VERSION ""

NS_ :

BS_:

BU_: WCM4 WCM3 WCM2 WCM VPM VLM VKM VICM VECM VDM VCU_RTOS_ETH VCU_ENTRY_ETH VCU_AGVM_ETH VCU UVM UPM TIM TEST_TOOL_1 TCP_ETH TCP TCM TCCM SRR_SRR_ETH SRR_SRR SRR_SLR_ETH SRR_SLR SRR_RR SRR_RF_ETH SRR_RF SRR_LR_CR SRR_LF_ETH SRR_LF SIB SDM SCL SBZA_R SBZA_L SBM SAM_RR SAM_RF SAM_LR SAM_LF SAM_BH SADS RadioLow_ETH RadioLow RSI_RTOS_ETH RSI RDCM PTM PLCM PFCM PDR_ETH PDR PCM PA ODS2 ODS NVM MTCM_R MTCM_L MSM_RR MSM_P MSM_LR MSM_D MSB2 MSB1 MRCM_R MRCM_L MFC LRR_RR_ETH LRR_LR_ETH LRR_CF_ETH LRR LRL_CF_ETH LIB_48V LIB1 IPC_INT IPC_GP IPC ICS_Info ICCM HVAC_FP_R HVAC_FP_F HUD_CAN HDLM FPI_RTOS_ETH FPI FOPM FCM_LC FCM EPSb EPS_1 EPSRAb EPSRAa EPS EOCM_HC_Superset EOCM_HCP2 EOCM ELM ECP_X1 ECP_S2 ECP_S ECP_MC ECP_H3 ECP_H2 ECP_H1 ECP_E ECM EBCM DMS DEFC DCM CSM_ETH CSM_AV CSM CGM_OTA_ETH CGM BSM_MH BSM_HEV BSM BCM ARS ARB APA AOS AMP ALC AHS AHL_AFL ADIMb ADIMa ACP2_MCU

BO_ 1345 PDU_9219: 8 CGM
 SG_ EVSECmndPwrLim : 7|16@0+ (0.1,0) [0|6553.5] "KW" CSM,IPC,IPC_INT,VCU
 SG_ HiVltgChrgReqdPwrLim : 23|16@0+ (0.1,0) [0|6553.5] "KW" CSM,IPC,IPC_INT,VCU
 SG_ EVSECmndPwrLimSts : 32|3@0+ (1,0) [0|3] "" CSM,IPC,IPC_INT,VCU
 SG_ EVSECmndPwrLimCpbltyPct : 39|7@0+ (1,0) [0|127] "%" CSM,IPC,IPC_INT,VCU
 SG_ DrSeltdOtltOfPwMdVirCtlNAlwdSts : 42|3@0+ (1,0) [0|6] "" VCU
 SG_ ShfFromNeutWrnIndOn : 43|1@0+ (1,0) [0|1] "" IPC,IPC_INT,VCU
 SG_ NeutCstdwnCertModeWrnIndOn : 44|1@0+ (1,0) [0|1] "" IPC,IPC_INT,VCU
 SG_ EVSECmndPwrLimAval : 45|1@0+ (1,0) [0|1] "" CSM,IPC,IPC_INT,VCU
 SG_ OnbrdOtlt1OprtlSts : 50|3@0+ (1,0) [0|4] "" VCU
 SG_ OffbrdOtltsOvrloadIndOn : 51|1@0+ (1,0) [0|1] "" VCU
 SG_ DrvrSeltdOtltOffPwrMdVirCtlAvl : 52|1@0+ (1,0) [0|1] "" VCU
 SG_ DrvrSeltdOtltOffPwMdVirCtlAllwd : 53|1@0+ (1,0) [0|1] "" VCU
 SG_ DrSeltdOtltOffPwMdVirCtlSeltnVl : 55|2@0+ (1,0) [0|2] "" VCU
 SG_ OtltsOffPwrMdTmrActv : 56|1@0+ (1,0) [0|1] "" VCU
 SG_ OnbrdOtltsOvrloadIndOn : 57|1@0+ (1,0) [0|1] "" VCU
 SG_ OnbrdOtlt3OprtlSts : 60|3@0+ (1,0) [0|4] "" VCU
 SG_ OnbrdOtlt2OprtlSts : 63|3@0+ (1,0) [0|4] "" VCU

BO_ 1294 PDU_9221: 8 CGM
 SG_ SecRowLtPsStBltRmOccpSts : 1|2@0+ (1,0) [0|2] "" TCP,VCU
 SG_ SecRowCntrPsStBltSts_Inv : 2|1@0+ (1,0) [0|1] "" TCP
 SG_ SecRowCntrPsStBltSts : 4|2@0+ (1,0) [0|2] "" TCP
 SG_ SecRowCntrPsStBltRmOccpSts_Inv : 5|1@0+ (1,0) [0|1] "" TCP,VCU
 SG_ SecRowCntrPsStBltRmOccpSts : 7|2@0+ (1,0) [0|2] "" TCP,VCU
 SG_ SecRowRtPsStBltSts : 8|2@0+ (1,0) [0|2] "" TCP
 SG_ SecRowRtPsStBltRmOccpSts_Inv : 9|1@0+ (1,0) [0|1] "" TCP,VCU
 SG_ SecRowRtPsStBltRmOccpSts : 11|2@0+ (1,0) [0|2] "" TCP,VCU
 SG_ SecRowLtPsStBltSts_Inv : 12|1@0+ (1,0) [0|1] "" TCP
 SG_ SecRowLtPsStBltSts : 14|2@0+ (1,0) [0|2] "" TCP
 SG_ SecRowLtPsStBltRmOccpSts_Inv : 15|1@0+ (1,0) [0|1] "" TCP,VCU
 SG_ ThrdRowCntrPsStBltSts_Inv : 16|1@0+ (1,0) [0|1] "" TCP
 SG_ ThrdRowCntrPsStBltSts : 18|2@0+ (1,0) [0|2] "" TCP
 SG_ ThrdRowCntrPsStBltRmOccpSts_Inv : 19|1@0+ (1,0) [0|1] "" TCP,VCU
 SG_ ThrdRowCntrPsStBltRmOccpSts : 21|2@0+ (1,0) [0|2] "" TCP,VCU
 SG_ SecRowRtPsStBltSts_Inv : 22|1@0+ (1,0) [0|1] "" TCP
 SG_ ThrdRowRtPsStBltRmOccpSts : 25|2@0+ (1,0) [0|2] "" TCP,VCU
 SG_ ThrdRowLtPsStBltSts_Inv : 26|1@0+ (1,0) [0|1] "" TCP
 SG_ ThrdRowLtPsStBltSts : 28|2@0+ (1,0) [0|2] "" TCP
 SG_ ThrdRowLtPsStBltRmOccpSts_Inv : 29|1@0+ (1,0) [0|1] "" TCP,VCU
 SG_ ThrdRowLtPsStBltRmOccpSts : 31|2@0+ (1,0) [0|2] "" TCP,VCU
 SG_ ThrdRowRtPsStBltSts_Inv : 36|1@0+ (1,0) [0|1] "" TCP
 SG_ ThrdRowRtPsStBltSts : 38|2@0+ (1,0) [0|2] "" TCP
 SG_ ThrdRowRtPsStBltRmOccpSts_Inv : 39|1@0+ (1,0) [0|1] "" TCP,VCU

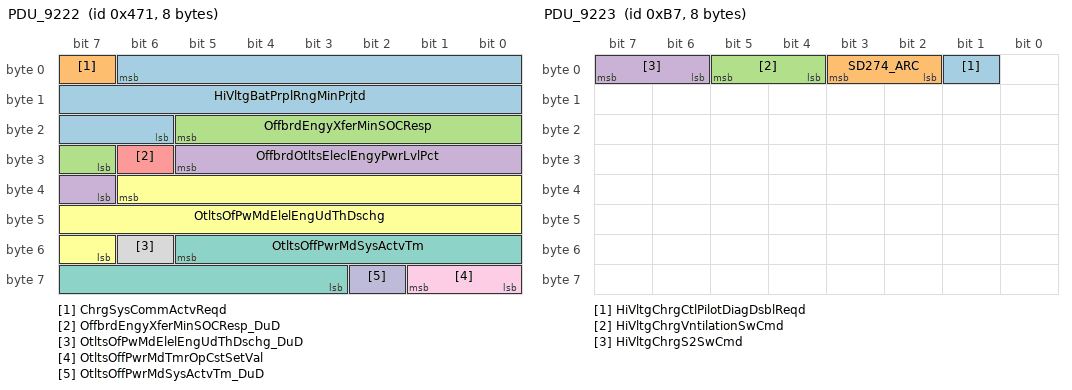
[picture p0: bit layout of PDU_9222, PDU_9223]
BO_ 1137 PDU_9222: 8 CGM
 SG_ HiVltgBatPrplRngMinPrjtd : 6|17@0+ (0.015625,0) [0|2047.98] "km" VCU
 SG_ ChrgSysCommActvReqd : 7|1@0+ (1,0) [0|1] "" PLCM
 SG_ OffbrdEngyXferMinSOCResp : 21|7@0+ (1,0) [0|127] "%" VCU
 SG_ OffbrdOtltsEleclEngyPwrLvlPct : 29|7@0+ (1,0) [0|127] "%" VCU
 SG_ OffbrdEngyXferMinSOCResp_DuD : 30|1@0+ (1,0) [0|1] "" VCU
 SG_ OtltsOfPwMdElelEngUdThDschg : 38|16@0+ (0.01,0) [0|655.35] "kWh" VCU
 SG_ OtltsOffPwrMdSysActvTm : 53|11@0+ (1,0) [0|2047] "min" VCU
 SG_ OtltsOfPwMdElelEngUdThDschg_DuD : 54|1@0+ (1,0) [0|1] "" VCU
 SG_ OtltsOffPwrMdTmrOpCstSetVal : 57|2@0+ (1,0) [0|2] "" VCU
 SG_ OtltsOffPwrMdSysActvTm_DuD : 58|1@0+ (1,0) [0|1] "" VCU

BO_ 183 PDU_9223: 8 CGM
 SG_ HiVltgChrgCtlPilotDiagDsblReqd : 1|1@0+ (1,0) [0|1] "" PLCM
 SG_ SD274_ARC : 3|2@0+ (1,0) [0|3] "" PLCM
 SG_ HiVltgChrgVntilationSwCmd : 5|2@0+ (1,0) [0|2] "" PLCM
 SG_ HiVltgChrgS2SwCmd : 7|2@0+ (1,0) [0|2] "" PLCM

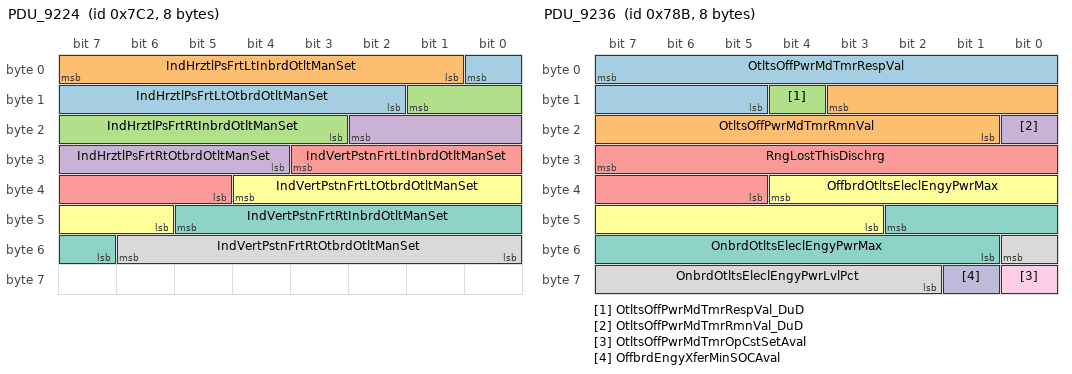
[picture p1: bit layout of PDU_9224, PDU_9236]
BO_ 1986 PDU_9224: 8 CGM
 SG_ IndHrztlPsFrtLtOtbrdOtltManSet : 0|7@0+ (1,0) [0|127] "" VCU
 SG_ IndHrztlPsFrtLtInbrdOtltManSet : 7|7@0+ (1,0) [0|127] "" VCU
 SG_ IndHrztlPsFrtRtInbrdOtltManSet : 9|7@0+ (1,0) [0|127] "" VCU
 SG_ IndHrztlPsFrtRtOtbrdOtltManSet : 18|7@0+ (1,0) [0|127] "" VCU
 SG_ IndVertPstnFrtLtInbrdOtltManSet : 27|7@0+ (1,0) [0|127] "" VCU
 SG_ IndVertPstnFrtLtOtbrdOtltManSet : 36|7@0+ (1,0) [0|127] "" VCU
 SG_ IndVertPstnFrtRtInbrdOtltManSet : 45|7@0+ (1,0) [0|127] "" VCU
 SG_ IndVertPstnFrtRtOtbrdOtltManSet : 54|7@0+ (1,0) [0|127] "" VCU

BO_ 1931 PDU_9236: 8 CGM
 SG_ OtltsOffPwrMdTmrRespVal : 7|11@0+ (1,0) [0|2047] "min" VCU
 SG_ OtltsOffPwrMdTmrRmnVal : 11|11@0+ (1,0) [0|2047] "min" VCU
 SG_ OtltsOffPwrMdTmrRespVal_DuD : 12|1@0+ (1,0) [0|1] "" VCU
 SG_ OtltsOffPwrMdTmrRmnVal_DuD : 16|1@0+ (1,0) [0|1] "" VCU
 SG_ RngLostThisDischrg : 31|11@0+ (1,0) [0|2047] "km" VCU
 SG_ OffbrdOtltsEleclEngyPwrMax : 36|10@0+ (0.1,0) [0|102.3] "kW" VCU
 SG_ OnbrdOtltsEleclEngyPwrMax : 42|10@0+ (0.1,0) [0|102.3] "kW" VCU
 SG_ OnbrdOtltsEleclEngyPwrLvlPct : 48|7@0+ (1,0) [0|127] "%" VCU
 SG_ OtltsOffPwrMdTmrOpCstSetAval : 56|1@0+ (1,0) [0|1] "" VCU
 SG_ OffbrdEngyXferMinSOCAval : 57|1@0+ (1,0) [0|1] "" VCU

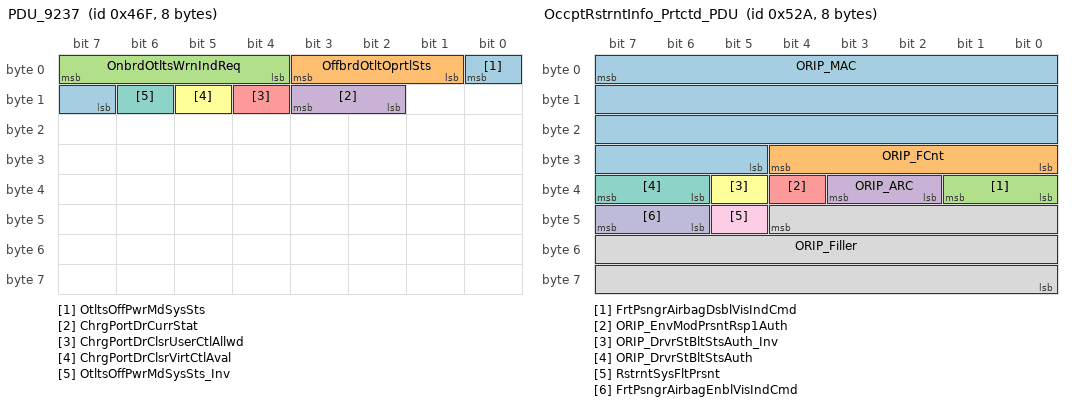
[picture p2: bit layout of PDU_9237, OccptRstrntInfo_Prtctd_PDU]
BO_ 1135 PDU_9237: 8 CGM
 SG_ OtltsOffPwrMdSysSts : 0|2@0+ (1,0) [0|3] "" VCU
 SG_ OffbrdOtltOprtlSts : 3|3@0+ (1,0) [0|4] "" VCU
 SG_ OnbrdOtltsWrnIndReq : 7|4@0+ (1,0) [0|8] "" VCU
 SG_ ChrgPortDrCurrStat : 11|2@0+ (1,0) [0|2] "" VCU
 SG_ ChrgPortDrClsrUserCtlAllwd : 12|1@0+ (1,0) [0|1] "" VCU
 SG_ ChrgPortDrClsrVirtCtlAval : 13|1@0+ (1,0) [0|1] "" VCU
 SG_ OtltsOffPwrMdSysSts_Inv : 14|1@0+ (1,0) [0|1] "" VCU

BO_ 1056 PDU_9259: 8 CGM
 SG_ CntnsCrnkgDsbldIndOn : 7|1@0+ (1,0) [0|1] "" VCU

BO_ 963 NodeStatus_CAN5_PDU01: 8 CGM
 SG_ NodeStsADIMb_CAN_9_LcFA : 0|1@0+ (1,0) [0|1] "" AMP,FPI,HVAC_FP_F,HVAC_FP_R,ICS_Info,PDR,MFC,PLCM,RSI,RadioLow,TCP,VKM,CSM,CSM_AV,IPC,IPC_INT,VCU,WCM,WCM2,WCM3,WCM4
 SG_ NodeStsADIMb_CAN_3_LcFA : 1|1@0+ (1,0) [0|1] "" AMP,FPI,HVAC_FP_F,HVAC_FP_R,ICS_Info,PDR,MFC,PLCM,RSI,RadioLow,TCP,VKM,CSM,CSM_AV,IPC,IPC_INT,VCU,WCM,WCM2,WCM3,WCM4
 SG_ NodeStsADIMb_CAN_2_LcFA : 2|1@0+ (1,0) [0|1] "" AMP,FPI,HVAC_FP_F,HVAC_FP_R,ICS_Info,PDR,MFC,PLCM,RSI,RadioLow,TCP,VKM,CSM,CSM_AV,IPC,IPC_INT,VCU,WCM,WCM2,WCM3,WCM4
 SG_ NodeStsADIMb_CAN_10_LcFA : 3|1@0+ (1,0) [0|1] "" AMP,FPI,HVAC_FP_F,HVAC_FP_R,ICS_Info,PDR,MFC,PLCM,RSI,RadioLow,TCP,VKM,CSM,CSM_AV,IPC,IPC_INT,VCU,WCM,WCM2,WCM3,WCM4
 SG_ NodeStsADIMa_CAN_9_LcFA : 4|1@0+ (1,0) [0|1] "" AMP,FPI,HVAC_FP_F,HVAC_FP_R,ICS_Info,PDR,MFC,PLCM,RSI,RadioLow,TCP,VKM,CSM,CSM_AV,IPC,IPC_INT,VCU,WCM,WCM2,WCM3,WCM4
 SG_ NodeStsADIMa_CAN_3_LcFA : 5|1@0+ (1,0) [0|1] "" AMP,FPI,HVAC_FP_F,HVAC_FP_R,ICS_Info,PDR,MFC,PLCM,RSI,RadioLow,TCP,VKM,CSM,CSM_AV,IPC,IPC_INT,VCU,WCM,WCM2,WCM3,WCM4
 SG_ NodeStsADIMa_CAN_2_LcFA : 6|1@0+ (1,0) [0|1] "" AMP,FPI,HVAC_FP_F,HVAC_FP_R,ICS_Info,PDR,MFC,PLCM,RSI,RadioLow,TCP,VKM,CSM,CSM_AV,IPC,IPC_INT,VCU,WCM,WCM2,WCM3,WCM4
 SG_ NodeStsADIMa_CAN_10_LcFA : 7|1@0+ (1,0) [0|1] "" AMP,FPI,HVAC_FP_F,HVAC_FP_R,ICS_Info,PDR,MFC,PLCM,RSI,RadioLow,TCP,VKM,CSM,CSM_AV,IPC,IPC_INT,VCU,WCM,WCM2,WCM3,WCM4
 SG_ NodeStsAPA_CAN_1_LcFA : 8|1@0+ (1,0) [0|1] "" AMP,FPI,HVAC_FP_F,HVAC_FP_R,ICS_Info,PDR,MFC,PLCM,RSI,RadioLow,TCP,VKM,CSM,CSM_AV,IPC,IPC_INT,VCU,WCM,WCM2,WCM3,WCM4
 SG_ NodeStsAOS_LcFA : 10|1@0+ (1,0) [0|1] "" AMP,FPI,HVAC_FP_F,HVAC_FP_R,ICS_Info,PDR,MFC,PLCM,RSI,RadioLow,TCP,VKM,CSM,CSM_AV,IPC,IPC_INT,VCU,WCM,WCM2,WCM3,WCM4
 SG_ NodeStsAMP_LcFA : 11|1@0+ (1,0) [0|1] "" FPI,HVAC_FP_F,HVAC_FP_R,ICS_Info,PDR,MFC,PLCM,RSI,RadioLow,TCP,VKM,CSM,CSM_AV,IPC,IPC_INT,VCU,WCM,WCM2,WCM3,WCM4
 SG_ NodeStsALC_LcFA : 12|1@0+ (1,0) [0|1] "" AMP,FPI,HVAC_FP_F,HVAC_FP_R,ICS_Info,PDR,MFC,PLCM,RSI,RadioLow,TCP,VKM,CSM,CSM_AV,IPC,IPC_INT,VCU,WCM,WCM2,WCM3,WCM4
 SG_ NodeStsAHS_LcFA : 13|1@0+ (1,0) [0|1] "" AMP,FPI,HVAC_FP_F,HVAC_FP_R,ICS_Info,PDR,MFC,PLCM,RSI,RadioLow,TCP,VKM,CSM,CSM_AV,IPC,IPC_INT,VCU,WCM,WCM2,WCM3,WCM4
 SG_ NodeStsAHL_AFL_CAN_2_LcFA : 14|1@0+ (1,0) [0|1] "" AMP,FPI,HVAC_FP_F,HVAC_FP_R,ICS_Info,PDR,MFC,PLCM,RSI,RadioLow,TCP,VKM,CSM,CSM_AV,IPC,IPC_INT,VCU,WCM,WCM2,WCM3,WCM4
 SG_ NodeStsBSM_MH_LcFA : 17|1@0+ (1,0) [0|1] "" AMP,FPI,HVAC_FP_F,HVAC_FP_R,ICS_Info,PDR,MFC,PLCM,RSI,RadioLow,TCP,VKM,CSM,CSM_AV,IPC,IPC_INT,VCU,WCM,WCM2,WCM3,WCM4
 SG_ NodeStsBSM_CAN_3_LcFA : 18|1@0+ (1,0) [0|1] "" AMP,FPI,HVAC_FP_F,HVAC_FP_R,ICS_Info,PDR,MFC,PLCM,RSI,RadioLow,TCP,VKM,CSM,CSM_AV,IPC,IPC_INT,VCU,WCM,WCM2,WCM3,WCM4
 SG_ NodeStsBSM_CAN_2_LcFA : 19|1@0+ (1,0) [0|1] "" AMP,FPI,HVAC_FP_F,HVAC_FP_R,ICS_Info,PDR,MFC,PLCM,RSI,RadioLow,TCP,VKM,CSM,CSM_AV,IPC,IPC_INT,VCU,WCM,WCM2,WCM3,WCM4
 SG_ NodeStsBCM_LcFA : 20|1@0+ (1,0) [0|1] "" AMP,FPI,HVAC_FP_F,HVAC_FP_R,ICS_Info,PDR,MFC,PLCM,RSI,RadioLow,TCP,VKM,CSM,CSM_AV,IPC,IPC_INT,VCU,WCM,WCM2,WCM3,WCM4
 SG_ NodeStsARS_LcFA : 21|1@0+ (1,0) [0|1] "" AMP,FPI,HVAC_FP_F,HVAC_FP_R,ICS_Info,PDR,MFC,PLCM,RSI,RadioLow,TCP,VKM,CSM,CSM_AV,IPC,IPC_INT,VCU,WCM,WCM2,WCM3,WCM4
 SG_ NodeStsARB_LcFA : 22|1@0+ (1,0) [0|1] "" AMP,FPI,HVAC_FP_F,HVAC_FP_R,ICS_Info,PDR,MFC,PLCM,RSI,RadioLow,TCP,VKM,CSM,CSM_AV,IPC,IPC_INT,VCU,WCM,WCM2,WCM3,WCM4
 SG_ NodeStsAPA_CAN_2_LcFA : 23|1@0+ (1,0) [0|1] "" AMP,FPI,HVAC_FP_F,HVAC_FP_R,ICS_Info,PDR,MFC,PLCM,RSI,RadioLow,TCP,VKM,CSM,CSM_AV,IPC,IPC_INT,VCU,WCM,WCM2,WCM3,WCM4
 SG_ NodeStsEBCM_AV_CAN_2_LcFA : 24|1@0+ (1,0) [0|1] "" AMP,FPI,HVAC_FP_F,HVAC_FP_R,ICS_Info,PDR,MFC,PLCM,RSI,RadioLow,TCP,VKM,CSM,CSM_AV,IPC,IPC_INT,VCU,WCM,WCM2,WCM3,WCM4
 SG_ NodeStsDMS_LcFA : 25|1@0+ (1,0) [0|1] "" AMP,FPI,HVAC_FP_F,HVAC_FP_R,ICS_Info,PDR,MFC,PLCM,RSI,RadioLow,TCP,VKM,CSM,CSM_AV,IPC,IPC_INT,VCU,WCM,WCM2,WCM3,WCM4
 SG_ NodeStsDEFC_LcFA : 26|1@0+ (1,0) [0|1] "" AMP,FPI,HVAC_FP_F,HVAC_FP_R,ICS_Info,PDR,MFC,PLCM,RSI,RadioLow,TCP,VKM,CSM,CSM_AV,IPC,IPC_INT,VCU,WCM,WCM2,WCM3,WCM4
 SG_ NodeStsDCM_LcFA : 27|1@0+ (1,0) [0|1] "" AMP,FPI,HVAC_FP_F,HVAC_FP_R,ICS_Info,PDR,MFC,PLCM,RSI,RadioLow,TCP,VKM,CSM,CSM_AV,IPC,IPC_INT,VCU,WCM,WCM2,WCM3,WCM4
 SG_ NodeStsCSM_CAN_5_LcFA : 28|1@0+ (1,0) [0|1] "" AMP,FPI,HVAC_FP_F,HVAC_FP_R,ICS_Info,PDR,MFC,PLCM,RSI,RadioLow,TCP,VKM,CSM_AV,IPC,IPC_INT,VCU,WCM,WCM2,WCM3,WCM4
 SG_ NodeStsECP_E_CAN_9_LcFA : 32|1@0+ (1,0) [0|1] "" AMP,FPI,HVAC_FP_F,HVAC_FP_R,ICS_Info,PDR,MFC,PLCM,RSI,RadioLow,TCP,VKM,CSM,CSM_AV,IPC,IPC_INT,VCU,WCM,WCM2,WCM3,WCM4
 SG_ NodeStsECP_E_CAN_2_LcFA : 33|1@0+ (1,0) [0|1] "" AMP,FPI,HVAC_FP_F,HVAC_FP_R,ICS_Info,PDR,MFC,PLCM,RSI,RadioLow,TCP,VKM,CSM,CSM_AV,IPC,IPC_INT,VCU,WCM,WCM2,WCM3,WCM4
 SG_ NodeStsECM_CAN_3_LcFA : 34|1@0+ (1,0) [0|1] "" AMP,FPI,HVAC_FP_F,HVAC_FP_R,ICS_Info,PDR,MFC,PLCM,RSI,RadioLow,TCP,VKM,CSM,CSM_AV,IPC,IPC_INT,VCU,WCM,WCM2,WCM3,WCM4
 SG_ NodeStsECM_CAN_2_LcFA : 35|1@0+ (1,0) [0|1] "" AMP,FPI,HVAC_FP_F,HVAC_FP_R,ICS_Info,PDR,MFC,PLCM,RSI,RadioLow,TCP,VKM,CSM,CSM_AV,IPC,IPC_INT,VCU,WCM,WCM2,WCM3,WCM4
 SG_ NodeStsEBCM_CAN_3_LcFA : 37|1@0+ (1,0) [0|1] "" AMP,FPI,HVAC_FP_F,HVAC_FP_R,ICS_Info,PDR,MFC,PLCM,RSI,RadioLow,TCP,VKM,CSM,CSM_AV,IPC,IPC_INT,VCU,WCM,WCM2,WCM3,WCM4
 SG_ NodeStsEBCM_CAN_2_LcFA : 38|1@0+ (1,0) [0|1] "" AMP,FPI,HVAC_FP_F,HVAC_FP_R,ICS_Info,PDR,MFC,PLCM,RSI,RadioLow,TCP,VKM,CSM,CSM_AV,IPC,IPC_INT,VCU,WCM,WCM2,WCM3,WCM4
 SG_ NodeStsEBCM_AV_CAN_3_LcFA : 39|1@0+ (1,0) [0|1] "" AMP,FPI,HVAC_FP_F,HVAC_FP_R,ICS_Info,PDR,MFC,PLCM,RSI,RadioLow,TCP,VKM,CSM,CSM_AV,IPC,IPC_INT,VCU,WCM,WCM2,WCM3,WCM4
 SG_ NodeStsEOCM_CAN_3_LcFA : 40|1@0+ (1,0) [0|1] "" AMP,FPI,HVAC_FP_F,HVAC_FP_R,ICS_Info,PDR,MFC,PLCM,RSI,RadioLow,TCP,VKM,CSM,CSM_AV,IPC,IPC_INT,VCU,WCM,WCM2,WCM3,WCM4
 SG_ NodeStsEOCM_CAN_2_LcFA : 41|1@0+ (1,0) [0|1] "" AMP,FPI,HVAC_FP_F,HVAC_FP_R,ICS_Info,PDR,MFC,PLCM,RSI,RadioLow,TCP,VKM,CSM,CSM_AV,IPC,IPC_INT,VCU,WCM,WCM2,WCM3,WCM4
 SG_ NodeStsELM_LcFA : 42|1@0+ (1,0) [0|1] "" AMP,FPI,HVAC_FP_F,HVAC_FP_R,ICS_Info,PDR,MFC,PLCM,RSI,RadioLow,TCP,VKM,CSM,CSM_AV,IPC,IPC_INT,VCU,WCM,WCM2,WCM3,WCM4
 SG_ NodeStsECP_X1_CAN_3_LcFA : 43|1@0+ (1,0) [0|1] "" AMP,FPI,HVAC_FP_F,HVAC_FP_R,ICS_Info,PDR,MFC,PLCM,RSI,RadioLow,TCP,VKM,CSM,CSM_AV,IPC,IPC_INT,VCU,WCM,WCM2,WCM3,WCM4
 SG_ NodeStsECP_X1_CAN_2_LcFA : 44|1@0+ (1,0) [0|1] "" AMP,FPI,HVAC_FP_F,HVAC_FP_R,ICS_Info,PDR,MFC,PLCM,RSI,RadioLow,TCP,VKM,CSM,CSM_AV,IPC,IPC_INT,VCU,WCM,WCM2,WCM3,WCM4
 SG_ NodeStsECP_S_CAN_9_LcFA : 45|1@0+ (1,0) [0|1] "" AMP,FPI,HVAC_FP_F,HVAC_FP_R,ICS_Info,PDR,MFC,PLCM,RSI,RadioLow,TCP,VKM,CSM,CSM_AV,IPC,IPC_INT,VCU,WCM,WCM2,WCM3,WCM4
 SG_ NodeStsECP_S_CAN_2_LcFA : 46|1@0+ (1,0) [0|1] "" AMP,FPI,HVAC_FP_F,HVAC_FP_R,ICS_Info,PDR,MFC,PLCM,RSI,RadioLow,TCP,VKM,CSM,CSM_AV,IPC,IPC_INT,VCU,WCM,WCM2,WCM3,WCM4
 SG_ NodeStsECP_MC_LcFA : 47|1@0+ (1,0) [0|1] "" AMP,FPI,HVAC_FP_F,HVAC_FP_R,ICS_Info,PDR,MFC,PLCM,RSI,RadioLow,TCP,VKM,CSM,CSM_AV,IPC,IPC_INT,VCU,WCM,WCM2,WCM3,WCM4
 SG_ NodeStsEPSRAa_LcFA : 48|1@0+ (1,0) [0|1] "" AMP,FPI,HVAC_FP_F,HVAC_FP_R,ICS_Info,PDR,MFC,PLCM,RSI,RadioLow,TCP,VKM,CSM,CSM_AV,IPC,IPC_INT,VCU,WCM,WCM2,WCM3,WCM4
 SG_ NodeStsEPS_LcFA : 49|1@0+ (1,0) [0|1] "" AMP,FPI,HVAC_FP_F,HVAC_FP_R,ICS_Info,PDR,MFC,PLCM,RSI,RadioLow,TCP,VKM,CSM,CSM_AV,IPC,IPC_INT,VCU,WCM,WCM2,WCM3,WCM4
 SG_ NodeStsEPS_1_LcFA : 50|1@0+ (1,0) [0|1] "" AMP,FPI,HVAC_FP_F,HVAC_FP_R,ICS_Info,PDR,MFC,PLCM,RSI,RadioLow,TCP,VKM,CSM,CSM_AV,IPC,IPC_INT,VCU,WCM,WCM2,WCM3,WCM4
 SG_ NodeStsEOCM_HCP2_LcFA : 51|1@0+ (1,0) [0|1] "" AMP,FPI,HVAC_FP_F,HVAC_FP_R,ICS_Info,PDR,MFC,PLCM,RSI,RadioLow,TCP,VKM,CSM,CSM_AV,IPC,IPC_INT,VCU,WCM,WCM2,WCM3,WCM4
 SG_ NodeStsEOCM_HCP1_CAN_8_LcFA : 52|1@0+ (1,0) [0|1] "" AMP,FPI,HVAC_FP_F,HVAC_FP_R,ICS_Info,PDR,MFC,PLCM,RSI,RadioLow,TCP,VKM,CSM,CSM_AV,IPC,IPC_INT,VCU,WCM,WCM2,WCM3,WCM4
 SG_ NodeStsEOCM_HCP1_CAN_3_LcFA : 53|1@0+ (1,0) [0|1] "" AMP,FPI,HVAC_FP_F,HVAC_FP_R,ICS_Info,PDR,MFC,PLCM,RSI,RadioLow,TCP,VKM,CSM,CSM_AV,IPC,IPC_INT,VCU,WCM,WCM2,WCM3,WCM4
 SG_ NodeStsEOCM_HCP1_CAN_2_LcFA : 54|1@0+ (1,0) [0|1] "" AMP,FPI,HVAC_FP_F,HVAC_FP_R,ICS_Info,PDR,MFC,PLCM,RSI,RadioLow,TCP,VKM,CSM,CSM_AV,IPC,IPC_INT,VCU,WCM,WCM2,WCM3,WCM4
 SG_ NodeStsEOCM_CAN_8_LcFA : 55|1@0+ (1,0) [0|1] "" AMP,FPI,HVAC_FP_F,HVAC_FP_R,ICS_Info,PDR,MFC,PLCM,RSI,RadioLow,TCP,VKM,CSM,CSM_AV,IPC,IPC_INT,VCU,WCM,WCM2,WCM3,WCM4
 SG_ NodeStsHVAC_FP_F_LcFA : 56|1@0+ (1,0) [0|1] "" AMP,FPI,HVAC_FP_R,ICS_Info,PDR,MFC,PLCM,RSI,RadioLow,TCP,VKM,CSM,CSM_AV,IPC,IPC_INT,VCU,WCM,WCM2,WCM3,WCM4
 SG_ NodeStsHUD_CAN_LcFA : 57|1@0+ (1,0) [0|1] "" AMP,FPI,HVAC_FP_F,HVAC_FP_R,ICS_Info,PDR,MFC,PLCM,RSI,RadioLow,TCP,VKM,CSM,CSM_AV,IPC,IPC_INT,VCU,WCM,WCM2,WCM3,WCM4
 SG_ NodeStsHDLM_LcFA : 58|1@0+ (1,0) [0|1] "" AMP,FPI,HVAC_FP_F,HVAC_FP_R,ICS_Info,PDR,MFC,PLCM,RSI,RadioLow,TCP,VKM,CSM,CSM_AV,IPC,IPC_INT,VCU,WCM,WCM2,WCM3,WCM4
 SG_ NodeStsFOPM_CAN_3_LcFA : 59|1@0+ (1,0) [0|1] "" AMP,FPI,HVAC_FP_F,HVAC_FP_R,ICS_Info,PDR,MFC,PLCM,RSI,RadioLow,TCP,VKM,CSM,CSM_AV,IPC,IPC_INT,VCU,WCM,WCM2,WCM3,WCM4
 SG_ NodeStsFOPM_CAN_2_LcFA : 60|1@0+ (1,0) [0|1] "" AMP,FPI,HVAC_FP_F,HVAC_FP_R,ICS_Info,PDR,MFC,PLCM,RSI,RadioLow,TCP,VKM,CSM,CSM_AV,IPC,IPC_INT,VCU,WCM,WCM2,WCM3,WCM4
 SG_ NodeStsFCM_LcFA : 61|1@0+ (1,0) [0|1] "" AMP,FPI,HVAC_FP_F,HVAC_FP_R,ICS_Info,PDR,MFC,PLCM,RSI,RadioLow,TCP,VKM,CSM,CSM_AV,IPC,IPC_INT,VCU,WCM,WCM2,WCM3,WCM4
 SG_ NodeStsFCM_LC_LcFA : 62|1@0+ (1,0) [0|1] "" AMP,FPI,HVAC_FP_F,HVAC_FP_R,ICS_Info,PDR,MFC,PLCM,RSI,RadioLow,TCP,VKM,CSM,CSM_AV,IPC,IPC_INT,VCU,WCM,WCM2,WCM3,WCM4
 SG_ NodeStsEPSRAb_LcFA : 63|1@0+ (1,0) [0|1] "" AMP,FPI,HVAC_FP_F,HVAC_FP_R,ICS_Info,PDR,MFC,PLCM,RSI,RadioLow,TCP,VKM,CSM,CSM_AV,IPC,IPC_INT,VCU,WCM,WCM2,WCM3,WCM4

BO_ 964 NodeStatus_CAN5_PDU02: 8 CGM
 SG_ NodeStsMFC_LcFA : 0|1@0+ (1,0) [0|1] "" AMP,FPI,HVAC_FP_F,HVAC_FP_R,ICS_Info,PDR,PLCM,RSI,RadioLow,TCP,VKM,CSM,CSM_AV,IPC,IPC_INT,VCU,WCM,WCM2,WCM3,WCM4
 SG_ NodeStsLRR_LcFA : 1|1@0+ (1,0) [0|1] "" AMP,FPI,HVAC_FP_F,HVAC_FP_R,ICS_Info,PDR,MFC,PLCM,RSI,RadioLow,TCP,VKM,CSM,CSM_AV,IPC,IPC_INT,VCU,WCM,WCM2,WCM3,WCM4
 SG_ NodeStsLIB1_LcFA : 3|1@0+ (1,0) [0|1] "" AMP,FPI,HVAC_FP_F,HVAC_FP_R,ICS_Info,PDR,MFC,PLCM,RSI,RadioLow,TCP,VKM,CSM,CSM_AV,IPC,IPC_INT,VCU,WCM,WCM2,WCM3,WCM4
 SG_ NodeStsIPC_CAN_5_LcFA : 4|1@0+ (1,0) [0|1] "" AMP,FPI,HVAC_FP_F,HVAC_FP_R,ICS_Info,PDR,MFC,PLCM,RSI,RadioLow,TCP,VKM,CSM,CSM_AV,IPC,IPC_INT,VCU,WCM,WCM2,WCM3,WCM4
 SG_ NodeStsICS_Info_LcFA : 5|1@0+ (1,0) [0|1] "" AMP,FPI,HVAC_FP_F,HVAC_FP_R,PDR,MFC,PLCM,RSI,RadioLow,TCP,VKM,CSM,CSM_AV,IPC,IPC_INT,VCU,WCM,WCM2,WCM3,WCM4
 SG_ NodeStsICCM_CAN_3_LcFA : 6|1@0+ (1,0) [0|1] "" AMP,FPI,HVAC_FP_F,HVAC_FP_R,ICS_Info,PDR,MFC,PLCM,RSI,RadioLow,TCP,VKM,CSM,CSM_AV,IPC,IPC_INT,VCU,WCM,WCM2,WCM3,WCM4
 SG_ NodeStsHVAC_FP_R_LcFA : 7|1@0+ (1,0) [0|1] "" AMP,FPI,HVAC_FP_F,ICS_Info,PDR,MFC,PLCM,RSI,RadioLow,TCP,VKM,CSM,CSM_AV,IPC,IPC_INT,VCU,WCM,WCM2,WCM3,WCM4
 SG_ NodeStsMSM_RR_LcFA : 8|1@0+ (1,0) [0|1] "" AMP,FPI,HVAC_FP_F,HVAC_FP_R,ICS_Info,PDR,MFC,PLCM,RSI,RadioLow,TCP,VKM,CSM,CSM_AV,IPC,IPC_INT,VCU,WCM,WCM2,WCM3,WCM4
 SG_ NodeStsMSM_P_LcFA : 9|1@0+ (1,0) [0|1] "" AMP,FPI,HVAC_FP_F,HVAC_FP_R,ICS_Info,PDR,MFC,PLCM,RSI,RadioLow,TCP,VKM,CSM,CSM_AV,IPC,IPC_INT,VCU,WCM,WCM2,WCM3,WCM4
 SG_ NodeStsMSM_LR_LcFA : 10|1@0+ (1,0) [0|1] "" AMP,FPI,HVAC_FP_F,HVAC_FP_R,ICS_Info,PDR,MFC,PLCM,RSI,RadioLow,TCP,VKM,CSM,CSM_AV,IPC,IPC_INT,VCU,WCM,WCM2,WCM3,WCM4
 SG_ NodeStsMSM_D_LcFA : 11|1@0+ (1,0) [0|1] "" AMP,FPI,HVAC_FP_F,HVAC_FP_R,ICS_Info,PDR,MFC,PLCM,RSI,RadioLow,TCP,VKM,CSM,CSM_AV,IPC,IPC_INT,VCU,WCM,WCM2,WCM3,WCM4
 SG_ NodeStsMSB2_LcFA : 12|1@0+ (1,0) [0|1] "" AMP,FPI,HVAC_FP_F,HVAC_FP_R,ICS_Info,PDR,MFC,PLCM,RSI,RadioLow,TCP,VKM,CSM,CSM_AV,IPC,IPC_INT,VCU,WCM,WCM2,WCM3,WCM4
 SG_ NodeStsMSB1_LcFA : 13|1@0+ (1,0) [0|1] "" AMP,FPI,HVAC_FP_F,HVAC_FP_R,ICS_Info,PDR,MFC,PLCM,RSI,RadioLow,TCP,VKM,CSM,CSM_AV,IPC,IPC_INT,VCU,WCM,WCM2,WCM3,WCM4
 SG_ NodeStsMRCM_R_LcFA : 14|1@0+ (1,0) [0|1] "" AMP,FPI,HVAC_FP_F,HVAC_FP_R,ICS_Info,PDR,MFC,PLCM,RSI,RadioLow,TCP,VKM,CSM,CSM_AV,IPC,IPC_INT,VCU,WCM,WCM2,WCM3,WCM4
 SG_ NodeStsMRCM_L_LcFA : 15|1@0+ (1,0) [0|1] "" AMP,FPI,HVAC_FP_F,HVAC_FP_R,ICS_Info,PDR,MFC,PLCM,RSI,RadioLow,TCP,VKM,CSM,CSM_AV,IPC,IPC_INT,VCU,WCM,WCM2,WCM3,WCM4
 SG_ NodeStsRDCM_LcFA : 16|1@0+ (1,0) [0|1] "" AMP,FPI,HVAC_FP_F,HVAC_FP_R,ICS_Info,PDR,MFC,PLCM,RSI,RadioLow,TCP,VKM,CSM,CSM_AV,IPC,IPC_INT,VCU,WCM,WCM2,WCM3,WCM4
 SG_ NodeStsRadioLow_LcFA : 17|1@0+ (1,0) [0|1] "" AMP,FPI,HVAC_FP_F,HVAC_FP_R,ICS_Info,PDR,MFC,PLCM,RSI,TCP,VKM,CSM,CSM_AV,IPC,IPC_INT,VCU,WCM,WCM2,WCM3,WCM4
 SG_ NodeStsPTM_LcFA : 18|1@0+ (1,0) [0|1] "" AMP,FPI,HVAC_FP_F,HVAC_FP_R,ICS_Info,PDR,MFC,PLCM,RSI,RadioLow,TCP,VKM,CSM,CSM_AV,IPC,IPC_INT,VCU,WCM,WCM2,WCM3,WCM4
 SG_ NodeStsPDR_LcFA : 19|1@0+ (1,0) [0|1] "" AMP,FPI,HVAC_FP_F,HVAC_FP_R,ICS_Info,MFC,PLCM,RSI,RadioLow,TCP,VKM,CSM,CSM_AV,IPC,IPC_INT,VCU,WCM,WCM2,WCM3,WCM4
 SG_ NodeStsPA_LcFA : 20|1@0+ (1,0) [0|1] "" AMP,FPI,HVAC_FP_F,HVAC_FP_R,ICS_Info,PDR,MFC,PLCM,RSI,RadioLow,TCP,VKM,CSM,CSM_AV,IPC,IPC_INT,VCU,WCM,WCM2,WCM3,WCM4
 SG_ NodeStsNVM_LcFA : 21|1@0+ (1,0) [0|1] "" AMP,FPI,HVAC_FP_F,HVAC_FP_R,ICS_Info,PDR,MFC,PLCM,RSI,RadioLow,TCP,VKM,CSM,CSM_AV,IPC,IPC_INT,VCU,WCM,WCM2,WCM3,WCM4
 SG_ NodeStsMTCM_R_LcFA : 22|1@0+ (1,0) [0|1] "" AMP,FPI,HVAC_FP_F,HVAC_FP_R,ICS_Info,PDR,MFC,PLCM,RSI,RadioLow,TCP,VKM,CSM,CSM_AV,IPC,IPC_INT,VCU,WCM,WCM2,WCM3,WCM4
 SG_ NodeStsMTCM_L_LcFA : 23|1@0+ (1,0) [0|1] "" AMP,FPI,HVAC_FP_F,HVAC_FP_R,ICS_Info,PDR,MFC,PLCM,RSI,RadioLow,TCP,VKM,CSM,CSM_AV,IPC,IPC_INT,VCU,WCM,WCM2,WCM3,WCM4
 SG_ NodeStsSBM_CAN_3_LcFA : 25|1@0+ (1,0) [0|1] "" AMP,FPI,HVAC_FP_F,HVAC_FP_R,ICS_Info,PDR,MFC,PLCM,RSI,RadioLow,TCP,VKM,CSM,CSM_AV,IPC,IPC_INT,VCU,WCM,WCM2,WCM3,WCM4
 SG_ NodeStsSAM_RR_LcFA : 26|1@0+ (1,0) [0|1] "" AMP,FPI,HVAC_FP_F,HVAC_FP_R,ICS_Info,PDR,MFC,PLCM,RSI,RadioLow,TCP,VKM,CSM,CSM_AV,IPC,IPC_INT,VCU,WCM,WCM2,WCM3,WCM4
 SG_ NodeStsSAM_RF_LcFA : 27|1@0+ (1,0) [0|1] "" AMP,FPI,HVAC_FP_F,HVAC_FP_R,ICS_Info,PDR,MFC,PLCM,RSI,RadioLow,TCP,VKM,CSM,CSM_AV,IPC,IPC_INT,VCU,WCM,WCM2,WCM3,WCM4
 SG_ NodeStsSAM_LR_LcFA : 28|1@0+ (1,0) [0|1] "" AMP,FPI,HVAC_FP_F,HVAC_FP_R,ICS_Info,PDR,MFC,PLCM,RSI,RadioLow,TCP,VKM,CSM,CSM_AV,IPC,IPC_INT,VCU,WCM,WCM2,WCM3,WCM4
 SG_ NodeStsSAM_LF_LcFA : 29|1@0+ (1,0) [0|1] "" AMP,FPI,HVAC_FP_F,HVAC_FP_R,ICS_Info,PDR,MFC,PLCM,RSI,RadioLow,TCP,VKM,CSM,CSM_AV,IPC,IPC_INT,VCU,WCM,WCM2,WCM3,WCM4
 SG_ NodeStsSADS_LcFA : 30|1@0+ (1,0) [0|1] "" AMP,FPI,HVAC_FP_F,HVAC_FP_R,ICS_Info,PDR,MFC,PLCM,RSI,RadioLow,TCP,VKM,CSM,CSM_AV,IPC,IPC_INT,VCU,WCM,WCM2,WCM3,WCM4
 SG_ NodeStsSRR_RF_LcFA : 32|1@0+ (1,0) [0|1] "" AMP,FPI,HVAC_FP_F,HVAC_FP_R,ICS_Info,PDR,MFC,PLCM,RSI,RadioLow,TCP,VKM,CSM,CSM_AV,IPC,IPC_INT,VCU,WCM,WCM2,WCM3,WCM4
 SG_ NodeStsSRR_LR_CR_LcFA : 33|1@0+ (1,0) [0|1] "" AMP,FPI,HVAC_FP_F,HVAC_FP_R,ICS_Info,PDR,MFC,PLCM,RSI,RadioLow,TCP,VKM,CSM,CSM_AV,IPC,IPC_INT,VCU,WCM,WCM2,WCM3,WCM4
 SG_ NodeStsSRR_LF_LcFA : 34|1@0+ (1,0) [0|1] "" AMP,FPI,HVAC_FP_F,HVAC_FP_R,ICS_Info,PDR,MFC,PLCM,RSI,RadioLow,TCP,VKM,CSM,CSM_AV,IPC,IPC_INT,VCU,WCM,WCM2,WCM3,WCM4
 SG_ NodeStsSIB_LcFA : 35|1@0+ (1,0) [0|1] "" AMP,FPI,HVAC_FP_F,HVAC_FP_R,ICS_Info,PDR,MFC,PLCM,RSI,RadioLow,TCP,VKM,CSM,CSM_AV,IPC,IPC_INT,VCU,WCM,WCM2,WCM3,WCM4
 SG_ NodeStsSDM_LcFA : 36|1@0+ (1,0) [0|1] "" AMP,FPI,HVAC_FP_F,HVAC_FP_R,ICS_Info,PDR,MFC,PLCM,RSI,RadioLow,TCP,VKM,CSM,CSM_AV,IPC,IPC_INT,VCU,WCM,WCM2,WCM3,WCM4
 SG_ NodeStsSCL_LcFA : 37|1@0+ (1,0) [0|1] "" AMP,FPI,HVAC_FP_F,HVAC_FP_R,ICS_Info,PDR,MFC,PLCM,RSI,RadioLow,TCP,VKM,CSM,CSM_AV,IPC,IPC_INT,VCU,WCM,WCM2,WCM3,WCM4
 SG_ NodeStsSBZA_R_LcFA : 38|1@0+ (1,0) [0|1] "" AMP,FPI,HVAC_FP_F,HVAC_FP_R,ICS_Info,PDR,MFC,PLCM,RSI,RadioLow,TCP,VKM,CSM,CSM_AV,IPC,IPC_INT,VCU,WCM,WCM2,WCM3,WCM4
 SG_ NodeStsSBZA_L_LcFA : 39|1@0+ (1,0) [0|1] "" AMP,FPI,HVAC_FP_F,HVAC_FP_R,ICS_Info,PDR,MFC,PLCM,RSI,RadioLow,TCP,VKM,CSM,CSM_AV,IPC,IPC_INT,VCU,WCM,WCM2,WCM3,WCM4
 SG_ NodeStsTCP_CAN_5_LcFA : 40|1@0+ (1,0) [0|1] "" AMP,FPI,HVAC_FP_F,HVAC_FP_R,ICS_Info,PDR,MFC,PLCM,RSI,RadioLow,VKM,CSM,CSM_AV,IPC,IPC_INT,VCU,WCM,WCM2,WCM3,WCM4
 SG_ NodeStsTCM_CAN_2_LcFA : 41|1@0+ (1,0) [0|1] "" AMP,FPI,HVAC_FP_F,HVAC_FP_R,ICS_Info,PDR,MFC,PLCM,RSI,RadioLow,TCP,VKM,CSM,CSM_AV,IPC,IPC_INT,VCU,WCM,WCM2,WCM3,WCM4
 SG_ NodeStsTCCM_LcFA : 43|1@0+ (1,0) [0|1] "" AMP,FPI,HVAC_FP_F,HVAC_FP_R,ICS_Info,PDR,MFC,PLCM,RSI,RadioLow,TCP,VKM,CSM,CSM_AV,IPC,IPC_INT,VCU,WCM,WCM2,WCM3,WCM4
 SG_ NodeStsSRR_SRR_LcFA : 45|1@0+ (1,0) [0|1] "" AMP,FPI,HVAC_FP_F,HVAC_FP_R,ICS_Info,PDR,MFC,PLCM,RSI,RadioLow,TCP,VKM,CSM,CSM_AV,IPC,IPC_INT,VCU,WCM,WCM2,WCM3,WCM4
 SG_ NodeStsSRR_SLR_LcFA : 46|1@0+ (1,0) [0|1] "" AMP,FPI,HVAC_FP_F,HVAC_FP_R,ICS_Info,PDR,MFC,PLCM,RSI,RadioLow,TCP,VKM,CSM,CSM_AV,IPC,IPC_INT,VCU,WCM,WCM2,WCM3,WCM4
 SG_ NodeStsSRR_RR_LcFA : 47|1@0+ (1,0) [0|1] "" AMP,FPI,HVAC_FP_F,HVAC_FP_R,ICS_Info,PDR,MFC,PLCM,RSI,RadioLow,TCP,VKM,CSM,CSM_AV,IPC,IPC_INT,VCU,WCM,WCM2,WCM3,WCM4
 SG_ NodeStsWCM_LcFA : 48|1@0+ (1,0) [0|1] "" AMP,FPI,HVAC_FP_F,HVAC_FP_R,ICS_Info,PDR,MFC,PLCM,RSI,RadioLow,TCP,VKM,CSM,CSM_AV,IPC,IPC_INT,VCU,WCM2,WCM3,WCM4
 SG_ NodeStsVPM_LcFA : 49|1@0+ (1,0) [0|1] "" AMP,FPI,HVAC_FP_F,HVAC_FP_R,ICS_Info,PDR,MFC,PLCM,RSI,RadioLow,TCP,VKM,CSM,CSM_AV,IPC,IPC_INT,VCU,WCM,WCM2,WCM3,WCM4
 SG_ NodeStsVLM_LcFA : 50|1@0+ (1,0) [0|1] "" AMP,FPI,HVAC_FP_F,HVAC_FP_R,ICS_Info,PDR,MFC,PLCM,RSI,RadioLow,TCP,VKM,CSM,CSM_AV,IPC,IPC_INT,VCU,WCM,WCM2,WCM3,WCM4
 SG_ NodeStsVKM_LcFA : 51|1@0+ (1,0) [0|1] "" AMP,FPI,HVAC_FP_F,HVAC_FP_R,ICS_Info,PDR,MFC,PLCM,RSI,RadioLow,TCP,CSM,CSM_AV,IPC,IPC_INT,VCU,WCM,WCM2,WCM3,WCM4
 SG_ NodeStsVICM_CAN_9_LcFA : 52|1@0+ (1,0) [0|1] "" AMP,FPI,HVAC_FP_F,HVAC_FP_R,ICS_Info,PDR,MFC,PLCM,RSI,RadioLow,TCP,VKM,CSM,CSM_AV,IPC,IPC_INT,VCU,WCM,WCM2,WCM3,WCM4
 SG_ NodeStsVICM_CAN_2_LcFA : 53|1@0+ (1,0) [0|1] "" AMP,FPI,HVAC_FP_F,HVAC_FP_R,ICS_Info,PDR,MFC,PLCM,RSI,RadioLow,TCP,VKM,CSM,CSM_AV,IPC,IPC_INT,VCU,WCM,WCM2,WCM3,WCM4
 SG_ NodeStsVCU_CAN_5_LcFA : 54|1@0+ (1,0) [0|1] "" AMP,FPI,HVAC_FP_F,HVAC_FP_R,ICS_Info,PDR,MFC,PLCM,RSI,RadioLow,TCP,VKM,CSM,CSM_AV,IPC,IPC_INT,WCM,WCM2,WCM3,WCM4
 SG_ NodeStsTIM_LcFA : 55|1@0+ (1,0) [0|1] "" AMP,FPI,HVAC_FP_F,HVAC_FP_R,ICS_Info,PDR,MFC,PLCM,RSI,RadioLow,TCP,VKM,CSM,CSM_AV,IPC,IPC_INT,VCU,WCM,WCM2,WCM3,WCM4
 SG_ NodeStsECP_S2_CAN_2_LcFA : 56|1@0+ (1,0) [0|1] "" AMP,FPI,HVAC_FP_F,HVAC_FP_R,ICS_Info,PDR,MFC,PLCM,RSI,RadioLow,TCP,VKM,CSM,CSM_AV,IPC,IPC_INT,VCU,WCM,WCM2,WCM3,WCM4
 SG_ NodeStsPFCM_LcFA : 57|1@0+ (1,0) [0|1] "" AMP,FPI,HVAC_FP_F,HVAC_FP_R,ICS_Info,PDR,MFC,PLCM,RSI,RadioLow,TCP,VKM,CSM,CSM_AV,IPC,IPC_INT,VCU,WCM,WCM2,WCM3,WCM4
 SG_ NodeStsVDM_CAN_2_LcFA : 58|1@0+ (1,0) [0|1] "" AMP,FPI,HVAC_FP_F,HVAC_FP_R,ICS_Info,PDR,MFC,PLCM,RSI,RadioLow,TCP,VKM,CSM,CSM_AV,IPC,IPC_INT,VCU,WCM,WCM2,WCM3,WCM4
 SG_ NodeStsPCM_CAN_3_LcFA : 60|1@0+ (1,0) [0|1] "" AMP,FPI,HVAC_FP_F,HVAC_FP_R,ICS_Info,PDR,MFC,PLCM,RSI,RadioLow,TCP,VKM,CSM,CSM_AV,IPC,IPC_INT,VCU,WCM,WCM2,WCM3,WCM4
 SG_ NodeStsPCM_CAN_2_LcFA : 61|1@0+ (1,0) [0|1] "" AMP,FPI,HVAC_FP_F,HVAC_FP_R,ICS_Info,PDR,MFC,PLCM,RSI,RadioLow,TCP,VKM,CSM,CSM_AV,IPC,IPC_INT,VCU,WCM,WCM2,WCM3,WCM4
 SG_ NodeStsSDM_AV_LcFA : 62|1@0+ (1,0) [0|1] "" AMP,FPI,HVAC_FP_F,HVAC_FP_R,ICS_Info,PDR,MFC,PLCM,RSI,RadioLow,TCP,VKM,CSM,CSM_AV,IPC,IPC_INT,VCU,WCM,WCM2,WCM3,WCM4

BO_ 962 NodeStatus_CAN5_PDU03: 8 CGM
 SG_ NodeStsACP4_MCU_CAN_2_LcFA : 0|1@0+ (1,0) [0|1] "" AMP,FPI,HVAC_FP_F,HVAC_FP_R,ICS_Info,PDR,MFC,PLCM,RSI,RadioLow,TCP,VKM,CSM,CSM_AV,IPC,IPC_INT,VCU,WCM,WCM2,WCM3,WCM4
 SG_ NodeStsACP2_MCU_CAN_8_LcFA : 1|1@0+ (1,0) [0|1] "" AMP,FPI,HVAC_FP_F,HVAC_FP_R,ICS_Info,PDR,MFC,PLCM,RSI,RadioLow,TCP,VKM,CSM,CSM_AV,IPC,IPC_INT,VCU,WCM,WCM2,WCM3,WCM4
 SG_ NodeStsACP2_MCU_CAN_2_LcFA : 2|1@0+ (1,0) [0|1] "" AMP,FPI,HVAC_FP_F,HVAC_FP_R,ICS_Info,PDR,MFC,PLCM,RSI,RadioLow,TCP,VKM,CSM,CSM_AV,IPC,IPC_INT,VCU,WCM,WCM2,WCM3,WCM4
 SG_ NodeStsVECM_CAN_2_LcFA : 3|1@0+ (1,0) [0|1] "" AMP,FPI,HVAC_FP_F,HVAC_FP_R,ICS_Info,PDR,MFC,PLCM,RSI,RadioLow,TCP,VKM,CSM,CSM_AV,IPC,IPC_INT,VCU,WCM,WCM2,WCM3,WCM4
 SG_ NodeStsVDM_CAN_9_LcFA : 4|1@0+ (1,0) [0|1] "" AMP,FPI,HVAC_FP_F,HVAC_FP_R,ICS_Info,PDR,MFC,PLCM,RSI,RadioLow,TCP,VKM,CSM,CSM_AV,IPC,IPC_INT,VCU,WCM,WCM2,WCM3,WCM4
 SG_ NodeStsUVM_CAN_1_LcFA : 5|1@0+ (1,0) [0|1] "" AMP,FPI,HVAC_FP_F,HVAC_FP_R,ICS_Info,PDR,MFC,PLCM,RSI,RadioLow,TCP,VKM,CSM,CSM_AV,IPC,IPC_INT,VCU,WCM,WCM2,WCM3,WCM4
 SG_ NodeStsUPM_LcFA : 6|1@0+ (1,0) [0|1] "" AMP,FPI,HVAC_FP_F,HVAC_FP_R,ICS_Info,PDR,MFC,PLCM,RSI,RadioLow,TCP,VKM,CSM,CSM_AV,IPC,IPC_INT,VCU,WCM,WCM2,WCM3,WCM4
 SG_ NodeStsEPSb_LcFA : 7|1@0+ (1,0) [0|1] "" AMP,FPI,HVAC_FP_F,HVAC_FP_R,ICS_Info,PDR,MFC,PLCM,RSI,RadioLow,TCP,VKM,CSM,CSM_AV,IPC,IPC_INT,VCU,WCM,WCM2,WCM3,WCM4
 SG_ NodeStsSBM_CAN_10_LcFA : 8|1@0+ (1,0) [0|1] "" AMP,FPI,HVAC_FP_F,HVAC_FP_R,ICS_Info,PDR,MFC,PLCM,RSI,RadioLow,TCP,VKM,CSM,CSM_AV,IPC,IPC_INT,VCU,WCM,WCM2,WCM3,WCM4
 SG_ NodeStsVECM_CAN_9_LcFA : 9|1@0+ (1,0) [0|1] "" AMP,FPI,HVAC_FP_F,HVAC_FP_R,ICS_Info,PDR,MFC,PLCM,RSI,RadioLow,TCP,VKM,CSM,CSM_AV,IPC,IPC_INT,VCU,WCM,WCM2,WCM3,WCM4
 SG_ NodeStsECP_S2_CAN_9_LcFA : 11|1@0+ (1,0) [0|1] "" AMP,FPI,HVAC_FP_F,HVAC_FP_R,ICS_Info,PDR,MFC,PLCM,RSI,RadioLow,TCP,VKM,CSM,CSM_AV,IPC,IPC_INT,VCU,WCM,WCM2,WCM3,WCM4
 SG_ NodeStsCSM_AV_CAN_5_LcFA : 12|1@0+ (1,0) [0|1] "" AMP,FPI,HVAC_FP_F,HVAC_FP_R,ICS_Info,PDR,MFC,PLCM,RSI,RadioLow,TCP,VKM,CSM,IPC,IPC_INT,VCU,WCM,WCM2,WCM3,WCM4
 SG_ NodeStsACP3_MCU_CAN_3_LcFA : 13|1@0+ (1,0) [0|1] "" AMP,FPI,HVAC_FP_F,HVAC_FP_R,ICS_Info,PDR,MFC,PLCM,RSI,RadioLow,TCP,VKM,CSM,CSM_AV,IPC,IPC_INT,VCU,WCM,WCM2,WCM3,WCM4
 SG_ NodeStsACP3_MCU_CAN_8_LcFA : 14|1@0+ (1,0) [0|1] "" AMP,FPI,HVAC_FP_F,HVAC_FP_R,ICS_Info,PDR,MFC,PLCM,RSI,RadioLow,TCP,VKM,CSM,CSM_AV,IPC,IPC_INT,VCU,WCM,WCM2,WCM3,WCM4
 SG_ NodeStsACP3_MCU_CAN_2_LcFA : 15|1@0+ (1,0) [0|1] "" AMP,FPI,HVAC_FP_F,HVAC_FP_R,ICS_Info,PDR,MFC,PLCM,RSI,RadioLow,TCP,VKM,CSM,CSM_AV,IPC,IPC_INT,VCU,WCM,WCM2,WCM3,WCM4
 SG_ NodeStsWCM4_LcFA : 16|1@0+ (1,0) [0|1] "" AMP,FPI,HVAC_FP_F,HVAC_FP_R,ICS_Info,PDR,MFC,PLCM,RSI,RadioLow,TCP,VKM,CSM,CSM_AV,IPC,IPC_INT,VCU,WCM,WCM2,WCM3
 SG_ NodeStsWCM3_LcFA : 17|1@0+ (1,0) [0|1] "" AMP,FPI,HVAC_FP_F,HVAC_FP_R,ICS_Info,PDR,MFC,PLCM,RSI,RadioLow,TCP,VKM,CSM,CSM_AV,IPC,IPC_INT,VCU,WCM,WCM2,WCM4
 SG_ NodeStsWCM2_LcFA : 18|1@0+ (1,0) [0|1] "" AMP,FPI,HVAC_FP_F,HVAC_FP_R,ICS_Info,PDR,MFC,PLCM,RSI,RadioLow,TCP,VKM,CSM,CSM_AV,IPC,IPC_INT,VCU,WCM,WCM3,WCM4
 SG_ NodeStsRSI_CAN_5_LcFA : 19|1@0+ (1,0) [0|1] "" AMP,FPI,HVAC_FP_F,HVAC_FP_R,ICS_Info,PDR,MFC,PLCM,RadioLow,TCP,VKM,CSM,CSM_AV,IPC,IPC_INT,VCU,WCM,WCM2,WCM3,WCM4
 SG_ NodeStsLIB_48V_LcFA : 20|1@0+ (1,0) [0|1] "" AMP,FPI,HVAC_FP_F,HVAC_FP_R,ICS_Info,PDR,MFC,PLCM,RSI,RadioLow,TCP,VKM,CSM,CSM_AV,IPC,IPC_INT,VCU,WCM,WCM2,WCM3,WCM4
 SG_ NodeStsFPI_CAN_5_LcFA : 21|1@0+ (1,0) [0|1] "" AMP,HVAC_FP_F,HVAC_FP_R,ICS_Info,PDR,MFC,PLCM,RSI,RadioLow,TCP,VKM,CSM,CSM_AV,IPC,IPC_INT,VCU,WCM,WCM2,WCM3,WCM4
 SG_ NodeStsACP4_MCU_CAN_3_LcFA : 22|1@0+ (1,0) [0|1] "" AMP,FPI,HVAC_FP_F,HVAC_FP_R,ICS_Info,PDR,MFC,PLCM,RSI,RadioLow,TCP,VKM,CSM,CSM_AV,IPC,IPC_INT,VCU,WCM,WCM2,WCM3,WCM4
 SG_ NodeStsACP4_MCU_CAN_8_LcFA : 23|1@0+ (1,0) [0|1] "" AMP,FPI,HVAC_FP_F,HVAC_FP_R,ICS_Info,PDR,MFC,PLCM,RSI,RadioLow,TCP,VKM,CSM,CSM_AV,IPC,IPC_INT,VCU,WCM,WCM2,WCM3,WCM4
 SG_ NodeStsBSM_HEV_CAN_2_LcFA : 24|1@0+ (1,0) [0|1] "" AMP,FPI,HVAC_FP_F,HVAC_FP_R,ICS_Info,PDR,MFC,PLCM,RSI,RadioLow,TCP,VKM,CSM,CSM_AV,IPC,IPC_INT,VCU,WCM,WCM2,WCM3,WCM4
 SG_ NodeStsECP_H3_CAN_2_LcFA : 25|1@0+ (1,0) [0|1] "" AMP,FPI,HVAC_FP_F,HVAC_FP_R,ICS_Info,PDR,MFC,PLCM,RSI,RadioLow,TCP,VKM,CSM,CSM_AV,IPC,IPC_INT,VCU,WCM,WCM2,WCM3,WCM4
 SG_ NodeStsECP_H2_CAN_2_LcFA : 26|1@0+ (1,0) [0|1] "" AMP,FPI,HVAC_FP_F,HVAC_FP_R,ICS_Info,PDR,MFC,PLCM,RSI,RadioLow,TCP,VKM,CSM,CSM_AV,IPC,IPC_INT,VCU,WCM,WCM2,WCM3,WCM4
 SG_ NodeStsECP_H2_CAN_9_LcFA : 27|1@0+ (1,0) [0|1] "" AMP,FPI,HVAC_FP_F,HVAC_FP_R,ICS_Info,PDR,MFC,PLCM,RSI,RadioLow,TCP,VKM,CSM,CSM_AV,IPC,IPC_INT,VCU,WCM,WCM2,WCM3,WCM4
 SG_ NodeStsECP_H1_CAN_9_LcFA : 28|1@0+ (1,0) [0|1] "" AMP,FPI,HVAC_FP_F,HVAC_FP_R,ICS_Info,PDR,MFC,PLCM,RSI,RadioLow,TCP,VKM,CSM,CSM_AV,IPC,IPC_INT,VCU,WCM,WCM2,WCM3,WCM4
 SG_ NodeStsECP_H1_CAN_2_LcFA : 29|1@0+ (1,0) [0|1] "" AMP,FPI,HVAC_FP_F,HVAC_FP_R,ICS_Info,PDR,MFC,PLCM,RSI,RadioLow,TCP,VKM,CSM,CSM_AV,IPC,IPC_INT,VCU,WCM,WCM2,WCM3,WCM4
 SG_ NodeStsBSM_HEV_CAN_9_LcFA : 30|1@0+ (1,0) [0|1] "" AMP,FPI,HVAC_FP_F,HVAC_FP_R,ICS_Info,PDR,MFC,PLCM,RSI,RadioLow,TCP,VKM,CSM,CSM_AV,IPC,IPC_INT,VCU,WCM,WCM2,WCM3,WCM4
 SG_ NodeStsECP_H3_CAN_9_LcFA : 31|1@0+ (1,0) [0|1] "" AMP,FPI,HVAC_FP_F,HVAC_FP_R,ICS_Info,PDR,MFC,PLCM,RSI,RadioLow,TCP,VKM,CSM,CSM_AV,IPC,IPC_INT,VCU,WCM,WCM2,WCM3,WCM4
 SG_ NodeStsSAM_BH_LcFA : 36|1@0+ (1,0) [0|1] "" AMP,FPI,HVAC_FP_F,HVAC_FP_R,ICS_Info,PDR,MFC,PLCM,RSI,RadioLow,TCP,VKM,CSM,CSM_AV,IPC,IPC_INT,VCU,WCM,WCM2,WCM3,WCM4
 SG_ NodeStsPLCM_LcFA : 37|1@0+ (1,0) [0|1] "" AMP,FPI,HVAC_FP_F,HVAC_FP_R,ICS_Info,PDR,MFC,RSI,RadioLow,TCP,VKM,CSM,CSM_AV,IPC,IPC_INT,VCU,WCM,WCM2,WCM3,WCM4
 SG_ NodeStsODS_LcFA : 38|1@0+ (1,0) [0|1] "" AMP,FPI,HVAC_FP_F,HVAC_FP_R,ICS_Info,PDR,MFC,PLCM,RSI,RadioLow,TCP,VKM,CSM,CSM_AV,IPC,IPC_INT,VCU,WCM,WCM2,WCM3,WCM4
 SG_ NodeStsODS2_LcFA : 39|1@0+ (1,0) [0|1] "" AMP,FPI,HVAC_FP_F,HVAC_FP_R,ICS_Info,PDR,MFC,PLCM,RSI,RadioLow,TCP,VKM,CSM,CSM_AV,IPC,IPC_INT,VCU,WCM,WCM2,WCM3,WCM4

BO_ 952 NodeStatus_CAN5_PDU04: 8 CGM
 SG_ NodeStsEBCM_CAN_3_Prsnt : 0|1@0+ (1,0) [0|1] "" TCP
 SG_ NodeStsICCM_CAN_3_Prsnt : 1|1@0+ (1,0) [0|1] "" TCP
 SG_ NodeStsARB_Prsnt : 2|1@0+ (1,0) [0|1] "" TCP
 SG_ NodeStsVECM_CAN_2_Prsnt : 3|1@0+ (1,0) [0|1] "" TCP
 SG_ NodeStsEBCM_AV_CAN_3_Prsnt : 4|1@0+ (1,0) [0|1] "" TCP
 SG_ NodeStsSRR_SRR_Prsnt : 5|1@0+ (1,0) [0|1] "" TCP
 SG_ NodeStsADIMa_CAN_9_Prsnt : 6|1@0+ (1,0) [0|1] "" TCP
 SG_ NodeStsTIM_Prsnt : 7|1@0+ (1,0) [0|1] "" TCP
 SG_ NodeStsSDM_AV_Prsnt : 8|1@0+ (1,0) [0|1] "" TCP
 SG_ NodeStsEOCM_HCP2_Prsnt : 9|1@0+ (1,0) [0|1] "" TCP
 SG_ NodeStsLIB1_Prsnt : 10|1@0+ (1,0) [0|1] "" TCP
 SG_ NodeStsELM_Prsnt : 12|1@0+ (1,0) [0|1] "" TCP
 SG_ NodeStsMFC_Prsnt : 13|1@0+ (1,0) [0|1] "" TCP
 SG_ NodeStsEBCM_CAN_2_Prsnt : 14|1@0+ (1,0) [0|1] "" TCP
 SG_ NodeStsEOCM_HCP1_CAN_3_Prsnt : 15|1@0+ (1,0) [0|1] "" TCP
 SG_ NodeStsEPSRAa_Prsnt : 16|1@0+ (1,0) [0|1] "" TCP
 SG_ NodeStsSADS_Prsnt : 17|1@0+ (1,0) [0|1] "" TCP
 SG_ NodeStsSAM_RF_Prsnt : 18|1@0+ (1,0) [0|1] "" TCP
 SG_ NodeStsSAM_LF_Prsnt : 19|1@0+ (1,0) [0|1] "" TCP
 SG_ NodeStsFCM_Prsnt : 20|1@0+ (1,0) [0|1] "" TCP
 SG_ NodeStsSAM_RR_Prsnt : 21|1@0+ (1,0) [0|1] "" TCP
 SG_ NodeStsECP_H3_CAN_2_Prsnt : 22|1@0+ (1,0) [0|1] "" TCP
 SG_ NodeStsVDM_CAN_9_Prsnt : 23|1@0+ (1,0) [0|1] "" TCP
 SG_ NodeStsECP_X1_CAN_2_Prsnt : 24|1@0+ (1,0) [0|1] "" TCP
 SG_ NodeStsMRCM_L_Prsnt : 25|1@0+ (1,0) [0|1] "" TCP
 SG_ NodeStsBSM_HEV_CAN_9_Prsnt : 26|1@0+ (1,0) [0|1] "" TCP
 SG_ NodeStsSBM_CAN_10_Prsnt : 27|1@0+ (1,0) [0|1] "" TCP
 SG_ NodeStsFOPM_CAN_2_Prsnt : 28|1@0+ (1,0) [0|1] "" TCP
 SG_ NodeStsHUD_CAN_Prsnt : 29|1@0+ (1,0) [0|1] "" TCP
 SG_ NodeStsRSI_CAN_5_Prsnt : 30|1@0+ (1,0) [0|1] "" TCP
 SG_ NodeStsPTM_Prsnt : 31|1@0+ (1,0) [0|1] "" TCP
 SG_ NodeStsBSM_HEV_CAN_2_Prsnt : 32|1@0+ (1,0) [0|1] "" TCP
 SG_ NodeStsECP_S2_CAN_9_Prsnt : 33|1@0+ (1,0) [0|1] "" TCP
 SG_ NodeStsSBZA_L_Prsnt : 35|1@0+ (1,0) [0|1] "" TCP
 SG_ NodeStsMTCM_R_Prsnt : 36|1@0+ (1,0) [0|1] "" TCP
 SG_ NodeStsECM_CAN_3_Prsnt : 37|1@0+ (1,0) [0|1] "" TCP
 SG_ NodeStsEPSRAb_Prsnt : 38|1@0+ (1,0) [0|1] "" TCP
 SG_ NodeStsAMP_Prsnt : 39|1@0+ (1,0) [0|1] "" TCP
 SG_ NodeStsRadioLow_Prsnt : 40|1@0+ (1,0) [0|1] "" TCP
 SG_ NodeStsFOPM_CAN_3_Prsnt : 41|1@0+ (1,0) [0|1] "" TCP
 SG_ NodeStsLIB_48V_Prsnt : 42|1@0+ (1,0) [0|1] "" TCP
 SG_ NodeStsAPA_CAN_2_Prsnt : 43|1@0+ (1,0) [0|1] "" TCP
 SG_ NodeStsFPI_CAN_5_Prsnt : 44|1@0+ (1,0) [0|1] "" TCP
 SG_ NodeStsHDLM_Prsnt : 45|1@0+ (1,0) [0|1] "" TCP
 SG_ NodeStsMSM_LR_Prsnt : 46|1@0+ (1,0) [0|1] "" TCP
 SG_ NodeStsBSM_MH_Prsnt : 48|1@0+ (1,0) [0|1] "" TCP
 SG_ NodeStsECP_H1_CAN_9_Prsnt : 49|1@0+ (1,0) [0|1] "" TCP
 SG_ NodeStsPA_Prsnt : 50|1@0+ (1,0) [0|1] "" TCP
 SG_ NodeStsSAM_LR_Prsnt : 51|1@0+ (1,0) [0|1] "" TCP
 SG_ NodeStsEBCM_AV_CAN_2_Prsnt : 52|1@0+ (1,0) [0|1] "" TCP
 SG_ NodeStsADIMa_CAN_3_Prsnt : 53|1@0+ (1,0) [0|1] "" TCP
 SG_ NodeStsACP2_MCU_CAN_2_Prsnt : 54|1@0+ (1,0) [0|1] "" TCP
 SG_ NodeStsWCM_Prsnt : 55|1@0+ (1,0) [0|1] "" TCP
 SG_ NodeStsECP_MC_Prsnt : 56|1@0+ (1,0) [0|1] "" TCP
 SG_ NodeStsADIMb_CAN_10_Prsnt : 57|1@0+ (1,0) [0|1] "" TCP
 SG_ NodeStsMSB2_Prsnt : 58|1@0+ (1,0) [0|1] "" TCP
 SG_ NodeStsMSM_P_Prsnt : 59|1@0+ (1,0) [0|1] "" TCP
 SG_ NodeStsAHL_AFL_CAN_2_Prsnt : 60|1@0+ (1,0) [0|1] "" TCP
 SG_ NodeStsPCM_CAN_2_Prsnt : 61|1@0+ (1,0) [0|1] "" TCP
 SG_ NodeStsEPS_Prsnt : 62|1@0+ (1,0) [0|1] "" TCP
 SG_ NodeStsACP4_MCU_CAN_3_Prsnt : 63|1@0+ (1,0) [0|1] "" TCP

BO_ 953 NodeStatus_CAN5_PDU05: 8 CGM
 SG_ NodeStsPDR_Prsnt : 0|1@0+ (1,0) [0|1] "" TCP
 SG_ NodeStsECP_X1_CAN_3_Prsnt : 1|1@0+ (1,0) [0|1] "" TCP
 SG_ NodeStsRDCM_Prsnt : 2|1@0+ (1,0) [0|1] "" TCP
 SG_ NodeStsECP_H2_CAN_2_Prsnt : 3|1@0+ (1,0) [0|1] "" TCP
 SG_ NodeStsBCM_Prsnt : 4|1@0+ (1,0) [0|1] "" TCP
 SG_ NodeStsAPA_CAN_1_Prsnt : 5|1@0+ (1,0) [0|1] "" TCP
 SG_ NodeStsMTCM_L_Prsnt : 6|1@0+ (1,0) [0|1] "" TCP
 SG_ NodeStsADIMa_CAN_10_Prsnt : 7|1@0+ (1,0) [0|1] "" TCP
 SG_ NodeStsPCM_CAN_3_Prsnt : 8|1@0+ (1,0) [0|1] "" TCP
 SG_ NodeStsACP3_MCU_CAN_3_Prsnt : 9|1@0+ (1,0) [0|1] "" TCP
 SG_ NodeStsWCM2_Prsnt : 10|1@0+ (1,0) [0|1] "" TCP
 SG_ NodeStsICS_Info_Prsnt : 11|1@0+ (1,0) [0|1] "" TCP
 SG_ NodeStsLRR_Prsnt : 12|1@0+ (1,0) [0|1] "" TCP
 SG_ NodeStsWCM4_Prsnt : 13|1@0+ (1,0) [0|1] "" TCP
 SG_ NodeStsBSM_CAN_2_Prsnt : 14|1@0+ (1,0) [0|1] "" TCP
 SG_ NodeStsEOCM_CAN_2_Prsnt : 15|1@0+ (1,0) [0|1] "" TCP
 SG_ NodeStsWCM3_Prsnt : 17|1@0+ (1,0) [0|1] "" TCP
 SG_ NodeStsVKM_Prsnt : 18|1@0+ (1,0) [0|1] "" TCP
 SG_ NodeStsSDM_Prsnt : 19|1@0+ (1,0) [0|1] "" TCP
 SG_ NodeStsSIB_Prsnt : 20|1@0+ (1,0) [0|1] "" TCP
 SG_ NodeStsHVAC_FP_F_Prsnt : 21|1@0+ (1,0) [0|1] "" TCP
 SG_ NodeStsDEFC_Prsnt : 22|1@0+ (1,0) [0|1] "" TCP
 SG_ NodeStsVICM_CAN_2_Prsnt : 23|1@0+ (1,0) [0|1] "" TCP
 SG_ NodeStsSCL_Prsnt : 24|1@0+ (1,0) [0|1] "" TCP
 SG_ NodeStsACP2_MCU_CAN_8_Prsnt : 25|1@0+ (1,0) [0|1] "" TCP
 SG_ NodeStsEPS_1_Prsnt : 26|1@0+ (1,0) [0|1] "" TCP
 SG_ NodeStsFCM_LC_Prsnt : 27|1@0+ (1,0) [0|1] "" TCP
 SG_ NodeStsIPC_CAN_5_Prsnt : 28|1@0+ (1,0) [0|1] "" TCP
 SG_ NodeStsEOCM_HCP1_CAN_2_Prsnt : 29|1@0+ (1,0) [0|1] "" TCP
 SG_ NodeStsTCCM_Prsnt : 30|1@0+ (1,0) [0|1] "" TCP
 SG_ NodeStsSBM_CAN_3_Prsnt : 31|1@0+ (1,0) [0|1] "" TCP
 SG_ NodeStsARS_Prsnt : 32|1@0+ (1,0) [0|1] "" TCP
 SG_ NodeStsEPSb_Prsnt : 33|1@0+ (1,0) [0|1] "" TCP
 SG_ NodeStsBSM_CAN_3_Prsnt : 34|1@0+ (1,0) [0|1] "" TCP
 SG_ NodeStsVCU_CAN_5_Prsnt : 35|1@0+ (1,0) [0|1] "" TCP
 SG_ NodeStsAHS_Prsnt : 36|1@0+ (1,0) [0|1] "" TCP
 SG_ NodeStsCSM_CAN_5_Prsnt : 37|1@0+ (1,0) [0|1] "" TCP
 SG_ NodeStsVICM_CAN_9_Prsnt : 38|1@0+ (1,0) [0|1] "" TCP
 SG_ NodeStsSRR_LF_Prsnt : 39|1@0+ (1,0) [0|1] "" TCP
 SG_ NodeStsTCM_CAN_2_Prsnt : 40|1@0+ (1,0) [0|1] "" TCP
 SG_ NodeStsVPM_Prsnt : 41|1@0+ (1,0) [0|1] "" TCP
 SG_ NodeStsSRR_RF_Prsnt : 42|1@0+ (1,0) [0|1] "" TCP
 SG_ NodeStsACP3_MCU_CAN_8_Prsnt : 43|1@0+ (1,0) [0|1] "" TCP
 SG_ NodeStsECP_E_CAN_2_Prsnt : 44|1@0+ (1,0) [0|1] "" TCP
 SG_ NodeStsSBZA_R_Prsnt : 45|1@0+ (1,0) [0|1] "" TCP
 SG_ NodeStsVLM_Prsnt : 46|1@0+ (1,0) [0|1] "" TCP
 SG_ NodeStsADIMb_CAN_9_Prsnt : 47|1@0+ (1,0) [0|1] "" TCP
 SG_ NodeStsUVM_CAN_1_Prsnt : 48|1@0+ (1,0) [0|1] "" TCP
 SG_ NodeStsALC_Prsnt : 49|1@0+ (1,0) [0|1] "" TCP
 SG_ NodeStsSRR_LR_CR_Prsnt : 50|1@0+ (1,0) [0|1] "" TCP
 SG_ NodeStsDCM_Prsnt : 51|1@0+ (1,0) [0|1] "" TCP
 SG_ NodeStsNVM_Prsnt : 52|1@0+ (1,0) [0|1] "" TCP
 SG_ NodeStsDMS_Prsnt : 53|1@0+ (1,0) [0|1] "" TCP
 SG_ NodeStsTCP_CAN_5_Prsnt : 54|1@0+ (1,0) [0|1] "" TCP
 SG_ NodeStsECM_CAN_2_Prsnt : 55|1@0+ (1,0) [0|1] "" TCP
 SG_ NodeStsADIMb_CAN_2_Prsnt : 56|1@0+ (1,0) [0|1] "" TCP
 SG_ NodeStsSRR_RR_Prsnt : 57|1@0+ (1,0) [0|1] "" TCP
 SG_ NodeStsADIMa_CAN_2_Prsnt : 58|1@0+ (1,0) [0|1] "" TCP
 SG_ NodeStsHVAC_FP_R_Prsnt : 59|1@0+ (1,0) [0|1] "" TCP
 SG_ NodeStsSRR_SLR_Prsnt : 60|1@0+ (1,0) [0|1] "" TCP
 SG_ NodeStsEOCM_HCP1_CAN_8_Prsnt : 61|1@0+ (1,0) [0|1] "" TCP
 SG_ NodeStsECP_S2_CAN_2_Prsnt : 62|1@0+ (1,0) [0|1] "" TCP
 SG_ NodeStsECP_S_CAN_9_Prsnt : 63|1@0+ (1,0) [0|1] "" TCP

BO_ 954 NodeStatus_CAN5_PDU06: 8 CGM
 SG_ NodeStsUPM_Prsnt : 0|1@0+ (1,0) [0|1] "" TCP
 SG_ NodeStsMSM_RR_Prsnt : 1|1@0+ (1,0) [0|1] "" TCP
 SG_ NodeStsEOCM_CAN_8_Prsnt : 2|1@0+ (1,0) [0|1] "" TCP
 SG_ NodeStsMSB1_Prsnt : 3|1@0+ (1,0) [0|1] "" TCP
 SG_ NodeStsECP_H3_CAN_9_Prsnt : 4|1@0+ (1,0) [0|1] "" TCP
 SG_ NodeStsECP_S_CAN_2_Prsnt : 5|1@0+ (1,0) [0|1] "" TCP
 SG_ NodeStsECP_E_CAN_9_Prsnt : 6|1@0+ (1,0) [0|1] "" TCP
 SG_ NodeStsAOS_Prsnt : 7|1@0+ (1,0) [0|1] "" TCP
 SG_ NodeStsECP_H2_CAN_9_Prsnt : 8|1@0+ (1,0) [0|1] "" TCP
 SG_ NodeStsCSM_AV_CAN_5_Prsnt : 9|1@0+ (1,0) [0|1] "" TCP
 SG_ NodeStsMSM_D_Prsnt : 10|1@0+ (1,0) [0|1] "" TCP
 SG_ NodeStsACP3_MCU_CAN_2_Prsnt : 11|1@0+ (1,0) [0|1] "" TCP
 SG_ NodeStsADIMb_CAN_3_Prsnt : 12|1@0+ (1,0) [0|1] "" TCP
 SG_ NodeStsECP_H1_CAN_2_Prsnt : 13|1@0+ (1,0) [0|1] "" TCP
 SG_ NodeStsPFCM_Prsnt : 14|1@0+ (1,0) [0|1] "" TCP
 SG_ NodeStsVECM_CAN_9_Prsnt : 15|1@0+ (1,0) [0|1] "" TCP
 SG_ NodeStsSAM_BH_Prsnt : 16|1@0+ (1,0) [0|1] "" TCP
 SG_ NodeStsODS2_Prsnt : 17|1@0+ (1,0) [0|1] "" TCP
 SG_ NodeStsODS_Prsnt : 18|1@0+ (1,0) [0|1] "" TCP
 SG_ NodeStsACP4_MCU_CAN_2_Prsnt : 19|1@0+ (1,0) [0|1] "" TCP
 SG_ NodeStsVDM_CAN_2_Prsnt : 20|1@0+ (1,0) [0|1] "" TCP
 SG_ NodeStsEOCM_CAN_3_Prsnt : 21|1@0+ (1,0) [0|1] "" TCP
 SG_ NodeStsACP4_MCU_CAN_8_Prsnt : 22|1@0+ (1,0) [0|1] "" TCP
 SG_ NodeStsMRCM_R_Prsnt : 23|1@0+ (1,0) [0|1] "" TCP
 SG_ NodeStsPLCM_Prsnt : 31|1@0+ (1,0) [0|1] "" TCP

BO_ 2564502513 OBD_Req_From_TEST_TOOL_1_To_AllO: 7 CGM

BO_ 1382 OccptRstrntInfo_PCSM_PDU: 8 CGM
 SG_ OccptRstrntInfo_PCSM : 0|64@1+ (1,0) [0|1.84467e+019] "" VCU

BO_ 1322 OccptRstrntInfo_Prtctd_PDU: 8 CGM
 SG_ ORIP_MAC : 7|27@0+ (1,0) [0|1.34218e+008] "" VCU
 SG_ ORIP_FCnt : 28|5@0+ (1,0) [0|31] "" VCU
 SG_ FrtPsngrAirbagDsblVisIndCmd : 33|2@0+ (1,0) [0|2] "" VCU
 SG_ ORIP_ARC : 35|2@0+ (1,0) [0|3] "" VCU
 SG_ ORIP_EnvModPrsntRsp1Auth : 36|1@0+ (1,0) [0|1] "" VCU
 SG_ ORIP_DrvrStBltStsAuth_Inv : 37|1@0+ (1,0) [0|1] "" VCU
 SG_ ORIP_DrvrStBltStsAuth : 39|2@0+ (1,0) [0|2] "" VCU
 SG_ ORIP_Filler : 44|21@0+ (1,0) [0|2.09715e+006] "" VCU
 SG_ RstrntSysFltPrsnt : 45|1@0+ (1,0) [0|1] "" VCU
 SG_ FrtPsngrAirbagEnblVisIndCmd : 47|2@0+ (1,0) [0|2] "" VCU

BO_ 493 PLCM_NM_PDU_On_CAN_5_Cluster: 8 PLCM
 SG_ ISignal_PLCM_CAN_5_Cluster : 23|48@0+ (1,0) [0|281474976710655] "" AMP,CGM,FPI,HVAC_FP_F,HVAC_FP_R,ICS_Info,PDR,MFC,RSI,RadioLow,TCP,VKM,CSM,CSM_AV,IPC,IPC_INT,VCU,WCM,WCM2,WCM3,WCM4

BO_ 1381 PstClsnInfo_PCSM_PDU: 8 CGM
 SG_ PstClsnInfo_PCSM : 0|64@1+ (1,0) [0|1.84467e+019] "" TCP

BO_ 1320 PstClsnInfo_Prtctd_PDU: 8 CGM
 SG_ PCIP_MAC : 7|27@0+ (1,0) [0|1.34218e+008] "" TCP
 SG_ PCIP_FCnt : 28|5@0+ (1,0) [0|31] "" TCP
 SG_ PCIP_HzrdLgtsOnReqdAuth : 32|1@0+ (1,0) [0|1] "" TCP
 SG_ PCIP_HybVehHiVltgDsblReqdAuth : 33|1@0+ (1,0) [0|1] "" TCP
 SG_ PCIP_HVCrshImpSnsSysDsbldAuth : 34|1@0+ (1,0) [0|1] "" TCP
 SG_ PCIP_HVACBlwDsblReqdAuth : 35|1@0+ (1,0) [0|1] "" TCP
 SG_ PCIP_FuelCutOffReqdAuth : 36|1@0+ (1,0) [0|1] "" TCP
 SG_ PCIP_DrUnlckReqdAuth : 37|1@0+ (1,0) [0|1] "" TCP
 SG_ PCIP_CruzCtlDsblReqdAuth : 38|1@0+ (1,0) [0|1] "" TCP
 SG_ PCIP_BrkActReqdAuth : 39|1@0+ (1,0) [0|1] "" TCP
 SG_ PCIP_NtfnEvntCntAuth : 44|8@0+ (1,0) [0|255] "" TCP
 SG_ PCIP_NftnFrtImpPrtnsrSevAchAuth : 45|1@0+ (1,0) [0|1] "" TCP
 SG_ PCIP_MemStRclDsblReqdAuth : 46|1@0+ (1,0) [0|1] "" TCP
 SG_ PCIP_IntrLgtOnReqdAuth : 47|1@0+ (1,0) [0|1] "" TCP
 SG_ PCIP_NtfnLtSdSevAchvdAuth : 48|1@0+ (1,0) [0|1] "" TCP
 SG_ PCIP_NtfnFrtImpStg2SevAchvdAuth : 49|1@0+ (1,0) [0|1] "" TCP
 SG_ PCIP_NtfnFrtImpStg1SevAchvdAuth : 50|1@0+ (1,0) [0|1] "" TCP
 SG_ PCIP_NtfnEvntStsAuth : 52|2@0+ (1,0) [0|2] "" RadioLow,TCP,CSM,CSM_AV,VCU
 SG_ PCIP_Filler : 56|1@0+ (1,0) [0|1] "" TCP
 SG_ PCIP_ARC : 58|2@0+ (1,0) [0|3] "" TCP
 SG_ PCIP_eCallReqdAuth : 59|1@0+ (1,0) [0|1] "" ICS_Info,RadioLow,TCP,CSM,CSM_AV,VCU
 SG_ PCIP_NtfnRtSdSevAchvdAuth : 60|1@0+ (1,0) [0|1] "" TCP
 SG_ PCIP_NtfnRrImpSevAchvdAuth : 61|1@0+ (1,0) [0|1] "" TCP
 SG_ PCIP_NtfnRlOvrSevAchvdAuth : 62|1@0+ (1,0) [0|1] "" TCP
 SG_ PCIP_NtfnPedtrnPrtctnSevAchAuth : 63|1@0+ (1,0) [0|1] "" TCP

BO_ 1399 PwrStrgInfo_PCSM_PDU: 8 CGM
 SG_ PwrStrgInfo_PCSM : 0|64@1+ (1,0) [0|1.84467e+019] "" IPC,IPC_INT,VCU

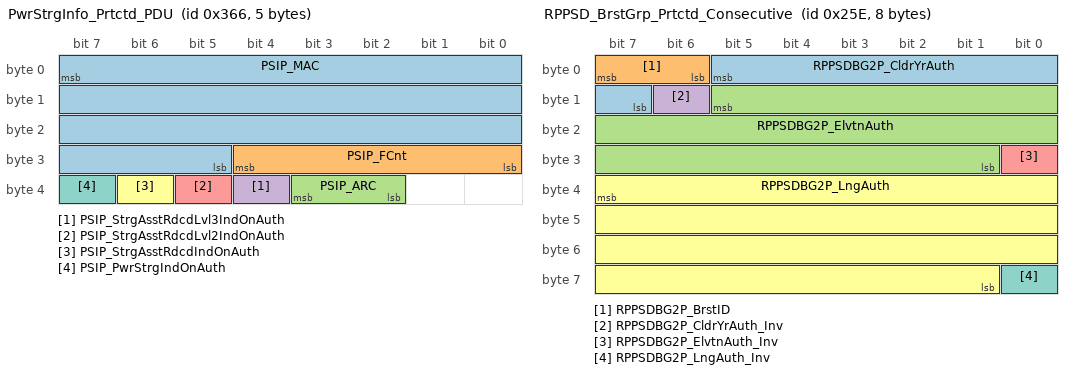
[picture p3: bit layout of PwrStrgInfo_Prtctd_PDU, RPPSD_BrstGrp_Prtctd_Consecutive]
BO_ 870 PwrStrgInfo_Prtctd_PDU: 5 CGM
 SG_ PSIP_MAC : 7|27@0+ (1,0) [0|1.34218e+008] "" IPC,IPC_INT,VCU
 SG_ PSIP_FCnt : 28|5@0+ (1,0) [0|31] "" IPC,IPC_INT,VCU
 SG_ PSIP_ARC : 35|2@0+ (1,0) [0|3] "" IPC,IPC_INT,VCU
 SG_ PSIP_StrgAsstRdcdLvl3IndOnAuth : 36|1@0+ (1,0) [0|1] "" IPC,IPC_INT,VCU
 SG_ PSIP_StrgAsstRdcdLvl2IndOnAuth : 37|1@0+ (1,0) [0|1] "" IPC,IPC_INT,VCU
 SG_ PSIP_StrgAsstRdcdIndOnAuth : 38|1@0+ (1,0) [0|1] "" IPC,IPC_INT,VCU
 SG_ PSIP_PwrStrgIndOnAuth : 39|1@0+ (1,0) [0|1] "" IPC,IPC_INT,VCU

BO_ 1363 RPPSD_BrstGrp_PCSM_PDU: 8 TCP
 SG_ RPPSD_BrstGrp1_PCSM : 0|64@1+ (1,0) [0|1.84467e+019] "" Vector__XXX

BO_ 606 RPPSD_BrstGrp_Prtctd_Consecutive: 8 TCP
 SG_ RPPSDBG2P_CldrYrAuth : 5|7@0+ (1,2014) [2014|2141] "year" Vector__XXX
 SG_ RPPSDBG2P_BrstID : 7|2@0+ (1,0) [0|3] "" Vector__XXX
 SG_ RPPSDBG2P_ElvtnAuth : 13|21@0+ (1,-100000) [-100000|1.99715e+006] "cm" Vector__XXX
 SG_ RPPSDBG2P_CldrYrAuth_Inv : 14|1@0+ (1,0) [0|1] "" Vector__XXX
 SG_ RPPSDBG2P_ElvtnAuth_Inv : 24|1@0+ (1,0) [0|1] "" Vector__XXX
 SG_ RPPSDBG2P_LngAuth : 39|31@0- (1,0) [-1.07374e+009|1.07374e+009] "ms arc" Vector__XXX
 SG_ RPPSDBG2P_LngAuth_Inv : 56|1@0+ (1,0) [0|1] "" Vector__XXX

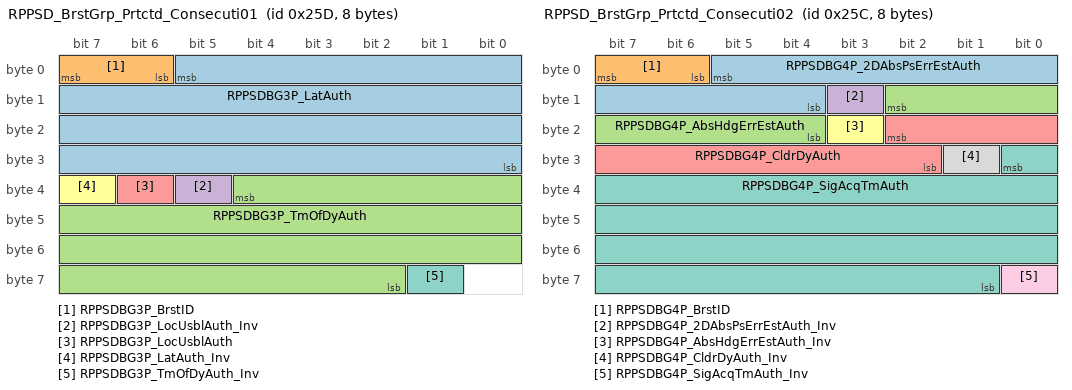
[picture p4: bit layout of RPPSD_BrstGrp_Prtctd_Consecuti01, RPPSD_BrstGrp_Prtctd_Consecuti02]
BO_ 605 RPPSD_BrstGrp_Prtctd_Consecuti01: 8 TCP
 SG_ RPPSDBG3P_LatAuth : 5|30@0- (1,0) [-5.36871e+008|5.36871e+008] "ms arc" Vector__XXX
 SG_ RPPSDBG3P_BrstID : 7|2@0+ (1,0) [0|3] "" Vector__XXX
 SG_ RPPSDBG3P_TmOfDyAuth : 36|27@0+ (1,0) [0|1.34218e+008] "ms" Vector__XXX
 SG_ RPPSDBG3P_LocUsblAuth_Inv : 37|1@0+ (1,0) [0|1] "" Vector__XXX
 SG_ RPPSDBG3P_LocUsblAuth : 38|1@0+ (1,0) [0|1] "" Vector__XXX
 SG_ RPPSDBG3P_LatAuth_Inv : 39|1@0+ (1,0) [0|1] "" Vector__XXX
 SG_ RPPSDBG3P_TmOfDyAuth_Inv : 57|1@0+ (1,0) [0|1] "" Vector__XXX

BO_ 604 RPPSD_BrstGrp_Prtctd_Consecuti02: 8 TCP
 SG_ RPPSDBG4P_2DAbsPsErrEstAuth : 5|10@0+ (0.1,0) [0|102.3] "m" Vector__XXX
 SG_ RPPSDBG4P_BrstID : 7|2@0+ (1,0) [0|3] "" Vector__XXX
 SG_ RPPSDBG4P_AbsHdgErrEstAuth : 10|7@0+ (0.5,0) [0|63.5] "deg" Vector__XXX
 SG_ RPPSDBG4P_2DAbsPsErrEstAuth_Inv : 11|1@0+ (1,0) [0|1] "" Vector__XXX
 SG_ RPPSDBG4P_CldrDyAuth : 18|9@0+ (1,0) [0|511] "day" Vector__XXX
 SG_ RPPSDBG4P_AbsHdgErrEstAuth_Inv : 19|1@0+ (1,0) [0|1] "" Vector__XXX
 SG_ RPPSDBG4P_SigAcqTmAuth : 24|32@0+ (1,0) [0|4.29497e+009] "ms" Vector__XXX
 SG_ RPPSDBG4P_CldrDyAuth_Inv : 25|1@0+ (1,0) [0|1] "" Vector__XXX
 SG_ RPPSDBG4P_SigAcqTmAuth_Inv : 56|1@0+ (1,0) [0|1] "" Vector__XXX

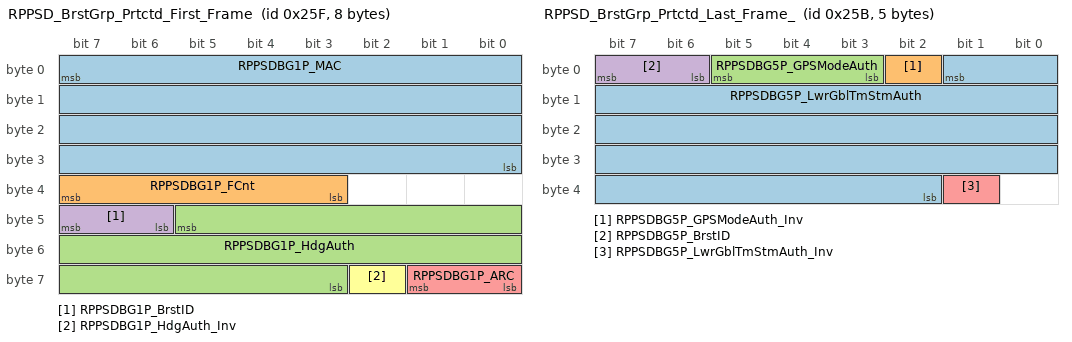
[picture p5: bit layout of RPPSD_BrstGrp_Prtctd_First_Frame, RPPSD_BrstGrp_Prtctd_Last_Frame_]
BO_ 607 RPPSD_BrstGrp_Prtctd_First_Frame: 8 TCP
 SG_ RPPSDBG1P_MAC : 7|32@0+ (1,0) [0|4.29497e+009] "" Vector__XXX
 SG_ RPPSDBG1P_FCnt : 39|5@0+ (1,0) [0|31] "" Vector__XXX
 SG_ RPPSDBG1P_HdgAuth : 45|19@0+ (0.001,0) [0|524.287] "deg" Vector__XXX
 SG_ RPPSDBG1P_BrstID : 47|2@0+ (1,0) [0|3] "" Vector__XXX
 SG_ RPPSDBG1P_ARC : 57|2@0+ (1,0) [0|3] "" Vector__XXX
 SG_ RPPSDBG1P_HdgAuth_Inv : 58|1@0+ (1,0) [0|1] "" Vector__XXX

BO_ 603 RPPSD_BrstGrp_Prtctd_Last_Frame_: 5 TCP
 SG_ RPPSDBG5P_LwrGblTmStmAuth : 1|32@0+ (1,0) [0|4.29497e+009] "nsec" Vector__XXX
 SG_ RPPSDBG5P_GPSModeAuth_Inv : 2|1@0+ (1,0) [0|1] "" Vector__XXX
 SG_ RPPSDBG5P_GPSModeAuth : 5|3@0+ (1,0) [0|7] "" Vector__XXX
 SG_ RPPSDBG5P_BrstID : 7|2@0+ (1,0) [0|3] "" Vector__XXX
 SG_ RPPSDBG5P_LwrGblTmStmAuth_Inv : 33|1@0+ (1,0) [0|1] "" Vector__XXX

BO_ 1153 SrlDat123_PCSM_PDU: 8 VKM
 SG_ SrlDat123_PCSM : 0|64@1+ (1,0) [0|1.84467e+019] "" Vector__XXX

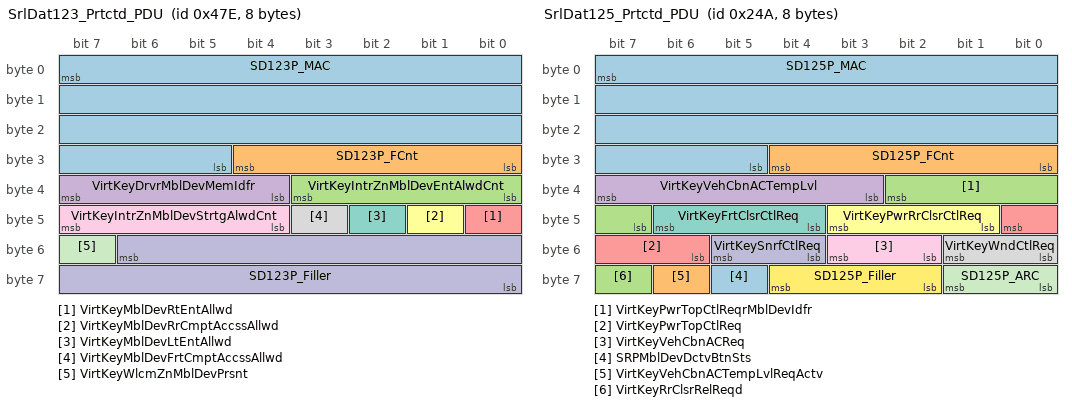
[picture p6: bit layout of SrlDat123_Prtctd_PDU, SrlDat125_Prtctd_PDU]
BO_ 1150 SrlDat123_Prtctd_PDU: 8 VKM
 SG_ SD123P_MAC : 7|27@0+ (1,0) [0|1.34218e+008] "" Vector__XXX
 SG_ SD123P_FCnt : 28|5@0+ (1,0) [0|31] "" Vector__XXX
 SG_ VirtKeyIntrZnMblDevEntAlwdCnt : 35|4@0+ (1,0) [0|15] "" Vector__XXX
 SG_ VirtKeyDrvrMblDevMemIdfr : 39|4@0+ (1,0) [0|15] "" Vector__XXX
 SG_ VirtKeyMblDevRtEntAllwd : 40|1@0+ (1,0) [0|1] "" Vector__XXX
 SG_ VirtKeyMblDevRrCmptAccssAllwd : 41|1@0+ (1,0) [0|1] "" Vector__XXX
 SG_ VirtKeyMblDevLtEntAllwd : 42|1@0+ (1,0) [0|1] "" Vector__XXX
 SG_ VirtKeyMblDevFrtCmptAccssAllwd : 43|1@0+ (1,0) [0|1] "" Vector__XXX
 SG_ VirtKeyIntrZnMblDevStrtgAlwdCnt : 47|4@0+ (1,0) [0|15] "" Vector__XXX
 SG_ SD123P_Filler : 54|15@0+ (1,0) [0|32767] "" Vector__XXX
 SG_ VirtKeyWlcmZnMblDevPrsnt : 55|1@0+ (1,0) [0|1] "" Vector__XXX

BO_ 1152 SrlDat124_PCSM_PDU: 8 VKM
 SG_ SrlDat124_PCSM : 0|64@1+ (1,0) [0|1.84467e+019] "" Vector__XXX

BO_ 1149 SrlDat124_Prtctd_PDU: 8 VKM
 SG_ SD124P_MAC : 7|27@0+ (1,0) [0|1.34218e+008] "" Vector__XXX
 SG_ SD124P_FCnt : 28|5@0+ (1,0) [0|31] "" Vector__XXX
 SG_ VirtKeyAllDrLckReqd : 32|1@0+ (1,0) [0|1] "" Vector__XXX
 SG_ VirtKeyPncReq : 34|2@0+ (1,0) [0|2] "" Vector__XXX
 SG_ VirtKeyFobAvlReq : 36|2@0+ (1,0) [0|2] "" Vector__XXX
 SG_ VirtKeyRmtLctrReq : 39|3@0+ (1,0) [0|4] "" Vector__XXX
 SG_ SRPCrsFrtInSftBtnMblDevSts : 40|1@0+ (1,0) [0|1] "" Vector__XXX
 SG_ SRPCrsBkInSftBtnMblDevSts : 41|1@0+ (1,0) [0|1] "" Vector__XXX
 SG_ VirtKeyRrClsrUnlckReqd : 42|1@0+ (1,0) [0|1] "" Vector__XXX
 SG_ VirtKeyRrClsrLckReqd : 43|1@0+ (1,0) [0|1] "" Vector__XXX
 SG_ VirtKeyFrtClsrUnlckReqd : 44|1@0+ (1,0) [0|1] "" Vector__XXX
 SG_ VirtKeyFrtClsrLckReqd : 45|1@0+ (1,0) [0|1] "" Vector__XXX
 SG_ VirtKeyDrvrDrUnlckReqd : 46|1@0+ (1,0) [0|1] "" Vector__XXX
 SG_ VirtKeyAllDrUnlckReqd : 47|1@0+ (1,0) [0|1] "" Vector__XXX
 SG_ SD124P_Filler : 49|8@0+ (1,0) [0|255] "" Vector__XXX
 SG_ SRPExplrModeSftBtnMblDevSts : 50|1@0+ (1,0) [0|1] "" Vector__XXX
 SG_ SRPSrchingSftBtnMblDevSts : 51|1@0+ (1,0) [0|1] "" Vector__XXX
 SG_ SRPRtSftBtnMblDevSts : 52|1@0+ (1,0) [0|1] "" Vector__XXX
 SG_ SRPPrlllPrkSftBtnMblDevSts : 53|1@0+ (1,0) [0|1] "" Vector__XXX
 SG_ SRPLtSftBtnMblDevSts : 54|1@0+ (1,0) [0|1] "" Vector__XXX
 SG_ SRPExtPrkSftBtnMblDevSts : 55|1@0+ (1,0) [0|1] "" Vector__XXX
 SG_ SD124P_ARC : 57|2@0+ (1,0) [0|3] "" Vector__XXX

BO_ 972 SrlDat125_PCSM_PDU: 8 VKM
 SG_ SrlDat125_PCSM : 0|64@1+ (1,0) [0|1.84467e+019] "" Vector__XXX

BO_ 586 SrlDat125_Prtctd_PDU: 8 VKM
 SG_ SD125P_MAC : 7|27@0+ (1,0) [0|1.34218e+008] "" Vector__XXX
 SG_ SD125P_FCnt : 28|5@0+ (1,0) [0|31] "" Vector__XXX
 SG_ VirtKeyPwrTopCtlReqrMblDevIdfr : 34|4@0+ (1,0) [0|15] "" Vector__XXX
 SG_ VirtKeyVehCbnACTempLvl : 39|5@0+ (0.5,16) [16|31.5] "Deg C" Vector__XXX
 SG_ VirtKeyPwrTopCtlReq : 40|3@0+ (1,0) [0|4] "" Vector__XXX
 SG_ VirtKeyPwrRrClsrCtlReq : 43|3@0+ (1,0) [0|4] "" Vector__XXX
 SG_ VirtKeyFrtClsrCtlReq : 46|3@0+ (1,0) [0|5] "" Vector__XXX
 SG_ VirtKeyWndCtlReq : 49|2@0+ (1,0) [0|3] "" Vector__XXX
 SG_ VirtKeyVehCbnACReq : 51|2@0+ (1,0) [0|2] "" Vector__XXX
 SG_ VirtKeySnrfCtlReq : 53|2@0+ (1,0) [0|3] "" Vector__XXX
 SG_ SD125P_ARC : 57|2@0+ (1,0) [0|3] "Counts" Vector__XXX
 SG_ SD125P_Filler : 60|3@0+ (1,0) [0|7] "" Vector__XXX
 SG_ SRPMblDevDctvBtnSts : 61|1@0+ (1,0) [0|1] "" Vector__XXX
 SG_ VirtKeyVehCbnACTempLvlReqActv : 62|1@0+ (1,0) [0|1] "" Vector__XXX
 SG_ VirtKeyRrClsrRelReqd : 63|1@0+ (1,0) [0|1] "" Vector__XXX

BO_ 1151 SrlDat126_PCSM_PDU: 8 CGM
 SG_ SrlDat126_PCSM : 0|64@1+ (1,0) [0|1.84467e+019] "" TCP,IPC,IPC_INT,VCU

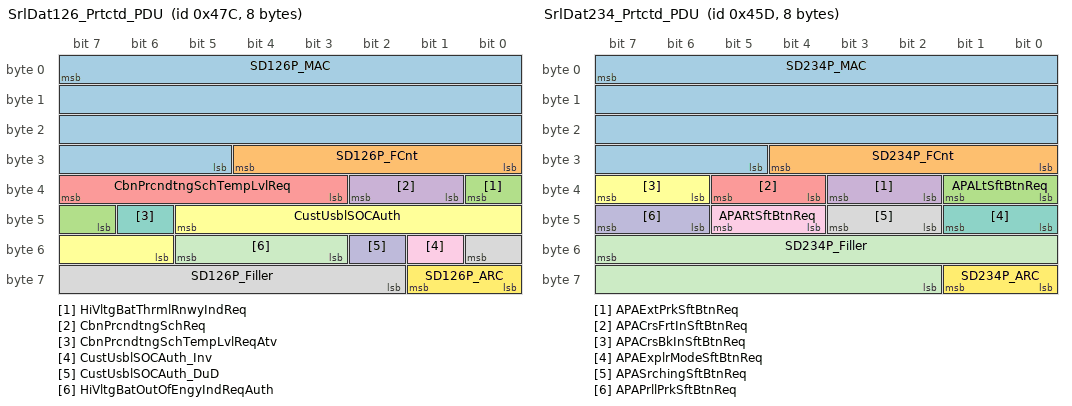
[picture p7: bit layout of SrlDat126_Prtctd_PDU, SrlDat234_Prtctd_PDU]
BO_ 1148 SrlDat126_Prtctd_PDU: 8 CGM
 SG_ SD126P_MAC : 7|27@0+ (1,0) [0|1.34218e+008] "" TCP,IPC,IPC_INT,VCU
 SG_ SD126P_FCnt : 28|5@0+ (1,0) [0|31] "" TCP,IPC,IPC_INT,VCU
 SG_ HiVltgBatThrmlRnwyIndReq : 32|2@0+ (1,0) [0|3] "" TCP,IPC,IPC_INT,VCU
 SG_ CbnPrcndtngSchReq : 34|2@0+ (1,0) [0|3] "" TCP,IPC,IPC_INT,VCU
 SG_ CbnPrcndtngSchTempLvlReq : 39|5@0+ (0.5,16) [16|31.5] "Deg C" TCP,IPC,IPC_INT,VCU
 SG_ CustUsblSOCAuth : 45|8@0+ (0.392157,0) [0|100] "%" TCP,IPC,IPC_INT,VCU
 SG_ CbnPrcndtngSchTempLvlReqAtv : 46|1@0+ (1,0) [0|1] "" TCP,IPC,IPC_INT,VCU
 SG_ SD126P_Filler : 48|7@0+ (1,0) [0|127] "" TCP,IPC,IPC_INT,VCU
 SG_ CustUsblSOCAuth_Inv : 49|1@0+ (1,0) [0|1] "" TCP,IPC,IPC_INT,VCU
 SG_ CustUsblSOCAuth_DuD : 50|1@0+ (1,0) [0|1] "" TCP,IPC,IPC_INT,VCU
 SG_ HiVltgBatOutOfEngyIndReqAuth : 53|3@0+ (1,0) [0|4] "" TCP,IPC,IPC_INT,VCU
 SG_ SD126P_ARC : 57|2@0+ (1,0) [0|3] "" TCP,IPC,IPC_INT,VCU

BO_ 694 SrlDat15_PCSM_PDU: 8 CGM
 SG_ SrlDat15_PCSM : 0|64@1+ (1,0) [0|1.84467e+019] "" IPC,IPC_INT,VCU

BO_ 635 SrlDat15_Prtctd_PDU: 8 CGM
 SG_ SD15P_MAC : 7|27@0+ (1,0) [0|1.34218e+008] "" IPC,IPC_INT,VCU
 SG_ SD15P_FCnt : 28|5@0+ (1,0) [0|31] "" IPC,IPC_INT,VCU
 SG_ EPBSP_ElecPrkBrkAvlStsAuth : 33|2@0+ (1,0) [0|2] "" IPC,IPC_INT,VCU
 SG_ EPBSP_ElecPrkBrkApplStsAuth : 36|3@0+ (1,0) [0|4] "" VKM,CSM,CSM_AV,IPC,IPC_INT,VCU
 SG_ EPBSP_EPBSysBrkLgtsReqdAuth : 37|1@0+ (1,0) [0|1] "" IPC,IPC_INT,VCU
 SG_ EPBSP_BrkSysBrkLgtsReqdAuth : 38|1@0+ (1,0) [0|1] "" IPC,IPC_INT,VCU
 SG_ DMCP_EnvIdRsp2Auth : 39|1@0+ (1,0) [0|1] "" IPC,IPC_INT,VCU
 SG_ TBIP_TrlrBrkgGainSetAuth : 43|8@0+ (0.392157,0) [0|100] "%" CSM,CSM_AV,IPC,IPC_INT,VCU
 SG_ TBIP_TrlrBrkDsbldIndOnAuth : 44|1@0+ (1,0) [0|1] "" IPC,IPC_INT,VCU
 SG_ TBIP_ServTrlrBrkgSysIndOnAuth : 45|1@0+ (1,0) [0|1] "" IPC,IPC_INT,VCU
 SG_ TBIP_CkTrlrIndOnAuth : 46|1@0+ (1,0) [0|1] "" IPC,IPC_INT,VCU
 SG_ EPBSP_TrlrBrkgSysBrkLgtsRqdAuth : 47|1@0+ (1,0) [0|1] "" IPC,IPC_INT,VCU
 SG_ SD15P_ARC : 49|2@0+ (1,0) [0|3] "" IPC,IPC_INT,VCU
 SG_ TBIP_TrlrWrgFltIndOnAuth : 50|1@0+ (1,0) [0|1] "" IPC,IPC_INT,VCU
 SG_ TBIP_TrlrBrkgGainSetIndOnAuth : 51|1@0+ (1,0) [0|1] "" IPC,IPC_INT,VCU
 SG_ SD15P_Filler : 58|3@0+ (1,0) [0|7] "" IPC,IPC_INT,VCU
 SG_ BrkSysActvHldActv : 59|1@0+ (1,0) [0|1] "" IPC,IPC_INT,VCU
 SG_ BrkSysVehHldReqShfPrk : 60|1@0+ (1,0) [0|1] "" IPC,IPC_INT,VCU
 SG_ ElecPrkBrkMnPriPerfRdcd : 61|1@0+ (1,0) [0|1] "" IPC,IPC_INT,VCU
 SG_ TrlrBrkgRdcdIndOn : 62|1@0+ (1,0) [0|1] "" IPC,IPC_INT,VCU
 SG_ TrlrBrkgHldLstKnwnGainIndOn : 63|1@0+ (1,0) [0|1] "" IPC,IPC_INT,VCU

BO_ 1404 SrlDat22_PCSM_PDU: 8 CGM
 SG_ SrlDat22_PCSM : 0|64@1+ (1,0) [0|1.84467e+019] "" TCP,VKM,IPC,IPC_INT,VCU

BO_ 879 SrlDat22_Prtctd_PDU: 8 CGM
 SG_ SD22P_MAC : 7|27@0+ (1,0) [0|1.34218e+008] "" TCP,VKM,IPC,IPC_INT,VCU
 SG_ SD22P_FCnt : 28|5@0+ (1,0) [0|31] "" TCP,VKM,IPC,IPC_INT,VCU
 SG_ EGI3P_CnvtTpSpLimRspValAuth : 36|8@0+ (2,0) [0|510] "kph" TCP,VKM,IPC,IPC_INT,VCU
 SG_ EGI3P_CnvtTpSpLimRspTypAuth : 39|3@0+ (1,0) [0|6] "" TCP,VKM,IPC,IPC_INT,VCU
 SG_ PSP_PrkNeutSwStatAuth_Inv : 40|1@0+ (1,0) [0|1] "" TCP,VKM,IPC,IPC_INT,VCU
 SG_ PSP_PrkNeutSwStatAuth : 41|1@0+ (1,0) [0|1] "" TCP,VKM,IPC,IPC_INT,VCU
 SG_ PSP_EngRnngAuth : 42|1@0+ (1,0) [0|1] "" AMP,HVAC_FP_F,HVAC_FP_R,ICS_Info,PDR,MFC,RadioLow,TCP,VKM,CSM,CSM_AV,IPC,IPC_INT,VCU,WCM
 SG_ PSP_ClchBtmTrvlAchvdAuth_Inv : 43|1@0+ (1,0) [0|1] "" TCP,VKM,CSM,CSM_AV,IPC,IPC_INT,VCU
 SG_ PSP_ClchBtmTrvlAchvdAuth : 44|1@0+ (1,0) [0|1] "" TCP,VKM,CSM,CSM_AV,IPC,IPC_INT,VCU
 SG_ SD22P_ARC : 49|2@0+ (1,0) [0|3] "" TCP,VKM,IPC,IPC_INT,VCU
 SG_ PSP_VehTheftImbChlgRespStsAuth : 51|2@0+ (1,0) [0|2] "" TCP,VKM,IPC,IPC_INT,VCU
 SG_ PSP_RmtVehStrtEngRnngAuth : 52|1@0+ (1,0) [0|1] "" RadioLow,TCP,VKM,CSM,CSM_AV,IPC,IPC_INT,VCU
 SG_ PSP_PwrtrnCrnkAbrtdAuth : 53|1@0+ (1,0) [0|1] "" TCP,VKM,IPC,IPC_INT,VCU
 SG_ PSP_PrplSysStlActvAuth : 54|1@0+ (1,0) [0|1] "" TCP,VKM,IPC,IPC_INT,VCU
 SG_ PSP_PrplSysActvAuth : 55|1@0+ (1,0) [0|1] "" HVAC_FP_F,ICS_Info,TCP,VKM,CSM,CSM_AV,IPC,IPC_INT,VCU,WCM,WCM2,WCM3,WCM4
 SG_ SD22P_Filler : 62|7@0+ (1,0) [0|127] "" TCP,VKM,IPC,IPC_INT,VCU
 SG_ PrplBrkThrotOvrrdReqd : 63|1@0+ (1,0) [0|1] "" TCP,VKM,IPC,IPC_INT,VCU

BO_ 1949 SrlDat234_PCSM_PDU: 8 CGM
 SG_ SrlDat234_PCSM : 0|64@1+ (1,0) [0|1.84467e+019] "" VKM

BO_ 1117 SrlDat234_Prtctd_PDU: 8 CGM
 SG_ SD234P_MAC : 7|27@0+ (1,0) [0|1.34218e+008] "" VKM
 SG_ SD234P_FCnt : 28|5@0+ (1,0) [0|31] "" VKM
 SG_ APALtSftBtnReq : 33|2@0+ (1,0) [0|3] "" VKM,VCU
 SG_ APAExtPrkSftBtnReq : 35|2@0+ (1,0) [0|3] "" VKM,VCU
 SG_ APACrsFrtInSftBtnReq : 37|2@0+ (1,0) [0|3] "" VKM,VCU
 SG_ APACrsBkInSftBtnReq : 39|2@0+ (1,0) [0|3] "" VKM,VCU
 SG_ APAExplrModeSftBtnReq : 41|2@0+ (1,0) [0|3] "" VKM
 SG_ APASrchingSftBtnReq : 43|2@0+ (1,0) [0|3] "" VKM,VCU
 SG_ APARtSftBtnReq : 45|2@0+ (1,0) [0|3] "" VKM,VCU
 SG_ APAPrllPrkSftBtnReq : 47|2@0+ (1,0) [0|3] "" VKM,VCU
 SG_ SD234P_Filler : 55|14@0+ (1,0) [0|16383] "" VKM
 SG_ SD234P_ARC : 57|2@0+ (1,0) [0|3] "" VKM

BO_ 1958 SrlDat253_PCSM_PDU: 8 TCP
 SG_ SrlDat253_PCSM : 0|64@1+ (1,0) [0|1.84467e+019] "" Vector__XXX

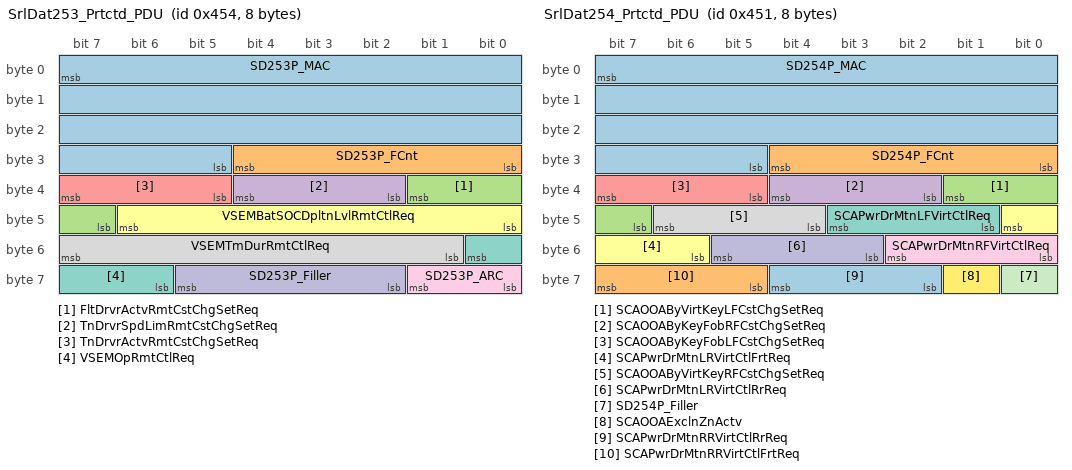
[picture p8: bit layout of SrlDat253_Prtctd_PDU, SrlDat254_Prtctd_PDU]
BO_ 1108 SrlDat253_Prtctd_PDU: 8 TCP
 SG_ SD253P_MAC : 7|27@0+ (1,0) [0|1.34218e+008] "" Vector__XXX
 SG_ SD253P_FCnt : 28|5@0+ (1,0) [0|31] "" Vector__XXX
 SG_ FltDrvrActvRmtCstChgSetReq : 33|3@0+ (1,0) [0|2] "" Vector__XXX
 SG_ TnDrvrSpdLimRmtCstChgSetReq : 36|3@0+ (1,0) [0|2] "" Vector__XXX
 SG_ TnDrvrActvRmtCstChgSetReq : 39|3@0+ (1,0) [0|2] "" Vector__XXX
 SG_ VSEMBatSOCDpltnLvlRmtCtlReq : 46|7@0+ (1,0) [0|127] "%" Vector__XXX
 SG_ VSEMOpRmtCtlReq : 48|3@0+ (1,0) [0|5] "" Vector__XXX
 SG_ VSEMTmDurRmtCtlReq : 55|7@0+ (15,0) [0|1905] "min" Vector__XXX
 SG_ SD253P_ARC : 57|2@0+ (1,0) [0|3] "" Vector__XXX
 SG_ SD253P_Filler : 61|4@0+ (1,0) [0|15] "" Vector__XXX

BO_ 1107 SrlDat254_PCSM_PDU: 8 VCU
 SG_ SrlDat254_PCSM : 0|64@1+ (1,0) [0|1.84467e+019] "" Vector__XXX

BO_ 1105 SrlDat254_Prtctd_PDU: 8 VCU
 SG_ SD254P_MAC : 7|27@0+ (1,0) [0|1.34218e+008] "" Vector__XXX
 SG_ SD254P_FCnt : 28|5@0+ (1,0) [0|31] "" Vector__XXX
 SG_ SCAOOAByVirtKeyLFCstChgSetReq : 33|3@0+ (1,0) [0|2] "" Vector__XXX
 SG_ SCAOOAByKeyFobRFCstChgSetReq : 36|3@0+ (1,0) [0|2] "" Vector__XXX
 SG_ SCAOOAByKeyFobLFCstChgSetReq : 39|3@0+ (1,0) [0|2] "" Vector__XXX
 SG_ SCAPwrDrMtnLRVirtCtlFrtReq : 40|3@0+ (1,0) [0|4] "" Vector__XXX
 SG_ SCAPwrDrMtnLFVirtCtlReq : 43|3@0+ (1,0) [0|4] "" Vector__XXX
 SG_ SCAOOAByVirtKeyRFCstChgSetReq : 46|3@0+ (1,0) [0|2] "" Vector__XXX
 SG_ SCAPwrDrMtnRFVirtCtlReq : 50|3@0+ (1,0) [0|4] "" Vector__XXX
 SG_ SCAPwrDrMtnLRVirtCtlRrReq : 53|3@0+ (1,0) [0|4] "" Vector__XXX
 SG_ SD254P_Filler : 56|1@0+ (1,0) [0|1] "" Vector__XXX
 SG_ SCAOOAExclnZnActv : 57|1@0+ (1,0) [0|1] "" Vector__XXX
 SG_ SCAPwrDrMtnRRVirtCtlRrReq : 60|3@0+ (1,0) [0|4] "" Vector__XXX
 SG_ SCAPwrDrMtnRRVirtCtlFrtReq : 63|3@0+ (1,0) [0|4] "" Vector__XXX

BO_ 1960 SrlDat255_PCSM_PDU: 8 VCU
 SG_ SrlDat255_PCSM : 0|64@1+ (1,0) [0|1.84467e+019] "" Vector__XXX

BO_ 1104 SrlDat255_Prtctd_PDU: 8 VCU
 SG_ SD255P_MAC : 7|27@0+ (1,0) [0|1.34218e+008] "" Vector__XXX
 SG_ SD255P_FCnt : 28|5@0+ (1,0) [0|31] "" Vector__XXX
 SG_ DMBlkhdDrUnltchPrkCstChgSetReq : 33|3@0+ (1,0) [0|2] "" Vector__XXX
 SG_ DMBlkhdDrUnlckPrkCstChgSetReq : 36|3@0+ (1,0) [0|2] "" Vector__XXX
 SG_ DMBlkhdDrOpnVehOffCstChgSetReq : 39|3@0+ (1,0) [0|2] "" Vector__XXX
 SG_ DMPDDOBlkhdDrOpnLFCstChgSetReq : 40|3@0+ (1,0) [0|2] "" Vector__XXX
 SG_ DMDrvrDrUnlckPrkCstChgSetReq : 43|3@0+ (1,0) [0|2] "" Vector__XXX
 SG_ DMCrbsdDrUnlckPrkCstChgSetReq : 46|3@0+ (1,0) [0|2] "" Vector__XXX
 SG_ RrClsrAccssVirtCtlReq : 48|2@0+ (1,0) [0|3] "" Vector__XXX
 SG_ FrtClsrAccssVirtCtlReq : 50|2@0+ (1,0) [0|3] "" Vector__XXX
 SG_ DMPDDOBlkhdDrOpnRFCstChgSetReq : 53|3@0+ (1,0) [0|2] "" Vector__XXX
 SG_ SD255P_Filler : 57|2@0+ (1,0) [0|3] "" Vector__XXX
 SG_ SCAPwrDrUnlckAllVirtCtlRrReq : 58|1@0+ (1,0) [0|1] "" Vector__XXX
 SG_ SCAPwrDrUnlckAllVirtCtlFrtReq : 59|1@0+ (1,0) [0|1] "" Vector__XXX
 SG_ SCAPwrDrLckAllVirtCtlRrReq : 60|1@0+ (1,0) [0|1] "" Vector__XXX
 SG_ SCAPwrDrLckAllVirtCtlFrtReq : 61|1@0+ (1,0) [0|1] "" Vector__XXX
 SG_ RstrCstDfltReqdAuth : 62|1@0+ (1,0) [0|1] "" Vector__XXX

BO_ 1106 SrlDat257_PCSM_PDU: 8 VKM
 SG_ SrlDat257_PCSM : 0|64@1+ (1,0) [0|1.84467e+019] "" Vector__XXX

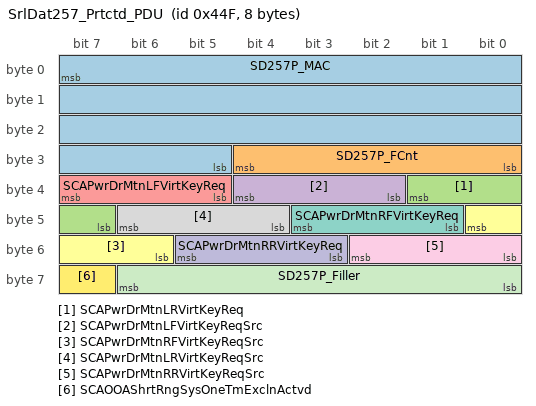
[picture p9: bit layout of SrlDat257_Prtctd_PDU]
BO_ 1103 SrlDat257_Prtctd_PDU: 8 VKM
 SG_ SD257P_MAC : 7|27@0+ (1,0) [0|1.34218e+008] "" Vector__XXX
 SG_ SD257P_FCnt : 28|5@0+ (1,0) [0|31] "" Vector__XXX
 SG_ SCAPwrDrMtnLRVirtKeyReq : 33|3@0+ (1,0) [0|4] "" Vector__XXX
 SG_ SCAPwrDrMtnLFVirtKeyReqSrc : 36|3@0+ (1,0) [0|2] "" Vector__XXX
 SG_ SCAPwrDrMtnLFVirtKeyReq : 39|3@0+ (1,0) [0|4] "" Vector__XXX
 SG_ SCAPwrDrMtnRFVirtKeyReqSrc : 40|3@0+ (1,0) [0|2] "" Vector__XXX
 SG_ SCAPwrDrMtnRFVirtKeyReq : 43|3@0+ (1,0) [0|4] "" Vector__XXX
 SG_ SCAPwrDrMtnLRVirtKeyReqSrc : 46|3@0+ (1,0) [0|2] "" Vector__XXX
 SG_ SCAPwrDrMtnRRVirtKeyReqSrc : 50|3@0+ (1,0) [0|2] "" Vector__XXX
 SG_ SCAPwrDrMtnRRVirtKeyReq : 53|3@0+ (1,0) [0|4] "" Vector__XXX
 SG_ SD257P_Filler : 62|7@0+ (1,0) [0|127] "" Vector__XXX
 SG_ SCAOOAShrtRngSysOneTmExclnActvd : 63|1@0+ (1,0) [0|1] "" Vector__XXX

BO_ 1974 SrlDat267_PCSM_PDU: 8 CGM
 SG_ SrlDat267_PCSM : 0|64@1+ (1,0) [0|1.84467e+019] "" TCP

BA_DEF_ SG_  "SignalType" STRING ;
BA_DEF_ SG_  "SignalLongName" STRING ;
BA_DEF_ BO_  "GenMsgCycleTime" INT 0 10000;
BA_DEF_ BO_  "GenMsgSendType" ENUM "cyclicX","spontanX","cyclicIfActiveX","spontanWithDelay","cyclicAndSpontanX","cyclicAndSpontanWithDelay","spontanWithRepetition","cyclicIfActiveAndSpontanWD";
BA_DEF_DEF_  "SignalType" "";
BA_DEF_DEF_  "SignalLongName" "";
BA_DEF_DEF_  "GenMsgCycleTime" 0;
BA_DEF_DEF_  "GenMsgSendType" "cyclicX";
BA_ "GenMsgCycleTime" BO_ 1345 1000;
BA_ "GenMsgCycleTime" BO_ 1294 1000;
BA_ "GenMsgCycleTime" BO_ 1137 1000;
BA_ "GenMsgCycleTime" BO_ 183 25;
BA_ "GenMsgCycleTime" BO_ 1986 1000;
BA_ "GenMsgCycleTime" BO_ 1931 1000;
BA_ "GenMsgCycleTime" BO_ 1135 1000;
BA_ "GenMsgCycleTime" BO_ 1056 1000;
BA_ "GenMsgCycleTime" BO_ 963 1000;
BA_ "GenMsgCycleTime" BO_ 964 1000;
BA_ "GenMsgCycleTime" BO_ 962 1000;
BA_ "GenMsgCycleTime" BO_ 952 500;
BA_ "GenMsgCycleTime" BO_ 953 500;
BA_ "GenMsgCycleTime" BO_ 954 500;
BA_ "GenMsgCycleTime" BO_ 1382 3500;
BA_ "GenMsgCycleTime" BO_ 1322 1000;
BA_ "GenMsgCycleTime" BO_ 1381 3500;
BA_ "GenMsgCycleTime" BO_ 1320 1000;
BA_ "GenMsgCycleTime" BO_ 1399 1000;
BA_ "GenMsgCycleTime" BO_ 870 250;
BA_ "GenMsgCycleTime" BO_ 606 100;
BA_ "GenMsgCycleTime" BO_ 605 100;
BA_ "GenMsgCycleTime" BO_ 604 100;
BA_ "GenMsgCycleTime" BO_ 607 100;
BA_ "GenMsgCycleTime" BO_ 603 100;
BA_ "GenMsgCycleTime" BO_ 1153 1000;
BA_ "GenMsgCycleTime" BO_ 1150 250;
BA_ "GenMsgCycleTime" BO_ 1152 3500;
BA_ "GenMsgCycleTime" BO_ 1149 1000;
BA_ "GenMsgCycleTime" BO_ 586 100;
BA_ "GenMsgCycleTime" BO_ 1151 3500;
BA_ "GenMsgCycleTime" BO_ 1148 1000;
BA_ "GenMsgCycleTime" BO_ 635 100;
BA_ "GenMsgCycleTime" BO_ 1404 1000;
BA_ "GenMsgCycleTime" BO_ 879 250;
BA_ "GenMsgCycleTime" BO_ 1949 3500;
BA_ "GenMsgCycleTime" BO_ 1117 1000;
BA_ "GenMsgCycleTime" BO_ 1958 3500;
BA_ "GenMsgCycleTime" BO_ 1108 1000;
BA_ "GenMsgCycleTime" BO_ 1107 3500;
BA_ "GenMsgCycleTime" BO_ 1105 1000;
BA_ "GenMsgCycleTime" BO_ 1960 3500;
BA_ "GenMsgCycleTime" BO_ 1104 1000;
BA_ "GenMsgCycleTime" BO_ 1106 3500;
BA_ "GenMsgCycleTime" BO_ 1103 1000;
BA_ "GenMsgCycleTime" BO_ 1974 3500;
BA_ "SignalLongName" SG_ 1345 EVSECmndPwrLim "Electric Vehicle Supply Equipment Commanded Power Limit";
BA_ "SignalLongName" SG_ 1345 HiVltgChrgReqdPwrLim "High Voltage Charging Requested Power Limit";
BA_ "SignalType" SG_ 1345 EVSECmndPwrLimSts "ENM";
BA_ "SignalLongName" SG_ 1345 EVSECmndPwrLimSts "Electric Vehicle Supply Equipment Commanded Power Limit Status";
BA_ "SignalLongName" SG_ 1345 EVSECmndPwrLimCpbltyPct "Electric Vehicle Supply Equipment Commanded Power Limit Capability Percent";
BA_ "SignalType" SG_ 1345 DrSeltdOtltOfPwMdVirCtlNAlwdSts "ENM";
BA_ "SignalLongName" SG_ 1345 DrSeltdOtltOfPwMdVirCtlNAlwdSts "Driver Selected Outlet Off Power Mode Virtual Control Not Allowed Status";
BA_ "SignalType" SG_ 1345 ShfFromNeutWrnIndOn "ENM";
BA_ "SignalLongName" SG_ 1345 ShfFromNeutWrnIndOn "Shift From Neutral Warning Indication On";
BA_ "SignalType" SG_ 1345 NeutCstdwnCertModeWrnIndOn "ENM";
BA_ "SignalLongName" SG_ 1345 NeutCstdwnCertModeWrnIndOn "Neutral Coastdown Certification Mode Warning Indication On";
BA_ "SignalType" SG_ 1345 EVSECmndPwrLimAval "ENM";
BA_ "SignalLongName" SG_ 1345 EVSECmndPwrLimAval "Electric Vehicle Supply Equipment Commanded Power Limit Available";
BA_ "SignalType" SG_ 1345 OnbrdOtlt1OprtlSts "ENM";
BA_ "SignalLongName" SG_ 1345 OnbrdOtlt1OprtlSts "Onboard Outlet 1 Operational Status";
BA_ "SignalType" SG_ 1345 OffbrdOtltsOvrloadIndOn "ENM";
BA_ "SignalLongName" SG_ 1345 OffbrdOtltsOvrloadIndOn "Offboard Outlets Overload Indication On";
BA_ "SignalType" SG_ 1345 DrvrSeltdOtltOffPwrMdVirCtlAvl "ENM";
BA_ "SignalLongName" SG_ 1345 DrvrSeltdOtltOffPwrMdVirCtlAvl "Driver Selected Outlet Off Power Mode Virtual Control Available";
BA_ "SignalType" SG_ 1345 DrvrSeltdOtltOffPwMdVirCtlAllwd "ENM";
BA_ "SignalLongName" SG_ 1345 DrvrSeltdOtltOffPwMdVirCtlAllwd "Driver Selected Outlet Off Power Mode Virtual Control Allowed";
BA_ "SignalType" SG_ 1345 DrSeltdOtltOffPwMdVirCtlSeltnVl "ENM";
BA_ "SignalLongName" SG_ 1345 DrSeltdOtltOffPwMdVirCtlSeltnVl "Driver Selected Outlet Off Power Mode Virtual Control Selection Value";
BA_ "SignalType" SG_ 1345 OtltsOffPwrMdTmrActv "ENM";
BA_ "SignalLongName" SG_ 1345 OtltsOffPwrMdTmrActv "Outlets Off Power Mode Timer Active";
BA_ "SignalType" SG_ 1345 OnbrdOtltsOvrloadIndOn "ENM";
BA_ "SignalLongName" SG_ 1345 OnbrdOtltsOvrloadIndOn "Onboard Outlets Overload Indication On";
BA_ "SignalType" SG_ 1345 OnbrdOtlt3OprtlSts "ENM";
BA_ "SignalLongName" SG_ 1345 OnbrdOtlt3OprtlSts "Onboard Outlet 3 Operational Status";
BA_ "SignalType" SG_ 1345 OnbrdOtlt2OprtlSts "ENM";
BA_ "SignalLongName" SG_ 1345 OnbrdOtlt2OprtlSts "Onboard Outlet 2 Operational Status";
BA_ "SignalType" SG_ 1294 SecRowLtPsStBltRmOccpSts "ENM";
BA_ "SignalLongName" SG_ 1294 SecRowLtPsStBltRmOccpSts "Second Row Seat Belt and Occupancy Status Information : Second Row Left Passenger Seat Belt Reminder Occupancy Status";
BA_ "SignalType" SG_ 1294 SecRowCntrPsStBltSts_Inv "ENM";
BA_ "SignalLongName" SG_ 1294 SecRowCntrPsStBltSts_Inv "Second Row Seat Belt and Occupancy Status Information : Second Row Center Passenger Seat Belt Status Invalid";
BA_ "SignalType" SG_ 1294 SecRowCntrPsStBltSts "ENM";
BA_ "SignalLongName" SG_ 1294 SecRowCntrPsStBltSts "Second Row Seat Belt and Occupancy Status Information : Second Row Center Passenger Seat Belt Status";
BA_ "SignalType" SG_ 1294 SecRowCntrPsStBltRmOccpSts_Inv "ENM";
BA_ "SignalLongName" SG_ 1294 SecRowCntrPsStBltRmOccpSts_Inv "Second Row Seat Belt and Occupancy Status Information : Second Row Center Passenger Seat Belt Reminder Occupancy Status Invalid";
BA_ "SignalType" SG_ 1294 SecRowCntrPsStBltRmOccpSts "ENM";
BA_ "SignalLongName" SG_ 1294 SecRowCntrPsStBltRmOccpSts "Second Row Seat Belt and Occupancy Status Information : Second Row Center Passenger Seat Belt Reminder Occupancy Status";
BA_ "SignalType" SG_ 1294 SecRowRtPsStBltSts "ENM";
BA_ "SignalLongName" SG_ 1294 SecRowRtPsStBltSts "Second Row Seat Belt and Occupancy Status Information : Second Row Right Passenger Seat Belt Status";
BA_ "SignalType" SG_ 1294 SecRowRtPsStBltRmOccpSts_Inv "ENM";
BA_ "SignalLongName" SG_ 1294 SecRowRtPsStBltRmOccpSts_Inv "Second Row Seat Belt and Occupancy Status Information : Second Row Right Passenger Seat Belt Reminder Occupancy Status Invalid";
BA_ "SignalType" SG_ 1294 SecRowRtPsStBltRmOccpSts "ENM";
BA_ "SignalLongName" SG_ 1294 SecRowRtPsStBltRmOccpSts "Second Row Seat Belt and Occupancy Status Information : Second Row Right Passenger Seat Belt Reminder Occupancy Status";
BA_ "SignalType" SG_ 1294 SecRowLtPsStBltSts_Inv "ENM";
BA_ "SignalLongName" SG_ 1294 SecRowLtPsStBltSts_Inv "Second Row Seat Belt and Occupancy Status Information : Second Row Left Passenger Seat Belt Status Invalid";
BA_ "SignalType" SG_ 1294 SecRowLtPsStBltSts "ENM";
BA_ "SignalLongName" SG_ 1294 SecRowLtPsStBltSts "Second Row Seat Belt and Occupancy Status Information : Second Row Left Passenger Seat Belt Status";
BA_ "SignalType" SG_ 1294 SecRowLtPsStBltRmOccpSts_Inv "ENM";
BA_ "SignalLongName" SG_ 1294 SecRowLtPsStBltRmOccpSts_Inv "Second Row Seat Belt and Occupancy Status Information : Second Row Left Passenger Seat Belt Reminder Occupancy Status Invalid";
BA_ "SignalType" SG_ 1294 ThrdRowCntrPsStBltSts_Inv "ENM";
BA_ "SignalLongName" SG_ 1294 ThrdRowCntrPsStBltSts_Inv "Third Row Seat Belt and Occupancy Status Information : Third Row Center Passenger Seat Belt Status Invalid";
BA_ "SignalType" SG_ 1294 ThrdRowCntrPsStBltSts "ENM";
BA_ "SignalLongName" SG_ 1294 ThrdRowCntrPsStBltSts "Third Row Seat Belt and Occupancy Status Information : Third Row Center Passenger Seat Belt Status";
BA_ "SignalType" SG_ 1294 ThrdRowCntrPsStBltRmOccpSts_Inv "ENM";
BA_ "SignalLongName" SG_ 1294 ThrdRowCntrPsStBltRmOccpSts_Inv "Third Row Seat Belt and Occupancy Status Information : Third Row Center Passenger Seat Belt Reminder Occupancy Status Invalid";
BA_ "SignalType" SG_ 1294 ThrdRowCntrPsStBltRmOccpSts "ENM";
BA_ "SignalLongName" SG_ 1294 ThrdRowCntrPsStBltRmOccpSts "Third Row Seat Belt and Occupancy Status Information : Third Row Center Passenger Seat Belt Reminder Occupancy Status";
BA_ "SignalType" SG_ 1294 SecRowRtPsStBltSts_Inv "ENM";
BA_ "SignalLongName" SG_ 1294 SecRowRtPsStBltSts_Inv "Second Row Seat Belt and Occupancy Status Information : Second Row Right Passenger Seat Belt Status Invalid";
BA_ "SignalType" SG_ 1294 ThrdRowRtPsStBltRmOccpSts "ENM";
BA_ "SignalLongName" SG_ 1294 ThrdRowRtPsStBltRmOccpSts "Third Row Seat Belt and Occupancy Status Information : Third Row Right Passenger Seat Belt Reminder Occupancy Status";
BA_ "SignalType" SG_ 1294 ThrdRowLtPsStBltSts_Inv "ENM";
BA_ "SignalLongName" SG_ 1294 ThrdRowLtPsStBltSts_Inv "Third Row Seat Belt and Occupancy Status Information : Third Row Left Passenger Seat Belt Status Invalid";
BA_ "SignalType" SG_ 1294 ThrdRowLtPsStBltSts "ENM";
BA_ "SignalLongName" SG_ 1294 ThrdRowLtPsStBltSts "Third Row Seat Belt and Occupancy Status Information : Third Row Left Passenger Seat Belt Status";
BA_ "SignalType" SG_ 1294 ThrdRowLtPsStBltRmOccpSts_Inv "ENM";
BA_ "SignalLongName" SG_ 1294 ThrdRowLtPsStBltRmOccpSts_Inv "Third Row Seat Belt and Occupancy Status Information : Third Row Left Passenger Seat Belt Reminder Occupancy Status Invalid";
BA_ "SignalType" SG_ 1294 ThrdRowLtPsStBltRmOccpSts "ENM";
BA_ "SignalLongName" SG_ 1294 ThrdRowLtPsStBltRmOccpSts "Third Row Seat Belt and Occupancy Status Information : Third Row Left Passenger Seat Belt Reminder Occupancy Status";
BA_ "SignalType" SG_ 1294 ThrdRowRtPsStBltSts_Inv "ENM";
BA_ "SignalLongName" SG_ 1294 ThrdRowRtPsStBltSts_Inv "Third Row Seat Belt and Occupancy Status Information : Third Row Right Passenger Seat Belt Status Invalid";
BA_ "SignalType" SG_ 1294 ThrdRowRtPsStBltSts "ENM";
BA_ "SignalLongName" SG_ 1294 ThrdRowRtPsStBltSts "Third Row Seat Belt and Occupancy Status Information : Third Row Right Passenger Seat Belt Status";
BA_ "SignalType" SG_ 1294 ThrdRowRtPsStBltRmOccpSts_Inv "ENM";
BA_ "SignalLongName" SG_ 1294 ThrdRowRtPsStBltRmOccpSts_Inv "Third Row Seat Belt and Occupancy Status Information : Third Row Right Passenger Seat Belt Reminder Occupancy Status Invalid";
BA_ "SignalLongName" SG_ 1137 HiVltgBatPrplRngMinPrjtd "High Voltage Battery Propulsion Range Minimum Projected";
BA_ "SignalType" SG_ 1137 ChrgSysCommActvReqd "ENM";
BA_ "SignalLongName" SG_ 1137 ChrgSysCommActvReqd "Charging System Communication Active Requested";
BA_ "SignalLongName" SG_ 1137 OffbrdEngyXferMinSOCResp "Offboard Energy Transfer Information : Offboard Energy Transfer Minimum State of Charge Response";
BA_ "SignalLongName" SG_ 1137 OffbrdOtltsEleclEngyPwrLvlPct "Offboard Outlets Electrical Energy Power Level Percent";
BA_ "SignalType" SG_ 1137 OffbrdEngyXferMinSOCResp_DuD "ENM";
BA_ "SignalLongName" SG_ 1137 OffbrdEngyXferMinSOCResp_DuD "Offboard Energy Transfer Information : Offboard Energy Transfer Minimum State of Charge Response Don't Use Data";
BA_ "SignalLongName" SG_ 1137 OtltsOfPwMdElelEngUdThDschg "Outlets Off Power Mode Electrical Energy Information : Outlets Off Power Mode Electrical Energy Used This Discharge";
BA_ "SignalLongName" SG_ 1137 OtltsOffPwrMdSysActvTm "Outlets Off Power Mode System Active Information : Outlets Off Power Mode System Active Time";
BA_ "SignalType" SG_ 1137 OtltsOfPwMdElelEngUdThDschg_DuD "ENM";
BA_ "SignalLongName" SG_ 1137 OtltsOfPwMdElelEngUdThDschg_DuD "Outlets Off Power Mode Electrical Energy Information : Outlets Off Power Mode Electrical Energy Used This Discharge Don't Use Data";
BA_ "SignalType" SG_ 1137 OtltsOffPwrMdTmrOpCstSetVal "ENM";
BA_ "SignalLongName" SG_ 1137 OtltsOffPwrMdTmrOpCstSetVal "Outlets Off Power Mode Timer Operation Customization Setting Value";
BA_ "SignalType" SG_ 1137 OtltsOffPwrMdSysActvTm_DuD "ENM";
BA_ "SignalLongName" SG_ 1137 OtltsOffPwrMdSysActvTm_DuD "Outlets Off Power Mode System Active Information : Outlets Off Power Mode System Active Time Don't Use Data";
BA_ "SignalType" SG_ 183 HiVltgChrgCtlPilotDiagDsblReqd "ENM";
BA_ "SignalLongName" SG_ 183 HiVltgChrgCtlPilotDiagDsblReqd "Serial Data 274 : High Voltage Charging Control Pilot Diagnostic Disable Requested";
BA_ "SignalLongName" SG_ 183 SD274_ARC "Serial Data 274 : Alive Rolling Count";
BA_ "SignalType" SG_ 183 HiVltgChrgVntilationSwCmd "ENM";
BA_ "SignalLongName" SG_ 183 HiVltgChrgVntilationSwCmd "Serial Data 274 : High Voltage Charging Ventilation Switch Command";
BA_ "SignalType" SG_ 183 HiVltgChrgS2SwCmd "ENM";
BA_ "SignalLongName" SG_ 183 HiVltgChrgS2SwCmd "Serial Data 274 : High Voltage Charging S2 Switch Command";
BA_ "SignalLongName" SG_ 1986 IndHrztlPsFrtLtOtbrdOtltManSet "Indication HVAC Settings 1 : Indication Horizontal Position Front Left Outboard Outlet Manual Setting";
BA_ "SignalLongName" SG_ 1986 IndHrztlPsFrtLtInbrdOtltManSet "Indication HVAC Settings 1 : Indication Horizontal Position Front Left Inboard Outlet Manual Setting";
BA_ "SignalLongName" SG_ 1986 IndHrztlPsFrtRtInbrdOtltManSet "Indication HVAC Settings 1 : Indication Horizontal Position Front Right Inboard Outlet Manual Setting";
BA_ "SignalLongName" SG_ 1986 IndHrztlPsFrtRtOtbrdOtltManSet "Indication HVAC Settings 1 : Indication Horizontal Position Front Right Outboard Outlet Manual Setting";
BA_ "SignalLongName" SG_ 1986 IndVertPstnFrtLtInbrdOtltManSet "Indication HVAC Settings 1 : Indication Vertical Position Front Left Inboard Outlet Manual Setting";
BA_ "SignalLongName" SG_ 1986 IndVertPstnFrtLtOtbrdOtltManSet "Indication HVAC Settings 1 : Indication Vertical Position Front Left Outboard Outlet Manual Setting";
BA_ "SignalLongName" SG_ 1986 IndVertPstnFrtRtInbrdOtltManSet "Indication HVAC Settings 1 : Indication Vertical Position Front Right Inboard Outlet Manual Setting";
BA_ "SignalLongName" SG_ 1986 IndVertPstnFrtRtOtbrdOtltManSet "Indication HVAC Settings 1 : Indication Vertical Position Front Right Outboard Outlet Manual Setting";
BA_ "SignalLongName" SG_ 1931 OtltsOffPwrMdTmrRespVal "Outlets Off Power Mode Timer Response Information : Outlets Off Power Mode Timer Response Value";
BA_ "SignalLongName" SG_ 1931 OtltsOffPwrMdTmrRmnVal "Outlets Off Power Mode Timer Remaining Information : Outlets Off Power Mode Timer Remaining Value";
BA_ "SignalType" SG_ 1931 OtltsOffPwrMdTmrRespVal_DuD "ENM";
BA_ "SignalLongName" SG_ 1931 OtltsOffPwrMdTmrRespVal_DuD "Outlets Off Power Mode Timer Response Information : Outlets Off Power Mode Timer Response Value Don't Use Data";
BA_ "SignalType" SG_ 1931 OtltsOffPwrMdTmrRmnVal_DuD "ENM";
BA_ "SignalLongName" SG_ 1931 OtltsOffPwrMdTmrRmnVal_DuD "Outlets Off Power Mode Timer Remaining Information : Outlets Off Power Mode Timer Remaining Value Don't Use Data";
BA_ "SignalLongName" SG_ 1931 RngLostThisDischrg "Range Lost This Discharge";
BA_ "SignalLongName" SG_ 1931 OffbrdOtltsEleclEngyPwrMax "Offboard Outlets Electrical Energy Power Maximum";
BA_ "SignalLongName" SG_ 1931 OnbrdOtltsEleclEngyPwrMax "Onboard Outlets Electrical Energy Power Maximum";
BA_ "SignalLongName" SG_ 1931 OnbrdOtltsEleclEngyPwrLvlPct "Onboard Outlets Electrical Energy Power Level Percent";
BA_ "SignalType" SG_ 1931 OtltsOffPwrMdTmrOpCstSetAval "ENM";
BA_ "SignalLongName" SG_ 1931 OtltsOffPwrMdTmrOpCstSetAval "Outlets Off Power Mode Timer Operation Customization Setting Available";
BA_ "SignalType" SG_ 1931 OffbrdEngyXferMinSOCAval "ENM";
BA_ "SignalLongName" SG_ 1931 OffbrdEngyXferMinSOCAval "Offboard Energy Transfer Minimum State of Charge Available";
BA_ "SignalType" SG_ 1135 OtltsOffPwrMdSysSts "ENM";
BA_ "SignalLongName" SG_ 1135 OtltsOffPwrMdSysSts "Outlets Off Power Mode System Status Information : Outlets Off Power Mode System Status";
BA_ "SignalType" SG_ 1135 OffbrdOtltOprtlSts "ENM";
BA_ "SignalLongName" SG_ 1135 OffbrdOtltOprtlSts "Offboard Outlet Operational Status";
BA_ "SignalType" SG_ 1135 OnbrdOtltsWrnIndReq "ENM";
BA_ "SignalLongName" SG_ 1135 OnbrdOtltsWrnIndReq "Onboard Outlets Warning Indication Request";
BA_ "SignalType" SG_ 1135 ChrgPortDrCurrStat "ENM";
BA_ "SignalLongName" SG_ 1135 ChrgPortDrCurrStat "Charge Port Door Current State";
BA_ "SignalType" SG_ 1135 ChrgPortDrClsrUserCtlAllwd "ENM";
BA_ "SignalLongName" SG_ 1135 ChrgPortDrClsrUserCtlAllwd "Charge Port Door Closure User Control Allowed";
BA_ "SignalType" SG_ 1135 ChrgPortDrClsrVirtCtlAval "ENM";
BA_ "SignalLongName" SG_ 1135 ChrgPortDrClsrVirtCtlAval "Charge Port Door Closure Virtual Control Available";
BA_ "SignalType" SG_ 1135 OtltsOffPwrMdSysSts_Inv "ENM";
BA_ "SignalLongName" SG_ 1135 OtltsOffPwrMdSysSts_Inv "Outlets Off Power Mode System Status Information : Outlets Off Power Mode System Status Invalid";
BA_ "SignalType" SG_ 1056 CntnsCrnkgDsbldIndOn "ENM";
BA_ "SignalLongName" SG_ 1056 CntnsCrnkgDsbldIndOn "Continuous Cranking Disabled Indication On";
BA_ "SignalType" SG_ 963 NodeStsADIMb_CAN_9_LcFA "ENM";
BA_ "SignalLongName" SG_ 963 NodeStsADIMb_CAN_9_LcFA "Node Status ADIMb_CAN_9 Loss of Communication Fault Active";
BA_ "SignalType" SG_ 963 NodeStsADIMb_CAN_3_LcFA "ENM";
BA_ "SignalLongName" SG_ 963 NodeStsADIMb_CAN_3_LcFA "Node Status ADIMb_CAN_3 Loss of Communication Fault Active";
BA_ "SignalType" SG_ 963 NodeStsADIMb_CAN_2_LcFA "ENM";
BA_ "SignalLongName" SG_ 963 NodeStsADIMb_CAN_2_LcFA "Node Status ADIMb_CAN_2 Loss of Communication Fault Active";
BA_ "SignalType" SG_ 963 NodeStsADIMb_CAN_10_LcFA "ENM";
BA_ "SignalLongName" SG_ 963 NodeStsADIMb_CAN_10_LcFA "Node Status ADIMb_CAN_10 Loss of Communication Fault Active";
BA_ "SignalType" SG_ 963 NodeStsADIMa_CAN_9_LcFA "ENM";
BA_ "SignalLongName" SG_ 963 NodeStsADIMa_CAN_9_LcFA "Node Status ADIMa_CAN_9 Loss of Communication Fault Active";
BA_ "SignalType" SG_ 963 NodeStsADIMa_CAN_3_LcFA "ENM";
BA_ "SignalLongName" SG_ 963 NodeStsADIMa_CAN_3_LcFA "Node Status ADIMa CAN 3 Loss of Communication Fault Active";
BA_ "SignalType" SG_ 963 NodeStsADIMa_CAN_2_LcFA "ENM";
BA_ "SignalLongName" SG_ 963 NodeStsADIMa_CAN_2_LcFA "Node Status ADIMa_CAN_2 Loss of Communication Fault Active";
BA_ "SignalType" SG_ 963 NodeStsADIMa_CAN_10_LcFA "ENM";
BA_ "SignalLongName" SG_ 963 NodeStsADIMa_CAN_10_LcFA "Node Status ADIMa_CAN_10 Loss of Communication Fault Active";
BA_ "SignalType" SG_ 963 NodeStsAPA_CAN_1_LcFA "ENM";
BA_ "SignalLongName" SG_ 963 NodeStsAPA_CAN_1_LcFA "Node Status APA_CAN_1 Loss of Communication Fault Active";
BA_ "SignalType" SG_ 963 NodeStsAOS_LcFA "ENM";
BA_ "SignalLongName" SG_ 963 NodeStsAOS_LcFA "Node Status AOS Loss of Communication Fault Active";
BA_ "SignalType" SG_ 963 NodeStsAMP_LcFA "ENM";
BA_ "SignalLongName" SG_ 963 NodeStsAMP_LcFA "Node Status AMP Loss of Communication Fault Active";
BA_ "SignalType" SG_ 963 NodeStsALC_LcFA "ENM";
BA_ "SignalLongName" SG_ 963 NodeStsALC_LcFA "Node Status ALC Loss of Communication Fault Active";
BA_ "SignalType" SG_ 963 NodeStsAHS_LcFA "ENM";
BA_ "SignalLongName" SG_ 963 NodeStsAHS_LcFA "Node Status AHS Loss of Communication Fault Active";
BA_ "SignalType" SG_ 963 NodeStsAHL_AFL_CAN_2_LcFA "ENM";
BA_ "SignalLongName" SG_ 963 NodeStsAHL_AFL_CAN_2_LcFA "Node Status AHL_AFL CAN 2 Loss of Communication Fault Active";
BA_ "SignalType" SG_ 963 NodeStsBSM_MH_LcFA "ENM";
BA_ "SignalLongName" SG_ 963 NodeStsBSM_MH_LcFA "Node Status BSM_MH Loss of Communication Fault Active";
BA_ "SignalType" SG_ 963 NodeStsBSM_CAN_3_LcFA "ENM";
BA_ "SignalLongName" SG_ 963 NodeStsBSM_CAN_3_LcFA "Node Status BSM_CAN_3 Loss of Communication Fault Active";
BA_ "SignalType" SG_ 963 NodeStsBSM_CAN_2_LcFA "ENM";
BA_ "SignalLongName" SG_ 963 NodeStsBSM_CAN_2_LcFA "Node Status BSM_CAN_2 Loss of Communication Fault Active";
BA_ "SignalType" SG_ 963 NodeStsBCM_LcFA "ENM";
BA_ "SignalLongName" SG_ 963 NodeStsBCM_LcFA "Node Status BCM Loss of Communication Fault Active";
BA_ "SignalType" SG_ 963 NodeStsARS_LcFA "ENM";
BA_ "SignalLongName" SG_ 963 NodeStsARS_LcFA "Node Status ARS Loss of Communication Fault Active";
BA_ "SignalType" SG_ 963 NodeStsARB_LcFA "ENM";
BA_ "SignalLongName" SG_ 963 NodeStsARB_LcFA "Node Status ARB Loss of Communication Fault Active";
BA_ "SignalType" SG_ 963 NodeStsAPA_CAN_2_LcFA "ENM";
BA_ "SignalLongName" SG_ 963 NodeStsAPA_CAN_2_LcFA "Node Status APA_CAN_2 Loss of Communication Fault Active";
BA_ "SignalType" SG_ 963 NodeStsEBCM_AV_CAN_2_LcFA "ENM";
BA_ "SignalLongName" SG_ 963 NodeStsEBCM_AV_CAN_2_LcFA "Node Status EBCM AV CAN 2 Loss of Communication Fault Active";
BA_ "SignalType" SG_ 963 NodeStsDMS_LcFA "ENM";
BA_ "SignalLongName" SG_ 963 NodeStsDMS_LcFA "Node Status DMS Loss of Communication Fault Active";
BA_ "SignalType" SG_ 963 NodeStsDEFC_LcFA "ENM";
BA_ "SignalLongName" SG_ 963 NodeStsDEFC_LcFA "Node Status DEFC Loss of Communication Fault Active";
BA_ "SignalType" SG_ 963 NodeStsDCM_LcFA "ENM";
BA_ "SignalLongName" SG_ 963 NodeStsDCM_LcFA "Node Status DCM Loss of Communication Fault Active";
BA_ "SignalType" SG_ 963 NodeStsCSM_CAN_5_LcFA "ENM";
BA_ "SignalLongName" SG_ 963 NodeStsCSM_CAN_5_LcFA "Node Status CSM_CAN_5 Loss of Communication Fault Active";
BA_ "SignalType" SG_ 963 NodeStsECP_E_CAN_9_LcFA "ENM";
BA_ "SignalLongName" SG_ 963 NodeStsECP_E_CAN_9_LcFA "Node Status ECP_E CAN 9 Loss of Communication Fault Active";
BA_ "SignalType" SG_ 963 NodeStsECP_E_CAN_2_LcFA "ENM";
BA_ "SignalLongName" SG_ 963 NodeStsECP_E_CAN_2_LcFA "Node Status ECP_E_CAN_2 Loss of Communication Fault Active";
BA_ "SignalType" SG_ 963 NodeStsECM_CAN_3_LcFA "ENM";
BA_ "SignalLongName" SG_ 963 NodeStsECM_CAN_3_LcFA "Node Status ECM_CAN_3 Loss of Communication Fault Active";
BA_ "SignalType" SG_ 963 NodeStsECM_CAN_2_LcFA "ENM";
BA_ "SignalLongName" SG_ 963 NodeStsECM_CAN_2_LcFA "Node Status ECM_CAN_2 Loss of Communication Fault Active";
BA_ "SignalType" SG_ 963 NodeStsEBCM_CAN_3_LcFA "ENM";
BA_ "SignalLongName" SG_ 963 NodeStsEBCM_CAN_3_LcFA "Node Status EBCM CAN 3 Loss of Communication Fault Active";
BA_ "SignalType" SG_ 963 NodeStsEBCM_CAN_2_LcFA "ENM";
BA_ "SignalLongName" SG_ 963 NodeStsEBCM_CAN_2_LcFA "Node Status EBCM_CAN_2 Loss of Communication Fault Active";
BA_ "SignalType" SG_ 963 NodeStsEBCM_AV_CAN_3_LcFA "ENM";
BA_ "SignalLongName" SG_ 963 NodeStsEBCM_AV_CAN_3_LcFA "Node Status EBCM_AV CAN 3 Loss of Communication Fault Active";
BA_ "SignalType" SG_ 963 NodeStsEOCM_CAN_3_LcFA "ENM";
BA_ "SignalLongName" SG_ 963 NodeStsEOCM_CAN_3_LcFA "Node Status EOCM CAN 3 Loss of Communication Fault Active";
BA_ "SignalType" SG_ 963 NodeStsEOCM_CAN_2_LcFA "ENM";
BA_ "SignalLongName" SG_ 963 NodeStsEOCM_CAN_2_LcFA "Node Status EOCM_CAN_2 Loss of Communication Fault Active";
BA_ "SignalType" SG_ 963 NodeStsELM_LcFA "ENM";
BA_ "SignalLongName" SG_ 963 NodeStsELM_LcFA "Node Status ELM Loss of Communication Fault Active";
BA_ "SignalType" SG_ 963 NodeStsECP_X1_CAN_3_LcFA "ENM";
BA_ "SignalLongName" SG_ 963 NodeStsECP_X1_CAN_3_LcFA "Node Status ECP_X1_CAN_3 Loss of Communication Fault Active";
BA_ "SignalType" SG_ 963 NodeStsECP_X1_CAN_2_LcFA "ENM";
BA_ "SignalLongName" SG_ 963 NodeStsECP_X1_CAN_2_LcFA "Node Status ECP_X1_CAN_2 Loss of Communication Fault Active";
BA_ "SignalType" SG_ 963 NodeStsECP_S_CAN_9_LcFA "ENM";
BA_ "SignalLongName" SG_ 963 NodeStsECP_S_CAN_9_LcFA "Node Status ECP_S_CAN_9 Loss of Communication Fault Active";
BA_ "SignalType" SG_ 963 NodeStsECP_S_CAN_2_LcFA "ENM";
BA_ "SignalLongName" SG_ 963 NodeStsECP_S_CAN_2_LcFA "Node Status ECP_S CAN 2 Loss of Communication Fault Active";
BA_ "SignalType" SG_ 963 NodeStsECP_MC_LcFA "ENM";
BA_ "SignalLongName" SG_ 963 NodeStsECP_MC_LcFA "Node Status ECP_MC Loss of Communication Fault Active";
BA_ "SignalType" SG_ 963 NodeStsEPSRAa_LcFA "ENM";
BA_ "SignalLongName" SG_ 963 NodeStsEPSRAa_LcFA "Node Status EPSRAa Loss of Communication Fault Active";
BA_ "SignalType" SG_ 963 NodeStsEPS_LcFA "ENM";
BA_ "SignalLongName" SG_ 963 NodeStsEPS_LcFA "Node Status EPS Loss of Communication Fault Active";
BA_ "SignalType" SG_ 963 NodeStsEPS_1_LcFA "ENM";
BA_ "SignalLongName" SG_ 963 NodeStsEPS_1_LcFA "Node Status EPS_1 Loss of Communication Fault Active";
BA_ "SignalType" SG_ 963 NodeStsEOCM_HCP2_LcFA "ENM";
BA_ "SignalLongName" SG_ 963 NodeStsEOCM_HCP2_LcFA "Node Status EOCM_HCP2 Loss of Communication Fault Active";
BA_ "SignalType" SG_ 963 NodeStsEOCM_HCP1_CAN_8_LcFA "ENM";
BA_ "SignalLongName" SG_ 963 NodeStsEOCM_HCP1_CAN_8_LcFA "Node Status EOCM_HCP1_CAN_8 Loss of Communication Fault Active";
BA_ "SignalType" SG_ 963 NodeStsEOCM_HCP1_CAN_3_LcFA "ENM";
BA_ "SignalLongName" SG_ 963 NodeStsEOCM_HCP1_CAN_3_LcFA "Node Status EOCM_HCP1 CAN 3 Loss of Communication Fault Active";
BA_ "SignalType" SG_ 963 NodeStsEOCM_HCP1_CAN_2_LcFA "ENM";
BA_ "SignalLongName" SG_ 963 NodeStsEOCM_HCP1_CAN_2_LcFA "Node Status EOCM_HCP1_CAN_2 Loss of Communication Fault Active";
BA_ "SignalType" SG_ 963 NodeStsEOCM_CAN_8_LcFA "ENM";
BA_ "SignalLongName" SG_ 963 NodeStsEOCM_CAN_8_LcFA "Node Status EOCM_CAN_8 Loss of Communication Fault Active";
BA_ "SignalType" SG_ 963 NodeStsHVAC_FP_F_LcFA "ENM";
BA_ "SignalLongName" SG_ 963 NodeStsHVAC_FP_F_LcFA "Node Status HVAC_FP_F Loss of Communication Fault Active";
BA_ "SignalType" SG_ 963 NodeStsHUD_CAN_LcFA "ENM";
BA_ "SignalLongName" SG_ 963 NodeStsHUD_CAN_LcFA "Node Status HUD_CAN Loss of Communication Fault Active";
BA_ "SignalType" SG_ 963 NodeStsHDLM_LcFA "ENM";
BA_ "SignalLongName" SG_ 963 NodeStsHDLM_LcFA "Node Status HDLM Loss of Communication Fault Active";
BA_ "SignalType" SG_ 963 NodeStsFOPM_CAN_3_LcFA "ENM";
BA_ "SignalLongName" SG_ 963 NodeStsFOPM_CAN_3_LcFA "Node Status FOPM CAN 3 Loss of Communication Fault Active";
BA_ "SignalType" SG_ 963 NodeStsFOPM_CAN_2_LcFA "ENM";
BA_ "SignalLongName" SG_ 963 NodeStsFOPM_CAN_2_LcFA "Node Status FOPM_CAN_2 Loss of Communication Fault Active";
BA_ "SignalType" SG_ 963 NodeStsFCM_LcFA "ENM";
BA_ "SignalLongName" SG_ 963 NodeStsFCM_LcFA "Node Status FCM Loss of Communication Fault Active";
BA_ "SignalType" SG_ 963 NodeStsFCM_LC_LcFA "ENM";
BA_ "SignalLongName" SG_ 963 NodeStsFCM_LC_LcFA "Node Status FCM LC Loss of Communication Fault Active";
BA_ "SignalType" SG_ 963 NodeStsEPSRAb_LcFA "ENM";
BA_ "SignalLongName" SG_ 963 NodeStsEPSRAb_LcFA "Node Status EPSRAb Loss of Communication Fault Active";
BA_ "SignalType" SG_ 964 NodeStsMFC_LcFA "ENM";
BA_ "SignalLongName" SG_ 964 NodeStsMFC_LcFA "Node Status MFC Loss of Communication Fault Active";
BA_ "SignalType" SG_ 964 NodeStsLRR_LcFA "ENM";
BA_ "SignalLongName" SG_ 964 NodeStsLRR_LcFA "Node Status LRR Loss of Communication Fault Active";
BA_ "SignalType" SG_ 964 NodeStsLIB1_LcFA "ENM";
BA_ "SignalLongName" SG_ 964 NodeStsLIB1_LcFA "Node Status LIB1 Loss of Communication Fault Active";
BA_ "SignalType" SG_ 964 NodeStsIPC_CAN_5_LcFA "ENM";
BA_ "SignalLongName" SG_ 964 NodeStsIPC_CAN_5_LcFA "Node Status IPC CAN 5 Loss of Communication Fault Active";
BA_ "SignalType" SG_ 964 NodeStsICS_Info_LcFA "ENM";
BA_ "SignalLongName" SG_ 964 NodeStsICS_Info_LcFA "Node Status ICS_Info Loss of Communication Fault Active";
BA_ "SignalType" SG_ 964 NodeStsICCM_CAN_3_LcFA "ENM";
BA_ "SignalLongName" SG_ 964 NodeStsICCM_CAN_3_LcFA "Node Status ICCM CAN 3 Loss of Communication Fault Active";
BA_ "SignalType" SG_ 964 NodeStsHVAC_FP_R_LcFA "ENM";
BA_ "SignalLongName" SG_ 964 NodeStsHVAC_FP_R_LcFA "Node Status HVAC_FP_R Loss of Communication Fault Active";
BA_ "SignalType" SG_ 964 NodeStsMSM_RR_LcFA "ENM";
BA_ "SignalLongName" SG_ 964 NodeStsMSM_RR_LcFA "Node Status MSM_RR Loss of Communication Fault Active";
BA_ "SignalType" SG_ 964 NodeStsMSM_P_LcFA "ENM";
BA_ "SignalLongName" SG_ 964 NodeStsMSM_P_LcFA "Node Status MSM_P Loss of Communication Fault Active";
BA_ "SignalType" SG_ 964 NodeStsMSM_LR_LcFA "ENM";
BA_ "SignalLongName" SG_ 964 NodeStsMSM_LR_LcFA "Node Status MSM_LR Loss of Communication Fault Active";
BA_ "SignalType" SG_ 964 NodeStsMSM_D_LcFA "ENM";
BA_ "SignalLongName" SG_ 964 NodeStsMSM_D_LcFA "Node Status MSM_D Loss of Communication Fault Active";
BA_ "SignalType" SG_ 964 NodeStsMSB2_LcFA "ENM";
BA_ "SignalLongName" SG_ 964 NodeStsMSB2_LcFA "Node Status MSB2 Loss of Communication Fault Active";
BA_ "SignalType" SG_ 964 NodeStsMSB1_LcFA "ENM";
BA_ "SignalLongName" SG_ 964 NodeStsMSB1_LcFA "Node Status MSB1 Loss of Communication Fault Active";
BA_ "SignalType" SG_ 964 NodeStsMRCM_R_LcFA "ENM";
BA_ "SignalLongName" SG_ 964 NodeStsMRCM_R_LcFA "Node Status MRCM_R Loss of Communication Fault Active";
BA_ "SignalType" SG_ 964 NodeStsMRCM_L_LcFA "ENM";
BA_ "SignalLongName" SG_ 964 NodeStsMRCM_L_LcFA "Node Status MRCM_L Loss of Communication Fault Active";
BA_ "SignalType" SG_ 964 NodeStsRDCM_LcFA "ENM";
BA_ "SignalLongName" SG_ 964 NodeStsRDCM_LcFA "Node Status RDCM Loss of Communication Fault Active";
BA_ "SignalType" SG_ 964 NodeStsRadioLow_LcFA "ENM";
BA_ "SignalLongName" SG_ 964 NodeStsRadioLow_LcFA "Node Status RadioLow Loss of Communication Fault Active";
BA_ "SignalType" SG_ 964 NodeStsPTM_LcFA "ENM";
BA_ "SignalLongName" SG_ 964 NodeStsPTM_LcFA "Node Status PTM Loss of Communication Fault Active";
BA_ "SignalType" SG_ 964 NodeStsPDR_LcFA "ENM";
BA_ "SignalLongName" SG_ 964 NodeStsPDR_LcFA "Node Status PDR Loss of Communication Fault Active";
BA_ "SignalType" SG_ 964 NodeStsPA_LcFA "ENM";
BA_ "SignalLongName" SG_ 964 NodeStsPA_LcFA "Node Status PA Loss of Communication Fault Active";
BA_ "SignalType" SG_ 964 NodeStsNVM_LcFA "ENM";
BA_ "SignalLongName" SG_ 964 NodeStsNVM_LcFA "Node Status NVM Loss of Communication Fault Active";
BA_ "SignalType" SG_ 964 NodeStsMTCM_R_LcFA "ENM";
BA_ "SignalLongName" SG_ 964 NodeStsMTCM_R_LcFA "Node Status MTCM_R Loss of Communication Fault Active";
BA_ "SignalType" SG_ 964 NodeStsMTCM_L_LcFA "ENM";
BA_ "SignalLongName" SG_ 964 NodeStsMTCM_L_LcFA "Node Status MTCM_L Loss of Communication Fault Active";
BA_ "SignalType" SG_ 964 NodeStsSBM_CAN_3_LcFA "ENM";
BA_ "SignalLongName" SG_ 964 NodeStsSBM_CAN_3_LcFA "Node Status SBM CAN 3 Loss of Communication Fault Active";
BA_ "SignalType" SG_ 964 NodeStsSAM_RR_LcFA "ENM";
BA_ "SignalLongName" SG_ 964 NodeStsSAM_RR_LcFA "Node Status SAM RR Loss of Communication Fault Active";
BA_ "SignalType" SG_ 964 NodeStsSAM_RF_LcFA "ENM";
BA_ "SignalLongName" SG_ 964 NodeStsSAM_RF_LcFA "Node Status SAM RF Loss of Communication Fault Active";
BA_ "SignalType" SG_ 964 NodeStsSAM_LR_LcFA "ENM";
BA_ "SignalLongName" SG_ 964 NodeStsSAM_LR_LcFA "Node Status SAM LR Loss of Communication Fault Active";
BA_ "SignalType" SG_ 964 NodeStsSAM_LF_LcFA "ENM";
BA_ "SignalLongName" SG_ 964 NodeStsSAM_LF_LcFA "Node Status SAM LF Loss of Communication Fault Active";
BA_ "SignalType" SG_ 964 NodeStsSADS_LcFA "ENM";
BA_ "SignalLongName" SG_ 964 NodeStsSADS_LcFA "Node Status SADS Loss of Communication Fault Active";
BA_ "SignalType" SG_ 964 NodeStsSRR_RF_LcFA "ENM";
BA_ "SignalLongName" SG_ 964 NodeStsSRR_RF_LcFA "Node Status SRR_RF Loss of Communication Fault Active";
BA_ "SignalType" SG_ 964 NodeStsSRR_LR_CR_LcFA "ENM";
BA_ "SignalLongName" SG_ 964 NodeStsSRR_LR_CR_LcFA "Node Status SRR_LR_CR Loss of Communication Fault Active";
BA_ "SignalType" SG_ 964 NodeStsSRR_LF_LcFA "ENM";
BA_ "SignalLongName" SG_ 964 NodeStsSRR_LF_LcFA "Node Status SRR_LF Loss of Communication Fault Active";
BA_ "SignalType" SG_ 964 NodeStsSIB_LcFA "ENM";
BA_ "SignalLongName" SG_ 964 NodeStsSIB_LcFA "Node Status SIB Loss of Communication Fault Active";
BA_ "SignalType" SG_ 964 NodeStsSDM_LcFA "ENM";
BA_ "SignalLongName" SG_ 964 NodeStsSDM_LcFA "Node Status SDM Loss of Communication Fault Active";
BA_ "SignalType" SG_ 964 NodeStsSCL_LcFA "ENM";
BA_ "SignalLongName" SG_ 964 NodeStsSCL_LcFA "Node Status SCL Loss of Communication Fault Active";
BA_ "SignalType" SG_ 964 NodeStsSBZA_R_LcFA "ENM";
BA_ "SignalLongName" SG_ 964 NodeStsSBZA_R_LcFA "Node Status SBZA_R Loss of Communication Fault Active";
BA_ "SignalType" SG_ 964 NodeStsSBZA_L_LcFA "ENM";
BA_ "SignalLongName" SG_ 964 NodeStsSBZA_L_LcFA "Node Status SBZA_L Loss of Communication Fault Active";
BA_ "SignalType" SG_ 964 NodeStsTCP_CAN_5_LcFA "ENM";
BA_ "SignalLongName" SG_ 964 NodeStsTCP_CAN_5_LcFA "Node Status TCP_CAN_5 Loss of Communication Fault Active";
BA_ "SignalType" SG_ 964 NodeStsTCM_CAN_2_LcFA "ENM";
BA_ "SignalLongName" SG_ 964 NodeStsTCM_CAN_2_LcFA "Node Status TCM_CAN_2 Loss of Communication Fault Active";
BA_ "SignalType" SG_ 964 NodeStsTCCM_LcFA "ENM";
BA_ "SignalLongName" SG_ 964 NodeStsTCCM_LcFA "Node Status TCCM Loss of Communication Fault Active";
BA_ "SignalType" SG_ 964 NodeStsSRR_SRR_LcFA "ENM";
BA_ "SignalLongName" SG_ 964 NodeStsSRR_SRR_LcFA "Node Status SRR_SRR Loss of Communication Fault Active";
BA_ "SignalType" SG_ 964 NodeStsSRR_SLR_LcFA "ENM";
BA_ "SignalLongName" SG_ 964 NodeStsSRR_SLR_LcFA "Node Status SRR_SLR Loss of Communication Fault Active";
BA_ "SignalType" SG_ 964 NodeStsSRR_RR_LcFA "ENM";
BA_ "SignalLongName" SG_ 964 NodeStsSRR_RR_LcFA "Node Status SRR_RR Loss of Communication Fault Active";
BA_ "SignalType" SG_ 964 NodeStsWCM_LcFA "ENM";
BA_ "SignalLongName" SG_ 964 NodeStsWCM_LcFA "Node Status WCM Loss of Communication Fault Active";
BA_ "SignalType" SG_ 964 NodeStsVPM_LcFA "ENM";
BA_ "SignalLongName" SG_ 964 NodeStsVPM_LcFA "Node Status VPM Loss of Communication Fault Active";
BA_ "SignalType" SG_ 964 NodeStsVLM_LcFA "ENM";
BA_ "SignalLongName" SG_ 964 NodeStsVLM_LcFA "Node Status VLM Loss of Communication Fault Active";
BA_ "SignalType" SG_ 964 NodeStsVKM_LcFA "ENM";
BA_ "SignalLongName" SG_ 964 NodeStsVKM_LcFA "Node StatusVKM Loss of Communication Fault Active";
BA_ "SignalType" SG_ 964 NodeStsVICM_CAN_9_LcFA "ENM";
BA_ "SignalLongName" SG_ 964 NodeStsVICM_CAN_9_LcFA "Node Status VICM_CAN_9 Loss of Communication Fault Active";
BA_ "SignalType" SG_ 964 NodeStsVICM_CAN_2_LcFA "ENM";
BA_ "SignalLongName" SG_ 964 NodeStsVICM_CAN_2_LcFA "Node Status VICM_CAN_2 Loss of Communication Fault Active";
BA_ "SignalType" SG_ 964 NodeStsVCU_CAN_5_LcFA "ENM";
BA_ "SignalLongName" SG_ 964 NodeStsVCU_CAN_5_LcFA "Node Status VCU_CAN_5 Loss of Communication Fault Active";
BA_ "SignalType" SG_ 964 NodeStsTIM_LcFA "ENM";
BA_ "SignalLongName" SG_ 964 NodeStsTIM_LcFA "Node Status TIM Loss of Communication Fault Active";
BA_ "SignalType" SG_ 964 NodeStsECP_S2_CAN_2_LcFA "ENM";
BA_ "SignalLongName" SG_ 964 NodeStsECP_S2_CAN_2_LcFA "Node Status ECP_S2_CAN_2 Loss of Communication Fault Active";
BA_ "SignalType" SG_ 964 NodeStsPFCM_LcFA "ENM";
BA_ "SignalLongName" SG_ 964 NodeStsPFCM_LcFA "Node Status PFCM Loss of Communication Fault Active";
BA_ "SignalType" SG_ 964 NodeStsVDM_CAN_2_LcFA "ENM";
BA_ "SignalLongName" SG_ 964 NodeStsVDM_CAN_2_LcFA "Node Status VDM_CAN_2 Loss of Communication Fault Active";
BA_ "SignalType" SG_ 964 NodeStsPCM_CAN_3_LcFA "ENM";
BA_ "SignalLongName" SG_ 964 NodeStsPCM_CAN_3_LcFA "Node Status PCM_CAN_3 Loss of Communication Fault Active";
BA_ "SignalType" SG_ 964 NodeStsPCM_CAN_2_LcFA "ENM";
BA_ "SignalLongName" SG_ 964 NodeStsPCM_CAN_2_LcFA "Node Status PCM_CAN_2 Loss of Communication Fault Active";
BA_ "SignalType" SG_ 964 NodeStsSDM_AV_LcFA "ENM";
BA_ "SignalLongName" SG_ 964 NodeStsSDM_AV_LcFA "Node Status SDM_AV Loss of Communication Fault Active";
BA_ "SignalType" SG_ 962 NodeStsACP4_MCU_CAN_2_LcFA "ENM";
BA_ "SignalLongName" SG_ 962 NodeStsACP4_MCU_CAN_2_LcFA "Node Status ACP4_MCU_CAN_2 Loss of Communication Fault Active";
BA_ "SignalType" SG_ 962 NodeStsACP2_MCU_CAN_8_LcFA "ENM";
BA_ "SignalLongName" SG_ 962 NodeStsACP2_MCU_CAN_8_LcFA "Node Status ACP2_MCU CAN_8 Loss of Communication Fault Active";
BA_ "SignalType" SG_ 962 NodeStsACP2_MCU_CAN_2_LcFA "ENM";
BA_ "SignalLongName" SG_ 962 NodeStsACP2_MCU_CAN_2_LcFA "Node Status ACP2_MCU CAN_2 Loss of Communication Fault Active";
BA_ "SignalType" SG_ 962 NodeStsVECM_CAN_2_LcFA "ENM";
BA_ "SignalLongName" SG_ 962 NodeStsVECM_CAN_2_LcFA "Node Status VECM_CAN_2 Loss of Communication Fault Active";
BA_ "SignalType" SG_ 962 NodeStsVDM_CAN_9_LcFA "ENM";
BA_ "SignalLongName" SG_ 962 NodeStsVDM_CAN_9_LcFA "Node Status VDM_CAN_9 Loss of Communication Fault Active";
BA_ "SignalType" SG_ 962 NodeStsUVM_CAN_1_LcFA "ENM";
BA_ "SignalLongName" SG_ 962 NodeStsUVM_CAN_1_LcFA "Node Status UVM_CAN_1 Loss of Communication Fault Active";
BA_ "SignalType" SG_ 962 NodeStsUPM_LcFA "ENM";
BA_ "SignalLongName" SG_ 962 NodeStsUPM_LcFA "Node Status UPM Loss of Communication Fault Active";
BA_ "SignalType" SG_ 962 NodeStsEPSb_LcFA "ENM";
BA_ "SignalLongName" SG_ 962 NodeStsEPSb_LcFA "Node Status EPSb Loss of Communication Fault Active";
BA_ "SignalType" SG_ 962 NodeStsSBM_CAN_10_LcFA "ENM";
BA_ "SignalLongName" SG_ 962 NodeStsSBM_CAN_10_LcFA "Node Status SBM_CAN_10 Loss of Communication Fault Active";
BA_ "SignalType" SG_ 962 NodeStsVECM_CAN_9_LcFA "ENM";
BA_ "SignalLongName" SG_ 962 NodeStsVECM_CAN_9_LcFA "Node Status VECM_CAN_9 Loss of Communication Fault Active";
BA_ "SignalType" SG_ 962 NodeStsECP_S2_CAN_9_LcFA "ENM";
BA_ "SignalLongName" SG_ 962 NodeStsECP_S2_CAN_9_LcFA "Node Status ECP_S2_CAN_9 Loss of Communication Fault Active";
BA_ "SignalType" SG_ 962 NodeStsCSM_AV_CAN_5_LcFA "ENM";
BA_ "SignalLongName" SG_ 962 NodeStsCSM_AV_CAN_5_LcFA "Node Status CSM_AV_CAN_5 Loss of Communication Fault Active";
BA_ "SignalType" SG_ 962 NodeStsACP3_MCU_CAN_3_LcFA "ENM";
BA_ "SignalLongName" SG_ 962 NodeStsACP3_MCU_CAN_3_LcFA "Node Status ACP3_MCU CAN_3 Loss of Communication Fault Active";
BA_ "SignalType" SG_ 962 NodeStsACP3_MCU_CAN_8_LcFA "ENM";
BA_ "SignalLongName" SG_ 962 NodeStsACP3_MCU_CAN_8_LcFA "Node Status ACP3_MCU CAN_8 Loss of Communication Fault Active";
BA_ "SignalType" SG_ 962 NodeStsACP3_MCU_CAN_2_LcFA "ENM";
BA_ "SignalLongName" SG_ 962 NodeStsACP3_MCU_CAN_2_LcFA "Node Status ACP3_MCU CAN_2 Loss of Communication Fault Active";
BA_ "SignalType" SG_ 962 NodeStsWCM4_LcFA "ENM";
BA_ "SignalLongName" SG_ 962 NodeStsWCM4_LcFA "Node Status WCM4 Loss of Communication Fault Active";
BA_ "SignalType" SG_ 962 NodeStsWCM3_LcFA "ENM";
BA_ "SignalLongName" SG_ 962 NodeStsWCM3_LcFA "Node Status WCM3 Loss of Communication Fault Active";
BA_ "SignalType" SG_ 962 NodeStsWCM2_LcFA "ENM";
BA_ "SignalLongName" SG_ 962 NodeStsWCM2_LcFA "Node Status WCM2 Loss of Communication Fault Active";
BA_ "SignalType" SG_ 962 NodeStsRSI_CAN_5_LcFA "ENM";
BA_ "SignalLongName" SG_ 962 NodeStsRSI_CAN_5_LcFA "Node Status RSI Loss of Communication Fault Active";
BA_ "SignalType" SG_ 962 NodeStsLIB_48V_LcFA "ENM";
BA_ "SignalLongName" SG_ 962 NodeStsLIB_48V_LcFA "Node Status LIB_48V Loss of Communication Fault Active";
BA_ "SignalType" SG_ 962 NodeStsFPI_CAN_5_LcFA "ENM";
BA_ "SignalLongName" SG_ 962 NodeStsFPI_CAN_5_LcFA "Node Status FPI Loss of Communication Fault Active";
BA_ "SignalType" SG_ 962 NodeStsACP4_MCU_CAN_3_LcFA "ENM";
BA_ "SignalLongName" SG_ 962 NodeStsACP4_MCU_CAN_3_LcFA "Node Status ACP4_MCU_CAN_3 Loss of Communication Fault Active";
BA_ "SignalType" SG_ 962 NodeStsACP4_MCU_CAN_8_LcFA "ENM";
BA_ "SignalLongName" SG_ 962 NodeStsACP4_MCU_CAN_8_LcFA "Node Status ACP4 MCU_CAN_8 Loss of Communication Fault Active";
BA_ "SignalType" SG_ 962 NodeStsBSM_HEV_CAN_2_LcFA "ENM";
BA_ "SignalLongName" SG_ 962 NodeStsBSM_HEV_CAN_2_LcFA "Node Status BSM_HEV_CAN_2 Loss of Communication Fault Active";
BA_ "SignalType" SG_ 962 NodeStsECP_H3_CAN_2_LcFA "ENM";
BA_ "SignalLongName" SG_ 962 NodeStsECP_H3_CAN_2_LcFA "Node Status ECP_H3_CAN_2 Loss of Communication Fault Active";
BA_ "SignalType" SG_ 962 NodeStsECP_H2_CAN_2_LcFA "ENM";
BA_ "SignalLongName" SG_ 962 NodeStsECP_H2_CAN_2_LcFA "Node Status ECP_H2_CAN_2 Loss of Communication Fault Active";
BA_ "SignalType" SG_ 962 NodeStsECP_H2_CAN_9_LcFA "ENM";
BA_ "SignalLongName" SG_ 962 NodeStsECP_H2_CAN_9_LcFA "Node Status ECP_H2_CAN_9 Loss of Communication Fault Active";
BA_ "SignalType" SG_ 962 NodeStsECP_H1_CAN_9_LcFA "ENM";
BA_ "SignalLongName" SG_ 962 NodeStsECP_H1_CAN_9_LcFA "Node Status ECP_H1_CAN_9 Loss of Communication Fault Active";
BA_ "SignalType" SG_ 962 NodeStsECP_H1_CAN_2_LcFA "ENM";
BA_ "SignalLongName" SG_ 962 NodeStsECP_H1_CAN_2_LcFA "Node Status ECP_H1_CAN_2 Loss of Communication Fault Active";
BA_ "SignalType" SG_ 962 NodeStsBSM_HEV_CAN_9_LcFA "ENM";
BA_ "SignalLongName" SG_ 962 NodeStsBSM_HEV_CAN_9_LcFA "Node Status BSM_HEV_CAN_9 Loss of Communication Fault Active";
BA_ "SignalType" SG_ 962 NodeStsECP_H3_CAN_9_LcFA "ENM";
BA_ "SignalLongName" SG_ 962 NodeStsECP_H3_CAN_9_LcFA "Node Status ECP_H3_CAN_9 Loss of Communication Fault Active";
BA_ "SignalType" SG_ 962 NodeStsSAM_BH_LcFA "ENM";
BA_ "SignalLongName" SG_ 962 NodeStsSAM_BH_LcFA "Node Status SAM_BH Loss of Communication Fault Active";
BA_ "SignalType" SG_ 962 NodeStsPLCM_LcFA "ENM";
BA_ "SignalLongName" SG_ 962 NodeStsPLCM_LcFA "Node Status PLCM Loss of Communication Fault Active";
BA_ "SignalType" SG_ 962 NodeStsODS_LcFA "ENM";
BA_ "SignalLongName" SG_ 962 NodeStsODS_LcFA "Node Status ODS Loss of Communication Fault Active";
BA_ "SignalType" SG_ 962 NodeStsODS2_LcFA "ENM";
BA_ "SignalLongName" SG_ 962 NodeStsODS2_LcFA "Node Status ODS2 Loss of Communication Fault Active";
BA_ "SignalType" SG_ 952 NodeStsEBCM_CAN_3_Prsnt "ENM";
BA_ "SignalLongName" SG_ 952 NodeStsEBCM_CAN_3_Prsnt "Node Status EBCM CAN_3 Present";
BA_ "SignalType" SG_ 952 NodeStsICCM_CAN_3_Prsnt "ENM";
BA_ "SignalLongName" SG_ 952 NodeStsICCM_CAN_3_Prsnt "Node Status ICCM CAN_3 Present";
BA_ "SignalType" SG_ 952 NodeStsARB_Prsnt "ENM";
BA_ "SignalLongName" SG_ 952 NodeStsARB_Prsnt "Node Status ARB Present";
BA_ "SignalType" SG_ 952 NodeStsVECM_CAN_2_Prsnt "ENM";
BA_ "SignalLongName" SG_ 952 NodeStsVECM_CAN_2_Prsnt "Node Status VECM CAN_2 Present";
BA_ "SignalType" SG_ 952 NodeStsEBCM_AV_CAN_3_Prsnt "ENM";
BA_ "SignalLongName" SG_ 952 NodeStsEBCM_AV_CAN_3_Prsnt "Node Status EBCM_AV CAN_3 Present";
BA_ "SignalType" SG_ 952 NodeStsSRR_SRR_Prsnt "ENM";
BA_ "SignalLongName" SG_ 952 NodeStsSRR_SRR_Prsnt "Node Status SRR_SRR Present";
BA_ "SignalType" SG_ 952 NodeStsADIMa_CAN_9_Prsnt "ENM";
BA_ "SignalLongName" SG_ 952 NodeStsADIMa_CAN_9_Prsnt "Node Status ADIMa CAN_9 Present";
BA_ "SignalType" SG_ 952 NodeStsTIM_Prsnt "ENM";
BA_ "SignalLongName" SG_ 952 NodeStsTIM_Prsnt "Node Status TIM Present";
BA_ "SignalType" SG_ 952 NodeStsSDM_AV_Prsnt "ENM";
BA_ "SignalLongName" SG_ 952 NodeStsSDM_AV_Prsnt "Node Status SDM_AV Present";
BA_ "SignalType" SG_ 952 NodeStsEOCM_HCP2_Prsnt "ENM";
BA_ "SignalLongName" SG_ 952 NodeStsEOCM_HCP2_Prsnt "Node Status EOCM_HCP2 Present";
BA_ "SignalType" SG_ 952 NodeStsLIB1_Prsnt "ENM";
BA_ "SignalLongName" SG_ 952 NodeStsLIB1_Prsnt "Node Status LIB1 Present";
BA_ "SignalType" SG_ 952 NodeStsELM_Prsnt "ENM";
BA_ "SignalLongName" SG_ 952 NodeStsELM_Prsnt "Node Status ELM Present";
BA_ "SignalType" SG_ 952 NodeStsMFC_Prsnt "ENM";
BA_ "SignalLongName" SG_ 952 NodeStsMFC_Prsnt "Node Status MFC Present";
BA_ "SignalType" SG_ 952 NodeStsEBCM_CAN_2_Prsnt "ENM";
BA_ "SignalLongName" SG_ 952 NodeStsEBCM_CAN_2_Prsnt "Node Status EBCM CAN_2 Present";
BA_ "SignalType" SG_ 952 NodeStsEOCM_HCP1_CAN_3_Prsnt "ENM";
BA_ "SignalLongName" SG_ 952 NodeStsEOCM_HCP1_CAN_3_Prsnt "Node Status EOCM_HCP1 CAN_3 Present";
BA_ "SignalType" SG_ 952 NodeStsEPSRAa_Prsnt "ENM";
BA_ "SignalLongName" SG_ 952 NodeStsEPSRAa_Prsnt "Node Status EPSRAa Present";
BA_ "SignalType" SG_ 952 NodeStsSADS_Prsnt "ENM";
BA_ "SignalLongName" SG_ 952 NodeStsSADS_Prsnt "Node Status SADS Present";
BA_ "SignalType" SG_ 952 NodeStsSAM_RF_Prsnt "ENM";
BA_ "SignalLongName" SG_ 952 NodeStsSAM_RF_Prsnt "Node Status SAM_RF Present";
BA_ "SignalType" SG_ 952 NodeStsSAM_LF_Prsnt "ENM";
BA_ "SignalLongName" SG_ 952 NodeStsSAM_LF_Prsnt "Node Status SAM_LF Present";
BA_ "SignalType" SG_ 952 NodeStsFCM_Prsnt "ENM";
BA_ "SignalLongName" SG_ 952 NodeStsFCM_Prsnt "Node Status FCM Present";
BA_ "SignalType" SG_ 952 NodeStsSAM_RR_Prsnt "ENM";
BA_ "SignalLongName" SG_ 952 NodeStsSAM_RR_Prsnt "Node Status SAM_RR Present";
BA_ "SignalType" SG_ 952 NodeStsECP_H3_CAN_2_Prsnt "ENM";
BA_ "SignalLongName" SG_ 952 NodeStsECP_H3_CAN_2_Prsnt "Node Status ECP_H3 CAN_2 Present";
BA_ "SignalType" SG_ 952 NodeStsVDM_CAN_9_Prsnt "ENM";
BA_ "SignalLongName" SG_ 952 NodeStsVDM_CAN_9_Prsnt "Node Status VDM CAN_9 Present";
BA_ "SignalType" SG_ 952 NodeStsECP_X1_CAN_2_Prsnt "ENM";
BA_ "SignalLongName" SG_ 952 NodeStsECP_X1_CAN_2_Prsnt "Node Status ECP_X1 CAN_2 Present";
BA_ "SignalType" SG_ 952 NodeStsMRCM_L_Prsnt "ENM";
BA_ "SignalLongName" SG_ 952 NodeStsMRCM_L_Prsnt "Node Status MRCM_L Present";
BA_ "SignalType" SG_ 952 NodeStsBSM_HEV_CAN_9_Prsnt "ENM";
BA_ "SignalLongName" SG_ 952 NodeStsBSM_HEV_CAN_9_Prsnt "Node Status BSM_HEV CAN_9 Present";
BA_ "SignalType" SG_ 952 NodeStsSBM_CAN_10_Prsnt "ENM";
BA_ "SignalLongName" SG_ 952 NodeStsSBM_CAN_10_Prsnt "Node Status SBM CAN_10 Present";
BA_ "SignalType" SG_ 952 NodeStsFOPM_CAN_2_Prsnt "ENM";
BA_ "SignalLongName" SG_ 952 NodeStsFOPM_CAN_2_Prsnt "Node Status FOPM CAN_2 Present";
BA_ "SignalType" SG_ 952 NodeStsHUD_CAN_Prsnt "ENM";
BA_ "SignalLongName" SG_ 952 NodeStsHUD_CAN_Prsnt "Node Status HUD_CAN Present";
BA_ "SignalType" SG_ 952 NodeStsRSI_CAN_5_Prsnt "ENM";
BA_ "SignalLongName" SG_ 952 NodeStsRSI_CAN_5_Prsnt "Node Status RSI CAN_5 Present";
BA_ "SignalType" SG_ 952 NodeStsPTM_Prsnt "ENM";
BA_ "SignalLongName" SG_ 952 NodeStsPTM_Prsnt "Node Status PTM Present";
BA_ "SignalType" SG_ 952 NodeStsBSM_HEV_CAN_2_Prsnt "ENM";
BA_ "SignalLongName" SG_ 952 NodeStsBSM_HEV_CAN_2_Prsnt "Node Status BSM_HEV CAN_2 Present";
BA_ "SignalType" SG_ 952 NodeStsECP_S2_CAN_9_Prsnt "ENM";
BA_ "SignalLongName" SG_ 952 NodeStsECP_S2_CAN_9_Prsnt "Node Status ECP_S2 CAN_9 Present";
BA_ "SignalType" SG_ 952 NodeStsSBZA_L_Prsnt "ENM";
BA_ "SignalLongName" SG_ 952 NodeStsSBZA_L_Prsnt "Node Status SBZA_L Present";
BA_ "SignalType" SG_ 952 NodeStsMTCM_R_Prsnt "ENM";
BA_ "SignalLongName" SG_ 952 NodeStsMTCM_R_Prsnt "Node Status MTCM_R Present";
BA_ "SignalType" SG_ 952 NodeStsECM_CAN_3_Prsnt "ENM";
BA_ "SignalLongName" SG_ 952 NodeStsECM_CAN_3_Prsnt "Node Status ECM CAN_3 Present";
BA_ "SignalType" SG_ 952 NodeStsEPSRAb_Prsnt "ENM";
BA_ "SignalLongName" SG_ 952 NodeStsEPSRAb_Prsnt "Node Status EPSRAb Present";
BA_ "SignalType" SG_ 952 NodeStsAMP_Prsnt "ENM";
BA_ "SignalLongName" SG_ 952 NodeStsAMP_Prsnt "Node Status AMP Present";
BA_ "SignalType" SG_ 952 NodeStsRadioLow_Prsnt "ENM";
BA_ "SignalLongName" SG_ 952 NodeStsRadioLow_Prsnt "Node Status RadioLow Present";
BA_ "SignalType" SG_ 952 NodeStsFOPM_CAN_3_Prsnt "ENM";
BA_ "SignalLongName" SG_ 952 NodeStsFOPM_CAN_3_Prsnt "Node Status FOPM CAN_3 Present";
BA_ "SignalType" SG_ 952 NodeStsLIB_48V_Prsnt "ENM";
BA_ "SignalLongName" SG_ 952 NodeStsLIB_48V_Prsnt "Node Status LIB_48V Present";
BA_ "SignalType" SG_ 952 NodeStsAPA_CAN_2_Prsnt "ENM";
BA_ "SignalLongName" SG_ 952 NodeStsAPA_CAN_2_Prsnt "Node Status APA CAN_2 Present";
BA_ "SignalType" SG_ 952 NodeStsFPI_CAN_5_Prsnt "ENM";
BA_ "SignalLongName" SG_ 952 NodeStsFPI_CAN_5_Prsnt "Node Status FPI CAN_5 Present";
BA_ "SignalType" SG_ 952 NodeStsHDLM_Prsnt "ENM";
BA_ "SignalLongName" SG_ 952 NodeStsHDLM_Prsnt "Node Status HDLM Present";
BA_ "SignalType" SG_ 952 NodeStsMSM_LR_Prsnt "ENM";
BA_ "SignalLongName" SG_ 952 NodeStsMSM_LR_Prsnt "Node Status MSM_LR Present";
BA_ "SignalType" SG_ 952 NodeStsBSM_MH_Prsnt "ENM";
BA_ "SignalLongName" SG_ 952 NodeStsBSM_MH_Prsnt "Node Status BSM_MH Present";
BA_ "SignalType" SG_ 952 NodeStsECP_H1_CAN_9_Prsnt "ENM";
BA_ "SignalLongName" SG_ 952 NodeStsECP_H1_CAN_9_Prsnt "Node Status ECP_H1 CAN_9 Present";
BA_ "SignalType" SG_ 952 NodeStsPA_Prsnt "ENM";
BA_ "SignalLongName" SG_ 952 NodeStsPA_Prsnt "Node Status PA Present";
BA_ "SignalType" SG_ 952 NodeStsSAM_LR_Prsnt "ENM";
BA_ "SignalLongName" SG_ 952 NodeStsSAM_LR_Prsnt "Node Status SAM_LR Present";
BA_ "SignalType" SG_ 952 NodeStsEBCM_AV_CAN_2_Prsnt "ENM";
BA_ "SignalLongName" SG_ 952 NodeStsEBCM_AV_CAN_2_Prsnt "Node Status EBCM_AV CAN_2 Present";
BA_ "SignalType" SG_ 952 NodeStsADIMa_CAN_3_Prsnt "ENM";
BA_ "SignalLongName" SG_ 952 NodeStsADIMa_CAN_3_Prsnt "Node Status ADIMa CAN_3 Present";
BA_ "SignalType" SG_ 952 NodeStsACP2_MCU_CAN_2_Prsnt "ENM";
BA_ "SignalLongName" SG_ 952 NodeStsACP2_MCU_CAN_2_Prsnt "Node Status ACP2_MCU CAN_2 Present";
BA_ "SignalType" SG_ 952 NodeStsWCM_Prsnt "ENM";
BA_ "SignalLongName" SG_ 952 NodeStsWCM_Prsnt "Node Status WCM Present";
BA_ "SignalType" SG_ 952 NodeStsECP_MC_Prsnt "ENM";
BA_ "SignalLongName" SG_ 952 NodeStsECP_MC_Prsnt "Node Status ECP_MC Present";
BA_ "SignalType" SG_ 952 NodeStsADIMb_CAN_10_Prsnt "ENM";
BA_ "SignalLongName" SG_ 952 NodeStsADIMb_CAN_10_Prsnt "Node Status ADIMb CAN_10 Present";
BA_ "SignalType" SG_ 952 NodeStsMSB2_Prsnt "ENM";
BA_ "SignalLongName" SG_ 952 NodeStsMSB2_Prsnt "Node Status MSB2 Present";
BA_ "SignalType" SG_ 952 NodeStsMSM_P_Prsnt "ENM";
BA_ "SignalLongName" SG_ 952 NodeStsMSM_P_Prsnt "Node Status MSM_P Present";
BA_ "SignalType" SG_ 952 NodeStsAHL_AFL_CAN_2_Prsnt "ENM";
BA_ "SignalLongName" SG_ 952 NodeStsAHL_AFL_CAN_2_Prsnt "Node Status AHL_AFL CAN_2 Present";
BA_ "SignalType" SG_ 952 NodeStsPCM_CAN_2_Prsnt "ENM";
BA_ "SignalLongName" SG_ 952 NodeStsPCM_CAN_2_Prsnt "Node Status PCM CAN_2 Present";
BA_ "SignalType" SG_ 952 NodeStsEPS_Prsnt "ENM";
BA_ "SignalLongName" SG_ 952 NodeStsEPS_Prsnt "Node Status EPS Present";
BA_ "SignalType" SG_ 952 NodeStsACP4_MCU_CAN_3_Prsnt "ENM";
BA_ "SignalLongName" SG_ 952 NodeStsACP4_MCU_CAN_3_Prsnt "Node Status ACP4_MCU CAN_3 Present";
BA_ "SignalType" SG_ 953 NodeStsPDR_Prsnt "ENM";
BA_ "SignalLongName" SG_ 953 NodeStsPDR_Prsnt "Node Status PDR Present";
BA_ "SignalType" SG_ 953 NodeStsECP_X1_CAN_3_Prsnt "ENM";
BA_ "SignalLongName" SG_ 953 NodeStsECP_X1_CAN_3_Prsnt "Node Status ECP_X1 CAN_3 Present";
BA_ "SignalType" SG_ 953 NodeStsRDCM_Prsnt "ENM";
BA_ "SignalLongName" SG_ 953 NodeStsRDCM_Prsnt "Node Status RDCM Present";
BA_ "SignalType" SG_ 953 NodeStsECP_H2_CAN_2_Prsnt "ENM";
BA_ "SignalLongName" SG_ 953 NodeStsECP_H2_CAN_2_Prsnt "Node Status ECP_H2 CAN_2 Present";
BA_ "SignalType" SG_ 953 NodeStsBCM_Prsnt "ENM";
BA_ "SignalLongName" SG_ 953 NodeStsBCM_Prsnt "Node Status BCM Present";
BA_ "SignalType" SG_ 953 NodeStsAPA_CAN_1_Prsnt "ENM";
BA_ "SignalLongName" SG_ 953 NodeStsAPA_CAN_1_Prsnt "Node Status APA CAN_1 Present";
BA_ "SignalType" SG_ 953 NodeStsMTCM_L_Prsnt "ENM";
BA_ "SignalLongName" SG_ 953 NodeStsMTCM_L_Prsnt "Node Status MTCM_L Present";
BA_ "SignalType" SG_ 953 NodeStsADIMa_CAN_10_Prsnt "ENM";
BA_ "SignalLongName" SG_ 953 NodeStsADIMa_CAN_10_Prsnt "Node Status ADIMa CAN_10 Present";
BA_ "SignalType" SG_ 953 NodeStsPCM_CAN_3_Prsnt "ENM";
BA_ "SignalLongName" SG_ 953 NodeStsPCM_CAN_3_Prsnt "Node Status PCM CAN_3 Present";
BA_ "SignalType" SG_ 953 NodeStsACP3_MCU_CAN_3_Prsnt "ENM";
BA_ "SignalLongName" SG_ 953 NodeStsACP3_MCU_CAN_3_Prsnt "Node Status ACP3_MCU CAN_3 Present";
BA_ "SignalType" SG_ 953 NodeStsWCM2_Prsnt "ENM";
BA_ "SignalLongName" SG_ 953 NodeStsWCM2_Prsnt "Node Status WCM2 Present";
BA_ "SignalType" SG_ 953 NodeStsICS_Info_Prsnt "ENM";
BA_ "SignalLongName" SG_ 953 NodeStsICS_Info_Prsnt "Node Status ICS_Info Present";
BA_ "SignalType" SG_ 953 NodeStsLRR_Prsnt "ENM";
BA_ "SignalLongName" SG_ 953 NodeStsLRR_Prsnt "Node Status LRR Present";
BA_ "SignalType" SG_ 953 NodeStsWCM4_Prsnt "ENM";
BA_ "SignalLongName" SG_ 953 NodeStsWCM4_Prsnt "Node Status WCM4 Present";
BA_ "SignalType" SG_ 953 NodeStsBSM_CAN_2_Prsnt "ENM";
BA_ "SignalLongName" SG_ 953 NodeStsBSM_CAN_2_Prsnt "Node Status BSM CAN_2 Present";
BA_ "SignalType" SG_ 953 NodeStsEOCM_CAN_2_Prsnt "ENM";
BA_ "SignalLongName" SG_ 953 NodeStsEOCM_CAN_2_Prsnt "Node Status EOCM CAN_2 Present";
BA_ "SignalType" SG_ 953 NodeStsWCM3_Prsnt "ENM";
BA_ "SignalLongName" SG_ 953 NodeStsWCM3_Prsnt "Node Status WCM3 Present";
BA_ "SignalType" SG_ 953 NodeStsVKM_Prsnt "ENM";
BA_ "SignalLongName" SG_ 953 NodeStsVKM_Prsnt "Node Status VKM Present";
BA_ "SignalType" SG_ 953 NodeStsSDM_Prsnt "ENM";
BA_ "SignalLongName" SG_ 953 NodeStsSDM_Prsnt "Node Status SDM Present";
BA_ "SignalType" SG_ 953 NodeStsSIB_Prsnt "ENM";
BA_ "SignalLongName" SG_ 953 NodeStsSIB_Prsnt "Node Status SIB Present";
BA_ "SignalType" SG_ 953 NodeStsHVAC_FP_F_Prsnt "ENM";
BA_ "SignalLongName" SG_ 953 NodeStsHVAC_FP_F_Prsnt "Node Status HVAC_FP_F Present";
BA_ "SignalType" SG_ 953 NodeStsDEFC_Prsnt "ENM";
BA_ "SignalLongName" SG_ 953 NodeStsDEFC_Prsnt "Node Status DEFC Present";
BA_ "SignalType" SG_ 953 NodeStsVICM_CAN_2_Prsnt "ENM";
BA_ "SignalLongName" SG_ 953 NodeStsVICM_CAN_2_Prsnt "Node Status VICM CAN_2 Present";
BA_ "SignalType" SG_ 953 NodeStsSCL_Prsnt "ENM";
BA_ "SignalLongName" SG_ 953 NodeStsSCL_Prsnt "Node Status SCL Present";
BA_ "SignalType" SG_ 953 NodeStsACP2_MCU_CAN_8_Prsnt "ENM";
BA_ "SignalLongName" SG_ 953 NodeStsACP2_MCU_CAN_8_Prsnt "Node Status ACP2_MCU CAN_8 Present";
BA_ "SignalType" SG_ 953 NodeStsEPS_1_Prsnt "ENM";
BA_ "SignalLongName" SG_ 953 NodeStsEPS_1_Prsnt "Node Status EPS_1 Present";
BA_ "SignalType" SG_ 953 NodeStsFCM_LC_Prsnt "ENM";
BA_ "SignalLongName" SG_ 953 NodeStsFCM_LC_Prsnt "Node Status FCM_LC Present";
BA_ "SignalType" SG_ 953 NodeStsIPC_CAN_5_Prsnt "ENM";
BA_ "SignalLongName" SG_ 953 NodeStsIPC_CAN_5_Prsnt "Node Status IPC CAN_5 Present";
BA_ "SignalType" SG_ 953 NodeStsEOCM_HCP1_CAN_2_Prsnt "ENM";
BA_ "SignalLongName" SG_ 953 NodeStsEOCM_HCP1_CAN_2_Prsnt "Node Status EOCM_HCP1 CAN_2 Present";
BA_ "SignalType" SG_ 953 NodeStsTCCM_Prsnt "ENM";
BA_ "SignalLongName" SG_ 953 NodeStsTCCM_Prsnt "Node Status TCCM Present";
BA_ "SignalType" SG_ 953 NodeStsSBM_CAN_3_Prsnt "ENM";
BA_ "SignalLongName" SG_ 953 NodeStsSBM_CAN_3_Prsnt "Node Status SBM CAN_3 Present";
BA_ "SignalType" SG_ 953 NodeStsARS_Prsnt "ENM";
BA_ "SignalLongName" SG_ 953 NodeStsARS_Prsnt "Node Status ARS Present";
BA_ "SignalType" SG_ 953 NodeStsEPSb_Prsnt "ENM";
BA_ "SignalLongName" SG_ 953 NodeStsEPSb_Prsnt "Node Status EPSb Present";
BA_ "SignalType" SG_ 953 NodeStsBSM_CAN_3_Prsnt "ENM";
BA_ "SignalLongName" SG_ 953 NodeStsBSM_CAN_3_Prsnt "Node Status BSM CAN_3 Present";
BA_ "SignalType" SG_ 953 NodeStsVCU_CAN_5_Prsnt "ENM";
BA_ "SignalLongName" SG_ 953 NodeStsVCU_CAN_5_Prsnt "Node Status VCU CAN_5 Present";
BA_ "SignalType" SG_ 953 NodeStsAHS_Prsnt "ENM";
BA_ "SignalLongName" SG_ 953 NodeStsAHS_Prsnt "Node Status AHS Present";
BA_ "SignalType" SG_ 953 NodeStsCSM_CAN_5_Prsnt "ENM";
BA_ "SignalLongName" SG_ 953 NodeStsCSM_CAN_5_Prsnt "Node Status CSM CAN_5 Present";
BA_ "SignalType" SG_ 953 NodeStsVICM_CAN_9_Prsnt "ENM";
BA_ "SignalLongName" SG_ 953 NodeStsVICM_CAN_9_Prsnt "Node Status VICM CAN_9 Present";
BA_ "SignalType" SG_ 953 NodeStsSRR_LF_Prsnt "ENM";
BA_ "SignalLongName" SG_ 953 NodeStsSRR_LF_Prsnt "Node Status SRR_LF Present";
BA_ "SignalType" SG_ 953 NodeStsTCM_CAN_2_Prsnt "ENM";
BA_ "SignalLongName" SG_ 953 NodeStsTCM_CAN_2_Prsnt "Node Status TCM CAN_2 Present";
BA_ "SignalType" SG_ 953 NodeStsVPM_Prsnt "ENM";
BA_ "SignalLongName" SG_ 953 NodeStsVPM_Prsnt "Node Status VPM Present";
BA_ "SignalType" SG_ 953 NodeStsSRR_RF_Prsnt "ENM";
BA_ "SignalLongName" SG_ 953 NodeStsSRR_RF_Prsnt "Node Status SRR_RF Present";
BA_ "SignalType" SG_ 953 NodeStsACP3_MCU_CAN_8_Prsnt "ENM";
BA_ "SignalLongName" SG_ 953 NodeStsACP3_MCU_CAN_8_Prsnt "Node Status ACP3_MCU CAN_8 Present";
BA_ "SignalType" SG_ 953 NodeStsECP_E_CAN_2_Prsnt "ENM";
BA_ "SignalLongName" SG_ 953 NodeStsECP_E_CAN_2_Prsnt "Node Status ECP_E CAN_2 Present";
BA_ "SignalType" SG_ 953 NodeStsSBZA_R_Prsnt "ENM";
BA_ "SignalLongName" SG_ 953 NodeStsSBZA_R_Prsnt "Node Status SBZA_R Present";
BA_ "SignalType" SG_ 953 NodeStsVLM_Prsnt "ENM";
BA_ "SignalLongName" SG_ 953 NodeStsVLM_Prsnt "Node Status VLM Present";
BA_ "SignalType" SG_ 953 NodeStsADIMb_CAN_9_Prsnt "ENM";
BA_ "SignalLongName" SG_ 953 NodeStsADIMb_CAN_9_Prsnt "Node Status ADIMb CAN_9 Present";
BA_ "SignalType" SG_ 953 NodeStsUVM_CAN_1_Prsnt "ENM";
BA_ "SignalLongName" SG_ 953 NodeStsUVM_CAN_1_Prsnt "Node Status UVM CAN_1 Present";
BA_ "SignalType" SG_ 953 NodeStsALC_Prsnt "ENM";
BA_ "SignalLongName" SG_ 953 NodeStsALC_Prsnt "Node Status ALC Present";
BA_ "SignalType" SG_ 953 NodeStsSRR_LR_CR_Prsnt "ENM";
BA_ "SignalLongName" SG_ 953 NodeStsSRR_LR_CR_Prsnt "Node Status SRR_LR_CR Present";
BA_ "SignalType" SG_ 953 NodeStsDCM_Prsnt "ENM";
BA_ "SignalLongName" SG_ 953 NodeStsDCM_Prsnt "Node Status DCM Present";
BA_ "SignalType" SG_ 953 NodeStsNVM_Prsnt "ENM";
BA_ "SignalLongName" SG_ 953 NodeStsNVM_Prsnt "Node Status NVM Present";
BA_ "SignalType" SG_ 953 NodeStsDMS_Prsnt "ENM";
BA_ "SignalLongName" SG_ 953 NodeStsDMS_Prsnt "Node Status DMS Present";
BA_ "SignalType" SG_ 953 NodeStsTCP_CAN_5_Prsnt "ENM";
BA_ "SignalLongName" SG_ 953 NodeStsTCP_CAN_5_Prsnt "Node Status TCP CAN_5 Present";
BA_ "SignalType" SG_ 953 NodeStsECM_CAN_2_Prsnt "ENM";
BA_ "SignalLongName" SG_ 953 NodeStsECM_CAN_2_Prsnt "Node Status ECM CAN_2 Present";
BA_ "SignalType" SG_ 953 NodeStsADIMb_CAN_2_Prsnt "ENM";
BA_ "SignalLongName" SG_ 953 NodeStsADIMb_CAN_2_Prsnt "Node Status ADIMb CAN_2 Present";
BA_ "SignalType" SG_ 953 NodeStsSRR_RR_Prsnt "ENM";
BA_ "SignalLongName" SG_ 953 NodeStsSRR_RR_Prsnt "Node Status SRR_RR Present";
BA_ "SignalType" SG_ 953 NodeStsADIMa_CAN_2_Prsnt "ENM";
BA_ "SignalLongName" SG_ 953 NodeStsADIMa_CAN_2_Prsnt "Node Status ADIMa CAN_2 Present";
BA_ "SignalType" SG_ 953 NodeStsHVAC_FP_R_Prsnt "ENM";
BA_ "SignalLongName" SG_ 953 NodeStsHVAC_FP_R_Prsnt "Node Status HVAC_FP_R Present";
BA_ "SignalType" SG_ 953 NodeStsSRR_SLR_Prsnt "ENM";
BA_ "SignalLongName" SG_ 953 NodeStsSRR_SLR_Prsnt "Node Status SRR_SLR Present";
BA_ "SignalType" SG_ 953 NodeStsEOCM_HCP1_CAN_8_Prsnt "ENM";
BA_ "SignalLongName" SG_ 953 NodeStsEOCM_HCP1_CAN_8_Prsnt "Node Status EOCM_HCP1 CAN_8 Present";
BA_ "SignalType" SG_ 953 NodeStsECP_S2_CAN_2_Prsnt "ENM";
BA_ "SignalLongName" SG_ 953 NodeStsECP_S2_CAN_2_Prsnt "Node Status ECP_S2 CAN_2 Present";
BA_ "SignalType" SG_ 953 NodeStsECP_S_CAN_9_Prsnt "ENM";
BA_ "SignalLongName" SG_ 953 NodeStsECP_S_CAN_9_Prsnt "Node Status ECP_S CAN_9 Present";
BA_ "SignalType" SG_ 954 NodeStsUPM_Prsnt "ENM";
BA_ "SignalLongName" SG_ 954 NodeStsUPM_Prsnt "Node Status UPM Present";
BA_ "SignalType" SG_ 954 NodeStsMSM_RR_Prsnt "ENM";
BA_ "SignalLongName" SG_ 954 NodeStsMSM_RR_Prsnt "Node Status MSM_RR Present";
BA_ "SignalType" SG_ 954 NodeStsEOCM_CAN_8_Prsnt "ENM";
BA_ "SignalLongName" SG_ 954 NodeStsEOCM_CAN_8_Prsnt "Node Status EOCM CAN_8 Present";
BA_ "SignalType" SG_ 954 NodeStsMSB1_Prsnt "ENM";
BA_ "SignalLongName" SG_ 954 NodeStsMSB1_Prsnt "Node Status MSB1 Present";
BA_ "SignalType" SG_ 954 NodeStsECP_H3_CAN_9_Prsnt "ENM";
BA_ "SignalLongName" SG_ 954 NodeStsECP_H3_CAN_9_Prsnt "Node Status ECP_H3 CAN_9 Present";
BA_ "SignalType" SG_ 954 NodeStsECP_S_CAN_2_Prsnt "ENM";
BA_ "SignalLongName" SG_ 954 NodeStsECP_S_CAN_2_Prsnt "Node Status ECP_S CAN_2 Present";
BA_ "SignalType" SG_ 954 NodeStsECP_E_CAN_9_Prsnt "ENM";
BA_ "SignalLongName" SG_ 954 NodeStsECP_E_CAN_9_Prsnt "Node Status ECP_E CAN_9 Present";
BA_ "SignalType" SG_ 954 NodeStsAOS_Prsnt "ENM";
BA_ "SignalLongName" SG_ 954 NodeStsAOS_Prsnt "Node Status AOS Present";
BA_ "SignalType" SG_ 954 NodeStsECP_H2_CAN_9_Prsnt "ENM";
BA_ "SignalLongName" SG_ 954 NodeStsECP_H2_CAN_9_Prsnt "Node Status ECP_H2 CAN_9 Present";
BA_ "SignalType" SG_ 954 NodeStsCSM_AV_CAN_5_Prsnt "ENM";
BA_ "SignalLongName" SG_ 954 NodeStsCSM_AV_CAN_5_Prsnt "Node Status CSM_AV CAN_5 Present";
BA_ "SignalType" SG_ 954 NodeStsMSM_D_Prsnt "ENM";
BA_ "SignalLongName" SG_ 954 NodeStsMSM_D_Prsnt "Node Status MSM_D Present";
BA_ "SignalType" SG_ 954 NodeStsACP3_MCU_CAN_2_Prsnt "ENM";
BA_ "SignalLongName" SG_ 954 NodeStsACP3_MCU_CAN_2_Prsnt "Node Status ACP3_MCU CAN_2 Present";
BA_ "SignalType" SG_ 954 NodeStsADIMb_CAN_3_Prsnt "ENM";
BA_ "SignalLongName" SG_ 954 NodeStsADIMb_CAN_3_Prsnt "Node Status ADIMb CAN_3 Present";
BA_ "SignalType" SG_ 954 NodeStsECP_H1_CAN_2_Prsnt "ENM";
BA_ "SignalLongName" SG_ 954 NodeStsECP_H1_CAN_2_Prsnt "Node Status ECP_H1 CAN_2 Present";
BA_ "SignalType" SG_ 954 NodeStsPFCM_Prsnt "ENM";
BA_ "SignalLongName" SG_ 954 NodeStsPFCM_Prsnt "Node Status PFCM Present";
BA_ "SignalType" SG_ 954 NodeStsVECM_CAN_9_Prsnt "ENM";
BA_ "SignalLongName" SG_ 954 NodeStsVECM_CAN_9_Prsnt "Node Status VECM CAN_9 Present";
BA_ "SignalType" SG_ 954 NodeStsSAM_BH_Prsnt "ENM";
BA_ "SignalLongName" SG_ 954 NodeStsSAM_BH_Prsnt "Node Status SAM_BH Present";
BA_ "SignalType" SG_ 954 NodeStsODS2_Prsnt "ENM";
BA_ "SignalLongName" SG_ 954 NodeStsODS2_Prsnt "Node Status ODS2 Present";
BA_ "SignalType" SG_ 954 NodeStsODS_Prsnt "ENM";
BA_ "SignalLongName" SG_ 954 NodeStsODS_Prsnt "Node Status ODS Present";
BA_ "SignalType" SG_ 954 NodeStsACP4_MCU_CAN_2_Prsnt "ENM";
BA_ "SignalLongName" SG_ 954 NodeStsACP4_MCU_CAN_2_Prsnt "Node Status ACP4_MCU CAN_2 Present";
BA_ "SignalType" SG_ 954 NodeStsVDM_CAN_2_Prsnt "ENM";
BA_ "SignalLongName" SG_ 954 NodeStsVDM_CAN_2_Prsnt "Node Status VDM CAN_2 Present";
BA_ "SignalType" SG_ 954 NodeStsEOCM_CAN_3_Prsnt "ENM";
BA_ "SignalLongName" SG_ 954 NodeStsEOCM_CAN_3_Prsnt "Node Status EOCM CAN_3 Present";
BA_ "SignalType" SG_ 954 NodeStsACP4_MCU_CAN_8_Prsnt "ENM";
BA_ "SignalLongName" SG_ 954 NodeStsACP4_MCU_CAN_8_Prsnt "Node Status ACP4_MCU CAN_8 Present";
BA_ "SignalType" SG_ 954 NodeStsMRCM_R_Prsnt "ENM";
BA_ "SignalLongName" SG_ 954 NodeStsMRCM_R_Prsnt "Node Status MRCM_R Present";
BA_ "SignalType" SG_ 954 NodeStsPLCM_Prsnt "ENM";
BA_ "SignalLongName" SG_ 954 NodeStsPLCM_Prsnt "Node Status PLCM Present";
BA_ "SignalLongName" SG_ 1382 OccptRstrntInfo_PCSM "Occupant Restraint Information Protected Counter Sync Message";
BA_ "SignalLongName" SG_ 1322 ORIP_MAC "Occupant Restraint Information Protected : MAC";
BA_ "SignalLongName" SG_ 1322 ORIP_FCnt "Occupant Restraint Information Protected : Freshness Counter";
BA_ "SignalType" SG_ 1322 FrtPsngrAirbagDsblVisIndCmd "ENM";
BA_ "SignalLongName" SG_ 1322 FrtPsngrAirbagDsblVisIndCmd "Occupant Restraint Information Protected : Front Passenger Airbag Disable Visual Indication Command";
BA_ "SignalLongName" SG_ 1322 ORIP_ARC "Occupant Restraint Information Protected : Alive Rolling Count";
BA_ "SignalType" SG_ 1322 ORIP_EnvModPrsntRsp1Auth "ENM";
BA_ "SignalLongName" SG_ 1322 ORIP_EnvModPrsntRsp1Auth "Occupant Restraint Information Protected : Environment Module Present - Responder #1 Authenticated";
BA_ "SignalType" SG_ 1322 ORIP_DrvrStBltStsAuth_Inv "ENM";
BA_ "SignalLongName" SG_ 1322 ORIP_DrvrStBltStsAuth_Inv "Occupant Restraint Information Protected : Driver Seat Belt Status Authenticated Invalid";
BA_ "SignalType" SG_ 1322 ORIP_DrvrStBltStsAuth "ENM";
BA_ "SignalLongName" SG_ 1322 ORIP_DrvrStBltStsAuth "Occupant Restraint Information Protected : Driver Seat Belt Status Authenticated";
BA_ "SignalLongName" SG_ 1322 ORIP_Filler "Occupant Restraint Information Protected : Filler";
BA_ "SignalType" SG_ 1322 RstrntSysFltPrsnt "ENM";
BA_ "SignalLongName" SG_ 1322 RstrntSysFltPrsnt "Occupant Restraint Information Protected : Restraint System Fault Present";
BA_ "SignalType" SG_ 1322 FrtPsngrAirbagEnblVisIndCmd "ENM";
BA_ "SignalLongName" SG_ 1322 FrtPsngrAirbagEnblVisIndCmd "Occupant Restraint Information Protected : Front Passenger Airbag Enable Visual Indication Command";
BA_ "SignalLongName" SG_ 1381 PstClsnInfo_PCSM "Post Collision Information Protected Counter Sync Message";
BA_ "SignalLongName" SG_ 1320 PCIP_MAC "Post Collision Information Protected : MAC";
BA_ "SignalLongName" SG_ 1320 PCIP_FCnt "Post Collision Information Protected : Freshness Counter";
BA_ "SignalType" SG_ 1320 PCIP_HzrdLgtsOnReqdAuth "ENM";
BA_ "SignalLongName" SG_ 1320 PCIP_HzrdLgtsOnReqdAuth "Post Collision Information Protected : Hazard Lights On Requested Authenticated";
BA_ "SignalType" SG_ 1320 PCIP_HybVehHiVltgDsblReqdAuth "ENM";
BA_ "SignalLongName" SG_ 1320 PCIP_HybVehHiVltgDsblReqdAuth "Post Collision Information Protected : High Voltage System Disable Requested Authenticated";
BA_ "SignalType" SG_ 1320 PCIP_HVCrshImpSnsSysDsbldAuth "ENM";
BA_ "SignalLongName" SG_ 1320 PCIP_HVCrshImpSnsSysDsbldAuth "Post Collision Information Protected : High Voltage Crash Impact Sensing System Disabled Authenticated";
BA_ "SignalType" SG_ 1320 PCIP_HVACBlwDsblReqdAuth "ENM";
BA_ "SignalLongName" SG_ 1320 PCIP_HVACBlwDsblReqdAuth "Post Collision Information Protected : HVAC Blower Disable Requested Authenticated";
BA_ "SignalType" SG_ 1320 PCIP_FuelCutOffReqdAuth "ENM";
BA_ "SignalLongName" SG_ 1320 PCIP_FuelCutOffReqdAuth "Post Collision Information Protected : Fuel Cut Off Requested Authenticated";
BA_ "SignalType" SG_ 1320 PCIP_DrUnlckReqdAuth "ENM";
BA_ "SignalLongName" SG_ 1320 PCIP_DrUnlckReqdAuth "Post Collision Information Protected : Door Unlock Requested Authenticated";
BA_ "SignalType" SG_ 1320 PCIP_CruzCtlDsblReqdAuth "ENM";
BA_ "SignalLongName" SG_ 1320 PCIP_CruzCtlDsblReqdAuth "Post Collision Information Protected : Cruise Control Disable Requested Authenticated";
BA_ "SignalType" SG_ 1320 PCIP_BrkActReqdAuth "ENM";
BA_ "SignalLongName" SG_ 1320 PCIP_BrkActReqdAuth "Post Collision Information Protected : Brake Actuation Requested Authenticated";
BA_ "SignalLongName" SG_ 1320 PCIP_NtfnEvntCntAuth "Post Collision Information Protected : Notification Event Counter Authenticated";
BA_ "SignalType" SG_ 1320 PCIP_NftnFrtImpPrtnsrSevAchAuth "ENM";
BA_ "SignalLongName" SG_ 1320 PCIP_NftnFrtImpPrtnsrSevAchAuth "Post Collision Information Protected : Notification Frontal Impact Pretensioner Severity Achieved Authenticated";
BA_ "SignalType" SG_ 1320 PCIP_MemStRclDsblReqdAuth "ENM";
BA_ "SignalLongName" SG_ 1320 PCIP_MemStRclDsblReqdAuth "Post Collision Information Protected : Memory Seat Recall Disable Requested Authenticated";
BA_ "SignalType" SG_ 1320 PCIP_IntrLgtOnReqdAuth "ENM";
BA_ "SignalLongName" SG_ 1320 PCIP_IntrLgtOnReqdAuth "Post Collision Information Protected : Interior Light On Requested Authenticated";
BA_ "SignalType" SG_ 1320 PCIP_NtfnLtSdSevAchvdAuth "ENM";
BA_ "SignalLongName" SG_ 1320 PCIP_NtfnLtSdSevAchvdAuth "Post Collision Information Protected : Notification Left Side Severity Achieved Authenticated";
BA_ "SignalType" SG_ 1320 PCIP_NtfnFrtImpStg2SevAchvdAuth "ENM";
BA_ "SignalLongName" SG_ 1320 PCIP_NtfnFrtImpStg2SevAchvdAuth "Post Collision Information Protected : Notification Frontal Impact Stage2 Severity Achieved Authenticated";
BA_ "SignalType" SG_ 1320 PCIP_NtfnFrtImpStg1SevAchvdAuth "ENM";
BA_ "SignalLongName" SG_ 1320 PCIP_NtfnFrtImpStg1SevAchvdAuth "Post Collision Information Protected : Notification Frontal Impact Stage1 Severity Achieved Authenticated";
BA_ "SignalType" SG_ 1320 PCIP_NtfnEvntStsAuth "ENM";
BA_ "SignalLongName" SG_ 1320 PCIP_NtfnEvntStsAuth "Post Collision Information Protected : Notification Event Status Authenticated";
BA_ "SignalLongName" SG_ 1320 PCIP_Filler "Post Collision Information Protected : Filler";
BA_ "SignalLongName" SG_ 1320 PCIP_ARC "Post Collision Information Protected : Alive Rolling Count";
BA_ "SignalType" SG_ 1320 PCIP_eCallReqdAuth "ENM";
BA_ "SignalLongName" SG_ 1320 PCIP_eCallReqdAuth "Post Collision Information Protected : eCall Requested Authenticated";
BA_ "SignalType" SG_ 1320 PCIP_NtfnRtSdSevAchvdAuth "ENM";
BA_ "SignalLongName" SG_ 1320 PCIP_NtfnRtSdSevAchvdAuth "Post Collision Information Protected : Notification Right Side Severity Achieved Authenticated";
BA_ "SignalType" SG_ 1320 PCIP_NtfnRrImpSevAchvdAuth "ENM";
BA_ "SignalLongName" SG_ 1320 PCIP_NtfnRrImpSevAchvdAuth "Post Collision Information Protected : Notification Rear Impact Severity Achieved Authenticated";
BA_ "SignalType" SG_ 1320 PCIP_NtfnRlOvrSevAchvdAuth "ENM";
BA_ "SignalLongName" SG_ 1320 PCIP_NtfnRlOvrSevAchvdAuth "Post Collision Information Protected : Notification Roll Over Severity Achieved Authenticated";
BA_ "SignalType" SG_ 1320 PCIP_NtfnPedtrnPrtctnSevAchAuth "ENM";
BA_ "SignalLongName" SG_ 1320 PCIP_NtfnPedtrnPrtctnSevAchAuth "Post Collision Information Protected : Notification Pedpro Severity Achieved Authenticated";
BA_ "SignalLongName" SG_ 1399 PwrStrgInfo_PCSM "Power Steering Information Protected Counter Sync Message";
BA_ "SignalLongName" SG_ 870 PSIP_MAC "Power Steering Information Protected : MAC";
BA_ "SignalLongName" SG_ 870 PSIP_FCnt "Power Steering Information Protected : Freshness Counter";
BA_ "SignalLongName" SG_ 870 PSIP_ARC "Power Steering Information Protected : Alive Rolling Count";
BA_ "SignalType" SG_ 870 PSIP_StrgAsstRdcdLvl3IndOnAuth "ENM";
BA_ "SignalLongName" SG_ 870 PSIP_StrgAsstRdcdLvl3IndOnAuth "Power Steering Information Protected : Steering Assist Reduced Level 3 Indication On Authenticated";
BA_ "SignalType" SG_ 870 PSIP_StrgAsstRdcdLvl2IndOnAuth "ENM";
BA_ "SignalLongName" SG_ 870 PSIP_StrgAsstRdcdLvl2IndOnAuth "Power Steering Information Protected : Steering Assist Reduced Level 2 Indication On Authenticated";
BA_ "SignalType" SG_ 870 PSIP_StrgAsstRdcdIndOnAuth "ENM";
BA_ "SignalLongName" SG_ 870 PSIP_StrgAsstRdcdIndOnAuth "Power Steering Information Protected : Steering Assist Reduced Indication On Authenticated";
BA_ "SignalType" SG_ 870 PSIP_PwrStrgIndOnAuth "ENM";
BA_ "SignalLongName" SG_ 870 PSIP_PwrStrgIndOnAuth "Power Steering Information Protected : Power Steering Indication On Authenticated";
BA_ "SignalLongName" SG_ 1363 RPPSD_BrstGrp1_PCSM "Redundant Precise Positioning System Data Burst Group Protected Counter Sync Message";
BA_ "SignalLongName" SG_ 606 RPPSDBG2P_CldrYrAuth "Redundant Precise Positioning System Data Burst Group 2 Protected : Calendar Year Authenticated";
BA_ "SignalLongName" SG_ 606 RPPSDBG2P_BrstID "Redundant Precise Positioning System Data Burst Group 2 Protected : Burst ID";
BA_ "SignalLongName" SG_ 606 RPPSDBG2P_ElvtnAuth "Redundant Precise Positioning System Data Burst Group 2 Protected : Elevation Authenticated";
BA_ "SignalType" SG_ 606 RPPSDBG2P_CldrYrAuth_Inv "ENM";
BA_ "SignalLongName" SG_ 606 RPPSDBG2P_CldrYrAuth_Inv "Redundant Precise Positioning System Data Burst Group 2 Protected : Calendar Year Authenticated Invalid";
BA_ "SignalType" SG_ 606 RPPSDBG2P_ElvtnAuth_Inv "ENM";
BA_ "SignalLongName" SG_ 606 RPPSDBG2P_ElvtnAuth_Inv "Redundant Precise Positioning System Data Burst Group 2 Protected : Elevation Authenticated Invalid";
BA_ "SignalLongName" SG_ 606 RPPSDBG2P_LngAuth "Redundant Precise Positioning System Data Burst Group 2 Protected : Longitude Authenticated";
BA_ "SignalType" SG_ 606 RPPSDBG2P_LngAuth_Inv "ENM";
BA_ "SignalLongName" SG_ 606 RPPSDBG2P_LngAuth_Inv "Redundant Precise Positioning System Data Burst Group 2 Protected : Longitude Authenticated Invalid";
BA_ "SignalLongName" SG_ 605 RPPSDBG3P_LatAuth "Redundant Precise Positioning System Data Burst Group 3 Protected : Latitude Authenticated";
BA_ "SignalLongName" SG_ 605 RPPSDBG3P_BrstID "Redundant Precise Positioning System Data Burst Group 3 Protected : Burst ID";
BA_ "SignalLongName" SG_ 605 RPPSDBG3P_TmOfDyAuth "Redundant Precise Positioning System Data Burst Group 3 Protected : Time of Day Authenticated";
BA_ "SignalType" SG_ 605 RPPSDBG3P_LocUsblAuth_Inv "ENM";
BA_ "SignalLongName" SG_ 605 RPPSDBG3P_LocUsblAuth_Inv "Redundant Precise Positioning System Data Burst Group 3 Protected : Location Usable Authenticated Invalid";
BA_ "SignalType" SG_ 605 RPPSDBG3P_LocUsblAuth "ENM";
BA_ "SignalLongName" SG_ 605 RPPSDBG3P_LocUsblAuth "Redundant Precise Positioning System Data Burst Group 3 Protected : Location Usable Authenticated";
BA_ "SignalType" SG_ 605 RPPSDBG3P_LatAuth_Inv "ENM";
BA_ "SignalLongName" SG_ 605 RPPSDBG3P_LatAuth_Inv "Redundant Precise Positioning System Data Burst Group 3 Protected : Latitude Authenticated Invalid";
BA_ "SignalType" SG_ 605 RPPSDBG3P_TmOfDyAuth_Inv "ENM";
BA_ "SignalLongName" SG_ 605 RPPSDBG3P_TmOfDyAuth_Inv "Redundant Precise Positioning System Data Burst Group 3 Protected : Time of Day Authenticated Invalid";
BA_ "SignalLongName" SG_ 604 RPPSDBG4P_2DAbsPsErrEstAuth "Redundant Precise Positioning System Data Burst Group 4 Protected : 2D Absolute Position Error Estimate Authenticated";
BA_ "SignalLongName" SG_ 604 RPPSDBG4P_BrstID "Redundant Precise Positioning System Data Burst Group 4 Protected : Burst ID";
BA_ "SignalLongName" SG_ 604 RPPSDBG4P_AbsHdgErrEstAuth "Redundant Precise Positioning System Data Burst Group 4 Protected : Absolute Heading Error Estimate Authenticated";
BA_ "SignalType" SG_ 604 RPPSDBG4P_2DAbsPsErrEstAuth_Inv "ENM";
BA_ "SignalLongName" SG_ 604 RPPSDBG4P_2DAbsPsErrEstAuth_Inv "Redundant Precise Positioning System Data Burst Group 4 Protected : 2D Absolute Position Error Estimate Authenticated Invalid";
BA_ "SignalLongName" SG_ 604 RPPSDBG4P_CldrDyAuth "Redundant Precise Positioning System Data Burst Group 4 Protected : Calendar Day Authenticated";
BA_ "SignalType" SG_ 604 RPPSDBG4P_AbsHdgErrEstAuth_Inv "ENM";
BA_ "SignalLongName" SG_ 604 RPPSDBG4P_AbsHdgErrEstAuth_Inv "Redundant Precise Positioning System Data Burst Group 4 Protected : Absolute Heading Error Estimate Authenticated Invalid";
BA_ "SignalLongName" SG_ 604 RPPSDBG4P_SigAcqTmAuth "Redundant Precise Positioning System Data Burst Group 4 Protected : Signal Acquisition Time Authenticated";
BA_ "SignalType" SG_ 604 RPPSDBG4P_CldrDyAuth_Inv "ENM";
BA_ "SignalLongName" SG_ 604 RPPSDBG4P_CldrDyAuth_Inv "Redundant Precise Positioning System Data Burst Group 4 Protected : Calendar Day Authenticated Invalid";
BA_ "SignalType" SG_ 604 RPPSDBG4P_SigAcqTmAuth_Inv "ENM";
BA_ "SignalLongName" SG_ 604 RPPSDBG4P_SigAcqTmAuth_Inv "Redundant Precise Positioning System Data Burst Group 4 Protected : Signal AcquisitionTime Authenticated Invalid";
BA_ "SignalLongName" SG_ 607 RPPSDBG1P_MAC "Redundant Precise Positioning System Data Burst Group 1 Protected : MAC";
BA_ "SignalLongName" SG_ 607 RPPSDBG1P_FCnt "Redundant Precise Positioning System Data Burst Group 1 Protected : Freshness Counter";
BA_ "SignalLongName" SG_ 607 RPPSDBG1P_HdgAuth "Redundant Precise Positioning System Data Burst Group 1 Protected : Heading Authenticated";
BA_ "SignalLongName" SG_ 607 RPPSDBG1P_BrstID "Redundant Precise Positioning System Data Burst Group 1 Protected : Burst ID";
BA_ "SignalLongName" SG_ 607 RPPSDBG1P_ARC "Redundant Precise Positioning System Data Burst Group 1 Protected : Alive Rolling Count";
BA_ "SignalType" SG_ 607 RPPSDBG1P_HdgAuth_Inv "ENM";
BA_ "SignalLongName" SG_ 607 RPPSDBG1P_HdgAuth_Inv "Redundant Precise Positioning System Data Burst Group 1 Protected : Heading Authenticated Invalid";
BA_ "SignalLongName" SG_ 603 RPPSDBG5P_LwrGblTmStmAuth "Redundant Precise Positioning System Data Burst Group 5 Protected : Lower Global Time Stamp Authenticated";
BA_ "SignalType" SG_ 603 RPPSDBG5P_GPSModeAuth_Inv "ENM";
BA_ "SignalLongName" SG_ 603 RPPSDBG5P_GPSModeAuth_Inv "Redundant Precise Positioning System Data Burst Group 5 Protected : Global Positioning System Mode Authenticated Invalid";
BA_ "SignalType" SG_ 603 RPPSDBG5P_GPSModeAuth "ENM";
BA_ "SignalLongName" SG_ 603 RPPSDBG5P_GPSModeAuth "Redundant Precise Positioning System Data Burst Group 5 Protected : Global Positioning System Mode Authenticated";
BA_ "SignalLongName" SG_ 603 RPPSDBG5P_BrstID "Redundant Precise Positioning System Data Burst Group 5 Protected : Burst ID";
BA_ "SignalType" SG_ 603 RPPSDBG5P_LwrGblTmStmAuth_Inv "ENM";
BA_ "SignalLongName" SG_ 603 RPPSDBG5P_LwrGblTmStmAuth_Inv "Redundant Precise Positioning System Data Burst Group 5 Protected : Lower Global Time Stamp Authenticated Invalid";
BA_ "SignalLongName" SG_ 1153 SrlDat123_PCSM "Serial Data 123 Protected Counter Sync Message";
BA_ "SignalLongName" SG_ 1150 SD123P_MAC "Serial Data 123 Protected : MAC";
BA_ "SignalLongName" SG_ 1150 SD123P_FCnt "Serial Data 123 Protected : Freshness Counter";
BA_ "SignalLongName" SG_ 1150 VirtKeyIntrZnMblDevEntAlwdCnt "Serial Data 123 Protected : Virtual Key Interior Zone Mobile Device With Entry Allowed Count";
BA_ "SignalType" SG_ 1150 VirtKeyDrvrMblDevMemIdfr "ENM";
BA_ "SignalLongName" SG_ 1150 VirtKeyDrvrMblDevMemIdfr "Serial Data 123 Protected : Virtual Key Driver Mobile Device Memory Identifier";
BA_ "SignalType" SG_ 1150 VirtKeyMblDevRtEntAllwd "ENM";
BA_ "SignalLongName" SG_ 1150 VirtKeyMblDevRtEntAllwd "Serial Data 123 Protected : Virtual Key Mobile Device Right Entry Allowed";
BA_ "SignalType" SG_ 1150 VirtKeyMblDevRrCmptAccssAllwd "ENM";
BA_ "SignalLongName" SG_ 1150 VirtKeyMblDevRrCmptAccssAllwd "Serial Data 123 Protected : Virtual Key Mobile Device Rear Compartment Access Allowed";
BA_ "SignalType" SG_ 1150 VirtKeyMblDevLtEntAllwd "ENM";
BA_ "SignalLongName" SG_ 1150 VirtKeyMblDevLtEntAllwd "Serial Data 123 Protected : Virtual Key Mobile Device Left Entry Allowed";
BA_ "SignalType" SG_ 1150 VirtKeyMblDevFrtCmptAccssAllwd "ENM";
BA_ "SignalLongName" SG_ 1150 VirtKeyMblDevFrtCmptAccssAllwd "Serial Data 123 Protected : Virtual Key Mobile Device Front Compartment Access Allowed";
BA_ "SignalLongName" SG_ 1150 VirtKeyIntrZnMblDevStrtgAlwdCnt "Serial Data 123 Protected : Virtual Key Interior Zone Mobile Device With Starting Allowed Count";
BA_ "SignalLongName" SG_ 1150 SD123P_Filler "Serial Data 123 Protected : Filler";
BA_ "SignalType" SG_ 1150 VirtKeyWlcmZnMblDevPrsnt "ENM";
BA_ "SignalLongName" SG_ 1150 VirtKeyWlcmZnMblDevPrsnt "Serial Data 123 Protected : Virtual Key Welcome Zone Mobile Device Present";
BA_ "SignalLongName" SG_ 1152 SrlDat124_PCSM "Serial Data 124 Protected Counter Sync Message";
BA_ "SignalLongName" SG_ 1149 SD124P_MAC "Serial Data 124 Protected : MAC";
BA_ "SignalLongName" SG_ 1149 SD124P_FCnt "Serial Data 124 Protected : Freshness Counter";
BA_ "SignalType" SG_ 1149 VirtKeyAllDrLckReqd "ENM";
BA_ "SignalLongName" SG_ 1149 VirtKeyAllDrLckReqd "Serial Data 124 Protected : Virtual Key All Door Lock Requested";
BA_ "SignalType" SG_ 1149 VirtKeyPncReq "ENM";
BA_ "SignalLongName" SG_ 1149 VirtKeyPncReq "Serial Data 124 Protected : Virtual Key Panic Request";
BA_ "SignalType" SG_ 1149 VirtKeyFobAvlReq "ENM";
BA_ "SignalLongName" SG_ 1149 VirtKeyFobAvlReq "Serial Data 124 Protected : Virtual Key Fob Availability Request";
BA_ "SignalType" SG_ 1149 VirtKeyRmtLctrReq "ENM";
BA_ "SignalLongName" SG_ 1149 VirtKeyRmtLctrReq "Serial Data 124 Protected : Virtual Key Remote Locator Request";
BA_ "SignalType" SG_ 1149 SRPCrsFrtInSftBtnMblDevSts "ENM";
BA_ "SignalLongName" SG_ 1149 SRPCrsFrtInSftBtnMblDevSts "Serial Data 124 Protected : Supervised Remote Parking Cross Front-In Soft Button Mobile Device Status";
BA_ "SignalType" SG_ 1149 SRPCrsBkInSftBtnMblDevSts "ENM";
BA_ "SignalLongName" SG_ 1149 SRPCrsBkInSftBtnMblDevSts "Serial Data 124 Protected : Supervised Remote Parking Cross Back-In Soft Button Mobile Device Status";
BA_ "SignalType" SG_ 1149 VirtKeyRrClsrUnlckReqd "ENM";
BA_ "SignalLongName" SG_ 1149 VirtKeyRrClsrUnlckReqd "Serial Data 124 Protected : Virtual Key Rear Closure Unlock Requested";
BA_ "SignalType" SG_ 1149 VirtKeyRrClsrLckReqd "ENM";
BA_ "SignalLongName" SG_ 1149 VirtKeyRrClsrLckReqd "Serial Data 124 Protected : Virtual Key Rear Closure Lock Requested";
BA_ "SignalType" SG_ 1149 VirtKeyFrtClsrUnlckReqd "ENM";
BA_ "SignalLongName" SG_ 1149 VirtKeyFrtClsrUnlckReqd "Serial Data 124 Protected : Virtual Key Front Closure Unlock Requested";
BA_ "SignalType" SG_ 1149 VirtKeyFrtClsrLckReqd "ENM";
BA_ "SignalLongName" SG_ 1149 VirtKeyFrtClsrLckReqd "Serial Data 124 Protected : Virtual Key Front Closure Lock Requested";
BA_ "SignalType" SG_ 1149 VirtKeyDrvrDrUnlckReqd "ENM";
BA_ "SignalLongName" SG_ 1149 VirtKeyDrvrDrUnlckReqd "Serial Data 124 Protected : Virtual Key Driver Door Unlock Requested";
BA_ "SignalType" SG_ 1149 VirtKeyAllDrUnlckReqd "ENM";
BA_ "SignalLongName" SG_ 1149 VirtKeyAllDrUnlckReqd "Serial Data 124 Protected : Virtual Key All Door Unlock Requested";
BA_ "SignalLongName" SG_ 1149 SD124P_Filler "Serial Data 124 Protected : Filler";
BA_ "SignalType" SG_ 1149 SRPExplrModeSftBtnMblDevSts "ENM";
BA_ "SignalLongName" SG_ 1149 SRPExplrModeSftBtnMblDevSts "Serial Data 124 Protected : Supervised Remote Parking Explore Mode Soft Button Mobile Device Status";
BA_ "SignalType" SG_ 1149 SRPSrchingSftBtnMblDevSts "ENM";
BA_ "SignalLongName" SG_ 1149 SRPSrchingSftBtnMblDevSts "Serial Data 124 Protected : Supervised Remote Parking Searching Soft Button Mobile Device Status";
BA_ "SignalType" SG_ 1149 SRPRtSftBtnMblDevSts "ENM";
BA_ "SignalLongName" SG_ 1149 SRPRtSftBtnMblDevSts "Serial Data 124 Protected : Supervised Remote Parking Right Soft Button Mobile Device Status";
BA_ "SignalType" SG_ 1149 SRPPrlllPrkSftBtnMblDevSts "ENM";
BA_ "SignalLongName" SG_ 1149 SRPPrlllPrkSftBtnMblDevSts "Serial Data 124 Protected : Supervised Remote Parking Parallel Parking Soft Button Mobile Device Status";
BA_ "SignalType" SG_ 1149 SRPLtSftBtnMblDevSts "ENM";
BA_ "SignalLongName" SG_ 1149 SRPLtSftBtnMblDevSts "Serial Data 124 Protected : Supervised Remote Parking Left Soft Button Mobile Device Status";
BA_ "SignalType" SG_ 1149 SRPExtPrkSftBtnMblDevSts "ENM";
BA_ "SignalLongName" SG_ 1149 SRPExtPrkSftBtnMblDevSts "Serial Data 124 Protected : Supervised Remote Parking Exit Park Soft Button Mobile Device Status";
BA_ "SignalLongName" SG_ 1149 SD124P_ARC "Serial Data 124 Protected : Alive Rolling Count";
BA_ "SignalLongName" SG_ 972 SrlDat125_PCSM "Serial Data 125 Protected Counter Sync Message";
BA_ "SignalLongName" SG_ 586 SD125P_MAC "Serial Data 125 Protected : MAC";
BA_ "SignalLongName" SG_ 586 SD125P_FCnt "Serial Data 125 Protected : Freshness Counter";
BA_ "SignalType" SG_ 586 VirtKeyPwrTopCtlReqrMblDevIdfr "ENM";
BA_ "SignalLongName" SG_ 586 VirtKeyPwrTopCtlReqrMblDevIdfr "Serial Data 125 Protected : Virtual Key Power Top Control Requestor Mobile Device Identifier";
BA_ "SignalLongName" SG_ 586 VirtKeyVehCbnACTempLvl "Serial Data 125 Protected : Virtual Key Vehicle Cabin Air Conditioning Temperature Level";
BA_ "SignalType" SG_ 586 VirtKeyPwrTopCtlReq "ENM";
BA_ "SignalLongName" SG_ 586 VirtKeyPwrTopCtlReq "Serial Data 125 Protected : Virtual Key Power Top Control Request";
BA_ "SignalType" SG_ 586 VirtKeyPwrRrClsrCtlReq "ENM";
BA_ "SignalLongName" SG_ 586 VirtKeyPwrRrClsrCtlReq "Serial Data 125 Protected : Virtual Key Power Rear Closure Control Request";
BA_ "SignalType" SG_ 586 VirtKeyFrtClsrCtlReq "ENM";
BA_ "SignalLongName" SG_ 586 VirtKeyFrtClsrCtlReq "Serial Data 125 Protected : Virtual Key Front Closure Control Request";
BA_ "SignalType" SG_ 586 VirtKeyWndCtlReq "ENM";
BA_ "SignalLongName" SG_ 586 VirtKeyWndCtlReq "Serial Data 125 Protected : Virtual Key Window Control Request";
BA_ "SignalType" SG_ 586 VirtKeyVehCbnACReq "ENM";
BA_ "SignalLongName" SG_ 586 VirtKeyVehCbnACReq "Serial Data 125 Protected : Virtual Key Vehicle Cabin Air Conditioning Request";
BA_ "SignalType" SG_ 586 VirtKeySnrfCtlReq "ENM";
BA_ "SignalLongName" SG_ 586 VirtKeySnrfCtlReq "Serial Data 125 Protected : Virtual Key Sunroof Control Request";
BA_ "SignalLongName" SG_ 586 SD125P_ARC "Serial Data 125 Protected : Alive Rolling Count";
BA_ "SignalLongName" SG_ 586 SD125P_Filler "Serial Data 125 Protected : Filler";
BA_ "SignalType" SG_ 586 SRPMblDevDctvBtnSts "ENM";
BA_ "SignalLongName" SG_ 586 SRPMblDevDctvBtnSts "Serial Data 125 Protected : Supervised Remote Parking Deactivation Soft Button Mobile Device Status";
BA_ "SignalType" SG_ 586 VirtKeyVehCbnACTempLvlReqActv "ENM";
BA_ "SignalLongName" SG_ 586 VirtKeyVehCbnACTempLvlReqActv "Serial Data 125 Protected : Virtual Key Vehicle Cabin Air Conditioning Temperature Level Request Active";
BA_ "SignalType" SG_ 586 VirtKeyRrClsrRelReqd "ENM";
BA_ "SignalLongName" SG_ 586 VirtKeyRrClsrRelReqd "Serial Data 125 Protected : Virtual Key Rear Closure Release Requested";
BA_ "SignalLongName" SG_ 1151 SrlDat126_PCSM "Serial Data 126 Protected Counter Sync Message";
BA_ "SignalLongName" SG_ 1148 SD126P_MAC "Serial Data 126 Protected : MAC";
BA_ "SignalLongName" SG_ 1148 SD126P_FCnt "Serial Data 126 Protected : Freshness Counter";
BA_ "SignalType" SG_ 1148 HiVltgBatThrmlRnwyIndReq "ENM";
BA_ "SignalLongName" SG_ 1148 HiVltgBatThrmlRnwyIndReq "Serial Data 126 Protected : High Voltage Battery Thermal Runaway Indication Request";
BA_ "SignalType" SG_ 1148 CbnPrcndtngSchReq "ENM";
BA_ "SignalLongName" SG_ 1148 CbnPrcndtngSchReq "Serial Data 126 Protected : Cabin Preconditioning Schedule Request";
BA_ "SignalLongName" SG_ 1148 CbnPrcndtngSchTempLvlReq "Serial Data 126 Protected : Cabin Preconditioning Schedule Temperature Level Request";
BA_ "SignalLongName" SG_ 1148 CustUsblSOCAuth "Serial Data 126 Protected : Customer Usable State of Charge Authenticated";
BA_ "SignalType" SG_ 1148 CbnPrcndtngSchTempLvlReqAtv "ENM";
BA_ "SignalLongName" SG_ 1148 CbnPrcndtngSchTempLvlReqAtv "Serial Data 126 Protected : Cabin Preconditioning Schedule Temperature Level Request Active";
BA_ "SignalLongName" SG_ 1148 SD126P_Filler "Serial Data 126 Protected : Filler";
BA_ "SignalType" SG_ 1148 CustUsblSOCAuth_Inv "ENM";
BA_ "SignalLongName" SG_ 1148 CustUsblSOCAuth_Inv "Serial Data 126 Protected : Customer Usable State of Charge Authenticated Invalid";
BA_ "SignalType" SG_ 1148 CustUsblSOCAuth_DuD "ENM";
BA_ "SignalLongName" SG_ 1148 CustUsblSOCAuth_DuD "Serial Data 126 Protected : Customer Usable State of Charge Authenticated Don't Use Data";
BA_ "SignalType" SG_ 1148 HiVltgBatOutOfEngyIndReqAuth "ENM";
BA_ "SignalLongName" SG_ 1148 HiVltgBatOutOfEngyIndReqAuth "Serial Data 126 Protected : High Voltage Battery Out of Energy Indication Request Authenticated";
BA_ "SignalLongName" SG_ 1148 SD126P_ARC "Serial Data 126 Protected : Alive Rolling Count";
BA_ "SignalLongName" SG_ 694 SrlDat15_PCSM "Serial Data 15 Protected Counter Sync Message";
BA_ "SignalLongName" SG_ 635 SD15P_MAC "Serial Data 15 Protected : MAC";
BA_ "SignalLongName" SG_ 635 SD15P_FCnt "Serial Data 15 Protected : Freshness Counter";
BA_ "SignalType" SG_ 635 EPBSP_ElecPrkBrkAvlStsAuth "ENM";
BA_ "SignalLongName" SG_ 635 EPBSP_ElecPrkBrkAvlStsAuth "Serial Data 15 Protected : Electric Park Brake Availability Status Authenticated";
BA_ "SignalType" SG_ 635 EPBSP_ElecPrkBrkApplStsAuth "ENM";
BA_ "SignalLongName" SG_ 635 EPBSP_ElecPrkBrkApplStsAuth "Serial Data 15 Protected : Electric Park Brake Application Status Authenticated";
BA_ "SignalType" SG_ 635 EPBSP_EPBSysBrkLgtsReqdAuth "ENM";
BA_ "SignalLongName" SG_ 635 EPBSP_EPBSysBrkLgtsReqdAuth "Serial Data 15 Protected : Electric Park Brake System Brake Lights Requested Authenticated";
BA_ "SignalType" SG_ 635 EPBSP_BrkSysBrkLgtsReqdAuth "ENM";
BA_ "SignalLongName" SG_ 635 EPBSP_BrkSysBrkLgtsReqdAuth "Serial Data 15 Protected : Brake System Brake Lights Requested Authenticated";
BA_ "SignalType" SG_ 635 DMCP_EnvIdRsp2Auth "ENM";
BA_ "SignalLongName" SG_ 635 DMCP_EnvIdRsp2Auth "Serial Data 15 Protected : Environment Module Present Responder 2 Authenticated";
BA_ "SignalLongName" SG_ 635 TBIP_TrlrBrkgGainSetAuth "Serial Data 15 Protected : Trailer Braking Gain Setting Authenticated";
BA_ "SignalType" SG_ 635 TBIP_TrlrBrkDsbldIndOnAuth "ENM";
BA_ "SignalLongName" SG_ 635 TBIP_TrlrBrkDsbldIndOnAuth "Serial Data 15 Protected : Trailer Brakes Disabled Indication On Authenticated";
BA_ "SignalType" SG_ 635 TBIP_ServTrlrBrkgSysIndOnAuth "ENM";
BA_ "SignalLongName" SG_ 635 TBIP_ServTrlrBrkgSysIndOnAuth "Serial Data 15 Protected : Service Trailer Braking System Indication On Authenticated";
BA_ "SignalType" SG_ 635 TBIP_CkTrlrIndOnAuth "ENM";
BA_ "SignalLongName" SG_ 635 TBIP_CkTrlrIndOnAuth "Serial Data 15 Protected : Check Trailer Indication On Authenticated";
BA_ "SignalType" SG_ 635 EPBSP_TrlrBrkgSysBrkLgtsRqdAuth "ENM";
BA_ "SignalLongName" SG_ 635 EPBSP_TrlrBrkgSysBrkLgtsRqdAuth "Serial Data 15 Protected : Trailer Braking System Brake Lights Requested Authenticated";
BA_ "SignalLongName" SG_ 635 SD15P_ARC "Serial Data 15 Protected : Alive Rolling Count";
BA_ "SignalType" SG_ 635 TBIP_TrlrWrgFltIndOnAuth "ENM";
BA_ "SignalLongName" SG_ 635 TBIP_TrlrWrgFltIndOnAuth "Serial Data 15 Protected : Trailer Wiring Fault Indication On Authenticated";
BA_ "SignalType" SG_ 635 TBIP_TrlrBrkgGainSetIndOnAuth "ENM";
BA_ "SignalLongName" SG_ 635 TBIP_TrlrBrkgGainSetIndOnAuth "Serial Data 15 Protected : Trailer Braking Gain Setting Indication On Authenticated";
BA_ "SignalLongName" SG_ 635 SD15P_Filler "Serial Data 15 Protected : Filler";
BA_ "SignalType" SG_ 635 BrkSysActvHldActv "ENM";
BA_ "SignalLongName" SG_ 635 BrkSysActvHldActv "Serial Data 15 Protected : Brake System Active Hold Active";
BA_ "SignalType" SG_ 635 BrkSysVehHldReqShfPrk "ENM";
BA_ "SignalLongName" SG_ 635 BrkSysVehHldReqShfPrk "Serial Data 15 Protected : Brake System Vehicle Hold Request Shift to Park";
BA_ "SignalType" SG_ 635 ElecPrkBrkMnPriPerfRdcd "ENM";
BA_ "SignalLongName" SG_ 635 ElecPrkBrkMnPriPerfRdcd "Serial Data 15 Protected : Electric Park Brake Main Primary Performance Reduced";
BA_ "SignalType" SG_ 635 TrlrBrkgRdcdIndOn "ENM";
BA_ "SignalLongName" SG_ 635 TrlrBrkgRdcdIndOn "Serial Data 15 Protected : Trailer Braking Reduced Indication On";
BA_ "SignalType" SG_ 635 TrlrBrkgHldLstKnwnGainIndOn "ENM";
BA_ "SignalLongName" SG_ 635 TrlrBrkgHldLstKnwnGainIndOn "Serial Data 15 Protected : Trailer Braking Hold Last Known Gain Indication On";
BA_ "SignalLongName" SG_ 1404 SrlDat22_PCSM "Serial Data 22 Protected Counter Sync Message";
BA_ "SignalLongName" SG_ 879 SD22P_MAC "Serial Data 22 Protected : MAC";
BA_ "SignalLongName" SG_ 879 SD22P_FCnt "Serial Data 22 Protected : Freshness Counter";
BA_ "SignalLongName" SG_ 879 EGI3P_CnvtTpSpLimRspValAuth "Serial Data 22 Protected : Convertible Top Speed Limit Response Value Authenticated";
BA_ "SignalType" SG_ 879 EGI3P_CnvtTpSpLimRspTypAuth "ENM";
BA_ "SignalLongName" SG_ 879 EGI3P_CnvtTpSpLimRspTypAuth "Serial Data 22 Protected : Convertible Top Speed Limit Response Type Authenticated";
BA_ "SignalType" SG_ 879 PSP_PrkNeutSwStatAuth_Inv "ENM";
BA_ "SignalLongName" SG_ 879 PSP_PrkNeutSwStatAuth_Inv "Serial Data 22 Protected : Park Neutral Switch State Authenticated Invalid";
BA_ "SignalType" SG_ 879 PSP_PrkNeutSwStatAuth "ENM";
BA_ "SignalLongName" SG_ 879 PSP_PrkNeutSwStatAuth "Serial Data 22 Protected : Park Neutral Switch State Authenticated";
BA_ "SignalType" SG_ 879 PSP_EngRnngAuth "ENM";
BA_ "SignalLongName" SG_ 879 PSP_EngRnngAuth "Serial Data 22 Protected : Engine Running Authenticated";
BA_ "SignalType" SG_ 879 PSP_ClchBtmTrvlAchvdAuth_Inv "ENM";
BA_ "SignalLongName" SG_ 879 PSP_ClchBtmTrvlAchvdAuth_Inv "Serial Data 22 Protected : Clutch Bottom of Travel Achieved Authenticated Invalid";
BA_ "SignalType" SG_ 879 PSP_ClchBtmTrvlAchvdAuth "ENM";
BA_ "SignalLongName" SG_ 879 PSP_ClchBtmTrvlAchvdAuth "Serial Data 22 Protected : Clutch Bottom of Travel Achieved Authenticated";
BA_ "SignalLongName" SG_ 879 SD22P_ARC "Serial Data 22 Protected : Alive Rolling Count";
BA_ "SignalType" SG_ 879 PSP_VehTheftImbChlgRespStsAuth "ENM";
BA_ "SignalLongName" SG_ 879 PSP_VehTheftImbChlgRespStsAuth "Serial Data 22 Protected : Vehicle Theft Immobilizer Challenge Response Status Authenticated";
BA_ "SignalType" SG_ 879 PSP_RmtVehStrtEngRnngAuth "ENM";
BA_ "SignalLongName" SG_ 879 PSP_RmtVehStrtEngRnngAuth "Serial Data 22 Protected : Remote Vehicle Start Engine Running Authenticated";
BA_ "SignalType" SG_ 879 PSP_PwrtrnCrnkAbrtdAuth "ENM";
BA_ "SignalLongName" SG_ 879 PSP_PwrtrnCrnkAbrtdAuth "Serial Data 22 Protected : Powertrain Crank Aborted Authenticated";
BA_ "SignalType" SG_ 879 PSP_PrplSysStlActvAuth "ENM";
BA_ "SignalLongName" SG_ 879 PSP_PrplSysStlActvAuth "Serial Data 22 Protected : Propulsion System Stall Active Authenticated";
BA_ "SignalType" SG_ 879 PSP_PrplSysActvAuth "ENM";
BA_ "SignalLongName" SG_ 879 PSP_PrplSysActvAuth "Serial Data 22 Protected : Propulsion System Active Authenticated";
BA_ "SignalLongName" SG_ 879 SD22P_Filler "Serial Data 22 Protected : Filler";
BA_ "SignalType" SG_ 879 PrplBrkThrotOvrrdReqd "ENM";
BA_ "SignalLongName" SG_ 879 PrplBrkThrotOvrrdReqd "Serial Data 22 Protected : Propulsion Brake Throttle Override Requested";
BA_ "SignalLongName" SG_ 1949 SrlDat234_PCSM "Serial Data 234 Protected Counter Sync Message";
BA_ "SignalLongName" SG_ 1117 SD234P_MAC "Serial Data 234 Protected : MAC";
BA_ "SignalLongName" SG_ 1117 SD234P_FCnt "Serial Data 234 Protected : Freshness Counter";
BA_ "SignalType" SG_ 1117 APALtSftBtnReq "ENM";
BA_ "SignalLongName" SG_ 1117 APALtSftBtnReq "Serial Data 234 Protected : Advanced Park Assist Left Soft Button Request";
BA_ "SignalType" SG_ 1117 APAExtPrkSftBtnReq "ENM";
BA_ "SignalLongName" SG_ 1117 APAExtPrkSftBtnReq "Serial Data 234 Protected : Advanced Park Assist Exit Park Soft Button Request";
BA_ "SignalType" SG_ 1117 APACrsFrtInSftBtnReq "ENM";
BA_ "SignalLongName" SG_ 1117 APACrsFrtInSftBtnReq "Serial Data 234 Protected : Advanced Park Assist Cross Front-In Soft Button Request";
BA_ "SignalType" SG_ 1117 APACrsBkInSftBtnReq "ENM";
BA_ "SignalLongName" SG_ 1117 APACrsBkInSftBtnReq "Serial Data 234 Protected : Advanced Park Assist Cross Back-In Soft Button Request";
BA_ "SignalType" SG_ 1117 APAExplrModeSftBtnReq "ENM";
BA_ "SignalLongName" SG_ 1117 APAExplrModeSftBtnReq "Serial Data 234 Protected : Advanced Park Assist Explore Mode Soft Button Request";
BA_ "SignalType" SG_ 1117 APASrchingSftBtnReq "ENM";
BA_ "SignalLongName" SG_ 1117 APASrchingSftBtnReq "Serial Data 234 Protected : Advanced Park Assist Searching Soft Button Request";
BA_ "SignalType" SG_ 1117 APARtSftBtnReq "ENM";
BA_ "SignalLongName" SG_ 1117 APARtSftBtnReq "Serial Data 234 Protected : Advanced Park Assist Right Soft Button Request";
BA_ "SignalType" SG_ 1117 APAPrllPrkSftBtnReq "ENM";
BA_ "SignalLongName" SG_ 1117 APAPrllPrkSftBtnReq "Serial Data 234 Protected : Advanced Park Assist Parallel Parking Soft Button Request";
BA_ "SignalLongName" SG_ 1117 SD234P_Filler "Serial Data 234 Protected : Filler";
BA_ "SignalLongName" SG_ 1117 SD234P_ARC "Serial Data 234 Protected : Alive Rolling Count";
BA_ "SignalLongName" SG_ 1958 SrlDat253_PCSM "Serial Data 253 Protected Counter Sync Message";
BA_ "SignalLongName" SG_ 1108 SD253P_MAC "Serial Data 253 Protected : MAC";
BA_ "SignalLongName" SG_ 1108 SD253P_FCnt "Serial Data 253 Protected : Freshness Counter";
BA_ "SignalType" SG_ 1108 FltDrvrActvRmtCstChgSetReq "ENM";
BA_ "SignalLongName" SG_ 1108 FltDrvrActvRmtCstChgSetReq "Serial Data 253 Protected : Fleet Driver Active Remote Customization Change Setting Request";
BA_ "SignalType" SG_ 1108 TnDrvrSpdLimRmtCstChgSetReq "ENM";
BA_ "SignalLongName" SG_ 1108 TnDrvrSpdLimRmtCstChgSetReq "Serial Data 253 Protected : Teen Driver Speed Limit Remote Customization Change Setting Request";
BA_ "SignalType" SG_ 1108 TnDrvrActvRmtCstChgSetReq "ENM";
BA_ "SignalLongName" SG_ 1108 TnDrvrActvRmtCstChgSetReq "Serial Data 253 Protected : Teen Driver Active Remote Customization Change Setting Request";
BA_ "SignalLongName" SG_ 1108 VSEMBatSOCDpltnLvlRmtCtlReq "Serial Data 253 Protected : Vehicle State Extend Mode Battery State of Charge Depletion Level Remote Control Request";
BA_ "SignalType" SG_ 1108 VSEMOpRmtCtlReq "ENM";
BA_ "SignalLongName" SG_ 1108 VSEMOpRmtCtlReq "Serial Data 253 Protected : Vehicle State Extend Mode Operation Remote Control Request";
BA_ "SignalLongName" SG_ 1108 VSEMTmDurRmtCtlReq "Serial Data 253 Protected : Vehicle State Extend Mode Time Duration Remote Control Request";
BA_ "SignalLongName" SG_ 1108 SD253P_ARC "Serial Data 253 Protected : Alive Rolling Count";
BA_ "SignalLongName" SG_ 1108 SD253P_Filler "Serial Data 253 Protected : Filler";
BA_ "SignalLongName" SG_ 1107 SrlDat254_PCSM "Serial Data 254 Protected Counter Sync Message";
BA_ "SignalLongName" SG_ 1105 SD254P_MAC "Serial Data 254 Protected : MAC";
BA_ "SignalLongName" SG_ 1105 SD254P_FCnt "Serial Data 254 Protected : Freshness Counter";
BA_ "SignalType" SG_ 1105 SCAOOAByVirtKeyLFCstChgSetReq "ENM";
BA_ "SignalLongName" SG_ 1105 SCAOOAByVirtKeyLFCstChgSetReq "Serial Data 254 Protected : Side Closure Access Open On Approach By Virtual Key Left Front Customization Change Setting Request";
BA_ "SignalType" SG_ 1105 SCAOOAByKeyFobRFCstChgSetReq "ENM";
BA_ "SignalLongName" SG_ 1105 SCAOOAByKeyFobRFCstChgSetReq "Serial Data 254 Protected : Side Closure Access Open On Approach By Key Fob Right Front Customization Change Setting Request";
BA_ "SignalType" SG_ 1105 SCAOOAByKeyFobLFCstChgSetReq "ENM";
BA_ "SignalLongName" SG_ 1105 SCAOOAByKeyFobLFCstChgSetReq "Serial Data 254 Protected : Side Closure Access Open On Approach By Key Fob Left Front Customization Change Setting Request";
BA_ "SignalType" SG_ 1105 SCAPwrDrMtnLRVirtCtlFrtReq "ENM";
BA_ "SignalLongName" SG_ 1105 SCAPwrDrMtnLRVirtCtlFrtReq "Serial Data 254 Protected : Side Closure Access Power Door Motion Left Rear Virtual Control Front Request";
BA_ "SignalType" SG_ 1105 SCAPwrDrMtnLFVirtCtlReq "ENM";
BA_ "SignalLongName" SG_ 1105 SCAPwrDrMtnLFVirtCtlReq "Serial Data 254 Protected : Side Closure Access Power Door Motion Left Front Virtual Control Request";
BA_ "SignalType" SG_ 1105 SCAOOAByVirtKeyRFCstChgSetReq "ENM";
BA_ "SignalLongName" SG_ 1105 SCAOOAByVirtKeyRFCstChgSetReq "Serial Data 254 Protected : Side Closure Access Open On Approach By Virtual Key Right Front Customization Change Setting Request";
BA_ "SignalType" SG_ 1105 SCAPwrDrMtnRFVirtCtlReq "ENM";
BA_ "SignalLongName" SG_ 1105 SCAPwrDrMtnRFVirtCtlReq "Serial Data 254 Protected : Side Closure Access Power Door Motion Right Front Virtual Control Request";
BA_ "SignalType" SG_ 1105 SCAPwrDrMtnLRVirtCtlRrReq "ENM";
BA_ "SignalLongName" SG_ 1105 SCAPwrDrMtnLRVirtCtlRrReq "Serial Data 254 Protected : Side Closure Access Power Door Motion Left Rear Virtual Control Rear Request";
BA_ "SignalLongName" SG_ 1105 SD254P_Filler "Serial Data 254 Protected : Filler";
BA_ "SignalType" SG_ 1105 SCAOOAExclnZnActv "ENM";
BA_ "SignalLongName" SG_ 1105 SCAOOAExclnZnActv "Serial Data 254 Protected : Side Closure Access Open On Approach Exclusion Zone Active";
BA_ "SignalType" SG_ 1105 SCAPwrDrMtnRRVirtCtlRrReq "ENM";
BA_ "SignalLongName" SG_ 1105 SCAPwrDrMtnRRVirtCtlRrReq "Serial Data 254 Protected : Side Closure Access Power Door Motion Right Rear Virtual Control Rear Request";
BA_ "SignalType" SG_ 1105 SCAPwrDrMtnRRVirtCtlFrtReq "ENM";
BA_ "SignalLongName" SG_ 1105 SCAPwrDrMtnRRVirtCtlFrtReq "Serial Data 254 Protected : Side Closure Access Power Door Motion Right Rear Virtual Control Front Request";
BA_ "SignalLongName" SG_ 1960 SrlDat255_PCSM "Serial Data 255 Protected Counter Sync Message";
BA_ "SignalLongName" SG_ 1104 SD255P_MAC "Serial Data 255 Protected : MAC";
BA_ "SignalLongName" SG_ 1104 SD255P_FCnt "Serial Data 255 Protected : Freshness Counter";
BA_ "SignalType" SG_ 1104 DMBlkhdDrUnltchPrkCstChgSetReq "ENM";
BA_ "SignalLongName" SG_ 1104 DMBlkhdDrUnltchPrkCstChgSetReq "Serial Data 255 Protected : Delivery Mode Bulkhead Door Unlatch on Park Customization Change Setting Request";
BA_ "SignalType" SG_ 1104 DMBlkhdDrUnlckPrkCstChgSetReq "ENM";
BA_ "SignalLongName" SG_ 1104 DMBlkhdDrUnlckPrkCstChgSetReq "Serial Data 255 Protected : Delivery Mode Bulkhead Door Unlock on Park Customization Change Setting Request";
BA_ "SignalType" SG_ 1104 DMBlkhdDrOpnVehOffCstChgSetReq "ENM";
BA_ "SignalLongName" SG_ 1104 DMBlkhdDrOpnVehOffCstChgSetReq "Serial Data 255 Protected : Delivery Mode Bulkhead Door Open on Vehicle Off Customization Change Setting Request";
BA_ "SignalType" SG_ 1104 DMPDDOBlkhdDrOpnLFCstChgSetReq "ENM";
BA_ "SignalLongName" SG_ 1104 DMPDDOBlkhdDrOpnLFCstChgSetReq "Serial Data 255 Protected : Delivery Mode Power Door Delayed Open after Bulkhead Door Open Left Front Customization Change Setting Request";
BA_ "SignalType" SG_ 1104 DMDrvrDrUnlckPrkCstChgSetReq "ENM";
BA_ "SignalLongName" SG_ 1104 DMDrvrDrUnlckPrkCstChgSetReq "Serial Data 255 Protected : Delivery Mode Driver Door Unlock on Park Customization Change Setting Request";
BA_ "SignalType" SG_ 1104 DMCrbsdDrUnlckPrkCstChgSetReq "ENM";
BA_ "SignalLongName" SG_ 1104 DMCrbsdDrUnlckPrkCstChgSetReq "Serial Data 255 Protected : Delivery Mode Curbside Door Unlock on Park Customization Change Setting Request";
BA_ "SignalType" SG_ 1104 RrClsrAccssVirtCtlReq "ENM";
BA_ "SignalLongName" SG_ 1104 RrClsrAccssVirtCtlReq "Serial Data 255 Protected : Rear Closure Access Virtual Control Request";
BA_ "SignalType" SG_ 1104 FrtClsrAccssVirtCtlReq "ENM";
BA_ "SignalLongName" SG_ 1104 FrtClsrAccssVirtCtlReq "Serial Data 255 Protected : Front Closure Access Virtual Control Request";
BA_ "SignalType" SG_ 1104 DMPDDOBlkhdDrOpnRFCstChgSetReq "ENM";
BA_ "SignalLongName" SG_ 1104 DMPDDOBlkhdDrOpnRFCstChgSetReq "Serial Data 255 Protected : Delivery Mode Power Door Delayed Open after Bulkhead Door Open Right Front Customization Change Setting Request";
BA_ "SignalLongName" SG_ 1104 SD255P_Filler "Serial Data 255 Protected : Filler";
BA_ "SignalType" SG_ 1104 SCAPwrDrUnlckAllVirtCtlRrReq "ENM";
BA_ "SignalLongName" SG_ 1104 SCAPwrDrUnlckAllVirtCtlRrReq "Serial Data 255 Protected : Side Closure Access Power Door Unlock All Virtual Control Rear Request";
BA_ "SignalType" SG_ 1104 SCAPwrDrUnlckAllVirtCtlFrtReq "ENM";
BA_ "SignalLongName" SG_ 1104 SCAPwrDrUnlckAllVirtCtlFrtReq "Serial Data 255 Protected : Side Closure Access Power Door Unlock All Virtual Control Front Request";
BA_ "SignalType" SG_ 1104 SCAPwrDrLckAllVirtCtlRrReq "ENM";
BA_ "SignalLongName" SG_ 1104 SCAPwrDrLckAllVirtCtlRrReq "Serial Data 255 Protected : Side Closure Access Power Door Lock All Virtual Control Rear Request";
BA_ "SignalType" SG_ 1104 SCAPwrDrLckAllVirtCtlFrtReq "ENM";
BA_ "SignalLongName" SG_ 1104 SCAPwrDrLckAllVirtCtlFrtReq "Serial Data 255 Protected : Side Closure Access Power Door Lock All Virtual Control Front Request";
BA_ "SignalType" SG_ 1104 RstrCstDfltReqdAuth "ENM";
BA_ "SignalLongName" SG_ 1104 RstrCstDfltReqdAuth "Serial Data 255 Protected : Restore Customization Defaults Requested Authenticated";
BA_ "SignalLongName" SG_ 1106 SrlDat257_PCSM "Serial Data 257 Protected Counter Sync Message";
BA_ "SignalLongName" SG_ 1103 SD257P_MAC "Serial Data 257 Protected : MAC";
BA_ "SignalLongName" SG_ 1103 SD257P_FCnt "Serial Data 257 Protected : Freshness Counter";
BA_ "SignalType" SG_ 1103 SCAPwrDrMtnLRVirtKeyReq "ENM";
BA_ "SignalLongName" SG_ 1103 SCAPwrDrMtnLRVirtKeyReq "Serial Data 257 Protected : Side Closure Access Power Door Motion Left Rear Virtual Key Request";
BA_ "SignalType" SG_ 1103 SCAPwrDrMtnLFVirtKeyReqSrc "ENM";
BA_ "SignalLongName" SG_ 1103 SCAPwrDrMtnLFVirtKeyReqSrc "Serial Data 257 Protected : Side Closure Access Power Door Motion Left Front Virtual Key Request Source";
BA_ "SignalType" SG_ 1103 SCAPwrDrMtnLFVirtKeyReq "ENM";
BA_ "SignalLongName" SG_ 1103 SCAPwrDrMtnLFVirtKeyReq "Serial Data 257 Protected : Side Closure Access Power Door Motion Left Front Virtual Key Request";
BA_ "SignalType" SG_ 1103 SCAPwrDrMtnRFVirtKeyReqSrc "ENM";
BA_ "SignalLongName" SG_ 1103 SCAPwrDrMtnRFVirtKeyReqSrc "Serial Data 257 Protected : Side Closure Access Power Door Motion Right Front Virtual Key Request Source";
BA_ "SignalType" SG_ 1103 SCAPwrDrMtnRFVirtKeyReq "ENM";
BA_ "SignalLongName" SG_ 1103 SCAPwrDrMtnRFVirtKeyReq "Serial Data 257 Protected : Side Closure Access Power Door Motion Right Front Virtual Key Request";
BA_ "SignalType" SG_ 1103 SCAPwrDrMtnLRVirtKeyReqSrc "ENM";
BA_ "SignalLongName" SG_ 1103 SCAPwrDrMtnLRVirtKeyReqSrc "Serial Data 257 Protected : Side Closure Access Power Door Motion Left Rear Virtual Key Request Source";
BA_ "SignalType" SG_ 1103 SCAPwrDrMtnRRVirtKeyReqSrc "ENM";
BA_ "SignalLongName" SG_ 1103 SCAPwrDrMtnRRVirtKeyReqSrc "Serial Data 257 Protected : Side Closure Access Power Door Motion Right Rear Virtual Key Request Source";
BA_ "SignalType" SG_ 1103 SCAPwrDrMtnRRVirtKeyReq "ENM";
BA_ "SignalLongName" SG_ 1103 SCAPwrDrMtnRRVirtKeyReq "Serial Data 257 Protected : Side Closure Access Power Door Motion Right Rear Virtual Key Request";
BA_ "SignalLongName" SG_ 1103 SD257P_Filler "Serial Data 257 Protected : Filler";
BA_ "SignalType" SG_ 1103 SCAOOAShrtRngSysOneTmExclnActvd "ENM";
BA_ "SignalLongName" SG_ 1103 SCAOOAShrtRngSysOneTmExclnActvd "Serial Data 257 Protected : Side Closure Access Open On Approach Short Range System One Time Exclusion Activated";
BA_ "SignalLongName" SG_ 1974 SrlDat267_PCSM "Serial Data 267 Protected Counter Sync Message";
VAL_ 1345 EVSECmndPwrLimSts 0 "No Action" 1 "Normal" 2 "Station Derating" 3 "Vehicle Derating" ;
VAL_ 1345 DrSeltdOtltOfPwMdVirCtlNAlwdSts 0 "No Action" 1 "System Faulted_Service Needed" 2 "System Faulted_Customer Action" 3 "Vehicle Off" 4 "GFCI Fault" 5 "SOC Low" 6 "Vehicle Conditions Not Met" ;
VAL_ 1345 ShfFromNeutWrnIndOn 0 "FALSE" 1 "TRUE" ;
VAL_ 1345 NeutCstdwnCertModeWrnIndOn 0 "FALSE" 1 "TRUE" ;
VAL_ 1345 EVSECmndPwrLimAval 0 "FALSE" 1 "TRUE" ;
VAL_ 1345 OnbrdOtlt1OprtlSts 0 "Unavailable" 1 "Inactive" 2 "Energized" 3 "GFCI_Set" 4 "Faulted" ;
VAL_ 1345 OffbrdOtltsOvrloadIndOn 0 "FALSE" 1 "TRUE" ;
VAL_ 1345 DrvrSeltdOtltOffPwrMdVirCtlAvl 0 "Not Available" 1 "Available" ;
VAL_ 1345 DrvrSeltdOtltOffPwMdVirCtlAllwd 0 "Not Allowed" 1 "Allowed" ;
VAL_ 1345 DrSeltdOtltOffPwMdVirCtlSeltnVl 0 "No Request" 1 "Disabled" 2 "Enabled" ;
VAL_ 1345 OtltsOffPwrMdTmrActv 0 "FALSE" 1 "TRUE" ;
VAL_ 1345 OnbrdOtltsOvrloadIndOn 0 "FALSE" 1 "TRUE" ;
VAL_ 1345 OnbrdOtlt3OprtlSts 0 "Unavailable" 1 "Inactive" 2 "Energized" 3 "GFCI_Set" 4 "Faulted" ;
VAL_ 1345 OnbrdOtlt2OprtlSts 0 "Unavailable" 1 "Inactive" 2 "Energized" 3 "GFCI_Set" 4 "Faulted" ;
VAL_ 1294 SecRowLtPsStBltRmOccpSts 0 "Unknown" 1 "Empty" 2 "Occupied" ;
VAL_ 1294 SecRowCntrPsStBltSts_Inv 0 "FALSE" 1 "TRUE" ;
VAL_ 1294 SecRowCntrPsStBltSts 0 "Unknown" 1 "Unfastened" 2 "Fastened" ;
VAL_ 1294 SecRowCntrPsStBltRmOccpSts_Inv 0 "FALSE" 1 "TRUE" ;
VAL_ 1294 SecRowCntrPsStBltRmOccpSts 0 "Unknown" 1 "Empty" 2 "Occupied" ;
VAL_ 1294 SecRowRtPsStBltSts 0 "Unknown" 1 "Unfastened" 2 "Fastened" ;
VAL_ 1294 SecRowRtPsStBltRmOccpSts_Inv 0 "FALSE" 1 "TRUE" ;
VAL_ 1294 SecRowRtPsStBltRmOccpSts 0 "Unknown" 1 "Empty" 2 "Occupied" ;
VAL_ 1294 SecRowLtPsStBltSts_Inv 0 "FALSE" 1 "TRUE" ;
VAL_ 1294 SecRowLtPsStBltSts 0 "Unknown" 1 "Unfastened" 2 "Fastened" ;
VAL_ 1294 SecRowLtPsStBltRmOccpSts_Inv 0 "FALSE" 1 "TRUE" ;
VAL_ 1294 ThrdRowCntrPsStBltSts_Inv 0 "FALSE" 1 "TRUE" ;
VAL_ 1294 ThrdRowCntrPsStBltSts 0 "Unknown" 1 "Unfastened" 2 "Fastened" ;
VAL_ 1294 ThrdRowCntrPsStBltRmOccpSts_Inv 0 "FALSE" 1 "TRUE" ;
VAL_ 1294 ThrdRowCntrPsStBltRmOccpSts 0 "Unknown" 1 "Empty" 2 "Occupied" ;
VAL_ 1294 SecRowRtPsStBltSts_Inv 0 "FALSE" 1 "TRUE" ;
VAL_ 1294 ThrdRowRtPsStBltRmOccpSts 0 "Unknown" 1 "Empty" 2 "Occupied" ;
VAL_ 1294 ThrdRowLtPsStBltSts_Inv 0 "FALSE" 1 "TRUE" ;
VAL_ 1294 ThrdRowLtPsStBltSts 0 "Unknown" 1 "Unfastened" 2 "Fastened" ;
VAL_ 1294 ThrdRowLtPsStBltRmOccpSts_Inv 0 "FALSE" 1 "TRUE" ;
VAL_ 1294 ThrdRowLtPsStBltRmOccpSts 0 "Unknown" 1 "Empty" 2 "Occupied" ;
VAL_ 1294 ThrdRowRtPsStBltSts_Inv 0 "FALSE" 1 "TRUE" ;
VAL_ 1294 ThrdRowRtPsStBltSts 0 "Unknown" 1 "Unfastened" 2 "Fastened" ;
VAL_ 1294 ThrdRowRtPsStBltRmOccpSts_Inv 0 "FALSE" 1 "TRUE" ;
VAL_ 1137 ChrgSysCommActvReqd 0 "FALSE" 1 "TRUE" ;
VAL_ 1137 OffbrdEngyXferMinSOCResp_DuD 0 "FALSE" 1 "TRUE" ;
VAL_ 1137 OtltsOfPwMdElelEngUdThDschg_DuD 0 "FALSE" 1 "TRUE" ;
VAL_ 1137 OtltsOffPwrMdTmrOpCstSetVal 0 "No Action" 1 "Off" 2 "On" ;
VAL_ 1137 OtltsOffPwrMdSysActvTm_DuD 0 "FALSE" 1 "TRUE" ;
VAL_ 183 HiVltgChrgCtlPilotDiagDsblReqd 0 "FALSE" 1 "TRUE" ;
VAL_ 183 HiVltgChrgVntilationSwCmd 0 "No Action" 1 "Close" 2 "Open" ;
VAL_ 183 HiVltgChrgS2SwCmd 0 "No Action" 1 "Close" 2 "Open" ;
VAL_ 1931 OtltsOffPwrMdTmrRespVal_DuD 0 "FALSE" 1 "TRUE" ;
VAL_ 1931 OtltsOffPwrMdTmrRmnVal_DuD 0 "FALSE" 1 "TRUE" ;
VAL_ 1931 OtltsOffPwrMdTmrOpCstSetAval 0 "Not Available" 1 "Available" ;
VAL_ 1931 OffbrdEngyXferMinSOCAval 0 "Not Available" 1 "Available" ;
VAL_ 1135 OtltsOffPwrMdSysSts 0 "No Action" 1 "Inactive" 2 "Active" 3 "Complete" ;
VAL_ 1135 OffbrdOtltOprtlSts 0 "Unavailable" 1 "Inactive" 2 "Energized" 3 "GFCI_Set" 4 "Faulted" ;
VAL_ 1135 OnbrdOtltsWrnIndReq 0 "No Indication" 1 "GFI Reset" 2 "Service Reset Unavailable" 3 "Service Outlet Unavailable" 4 "Outlet Load Limit" 5 "Outlet Reduce Load" 6 "Charging Slowed" 7 "SOC Limit" 8 "Cold Temperature Limit" ;
VAL_ 1135 ChrgPortDrCurrStat 0 "Unknown" 1 "Open" 2 "Close" ;
VAL_ 1135 ChrgPortDrClsrUserCtlAllwd 0 "Not Allowed" 1 "Allowed" ;
VAL_ 1135 ChrgPortDrClsrVirtCtlAval 0 "Not Available" 1 "Available" ;
VAL_ 1135 OtltsOffPwrMdSysSts_Inv 0 "FALSE" 1 "TRUE" ;
VAL_ 1056 CntnsCrnkgDsbldIndOn 0 "FALSE" 1 "TRUE" ;
VAL_ 963 NodeStsADIMb_CAN_9_LcFA 0 "FALSE" 1 "TRUE" ;
VAL_ 963 NodeStsADIMb_CAN_3_LcFA 0 "FALSE" 1 "TRUE" ;
VAL_ 963 NodeStsADIMb_CAN_2_LcFA 0 "FALSE" 1 "TRUE" ;
VAL_ 963 NodeStsADIMb_CAN_10_LcFA 0 "FALSE" 1 "TRUE" ;
VAL_ 963 NodeStsADIMa_CAN_9_LcFA 0 "FALSE" 1 "TRUE" ;
VAL_ 963 NodeStsADIMa_CAN_3_LcFA 0 "FALSE" 1 "TRUE" ;
VAL_ 963 NodeStsADIMa_CAN_2_LcFA 0 "FALSE" 1 "TRUE" ;
VAL_ 963 NodeStsADIMa_CAN_10_LcFA 0 "FALSE" 1 "TRUE" ;
VAL_ 963 NodeStsAPA_CAN_1_LcFA 0 "FALSE" 1 "TRUE" ;
VAL_ 963 NodeStsAOS_LcFA 0 "FALSE" 1 "TRUE" ;
VAL_ 963 NodeStsAMP_LcFA 0 "FALSE" 1 "TRUE" ;
VAL_ 963 NodeStsALC_LcFA 0 "FALSE" 1 "TRUE" ;
VAL_ 963 NodeStsAHS_LcFA 0 "FALSE" 1 "TRUE" ;
VAL_ 963 NodeStsAHL_AFL_CAN_2_LcFA 0 "FALSE" 1 "TRUE" ;
VAL_ 963 NodeStsBSM_MH_LcFA 0 "FALSE" 1 "TRUE" ;
VAL_ 963 NodeStsBSM_CAN_3_LcFA 0 "FALSE" 1 "TRUE" ;
VAL_ 963 NodeStsBSM_CAN_2_LcFA 0 "FALSE" 1 "TRUE" ;
VAL_ 963 NodeStsBCM_LcFA 0 "FALSE" 1 "TRUE" ;
VAL_ 963 NodeStsARS_LcFA 0 "FALSE" 1 "TRUE" ;
VAL_ 963 NodeStsARB_LcFA 0 "FALSE" 1 "TRUE" ;
VAL_ 963 NodeStsAPA_CAN_2_LcFA 0 "FALSE" 1 "TRUE" ;
VAL_ 963 NodeStsEBCM_AV_CAN_2_LcFA 0 "FALSE" 1 "TRUE" ;
VAL_ 963 NodeStsDMS_LcFA 0 "FALSE" 1 "TRUE" ;
VAL_ 963 NodeStsDEFC_LcFA 0 "FALSE" 1 "TRUE" ;
VAL_ 963 NodeStsDCM_LcFA 0 "FALSE" 1 "TRUE" ;
VAL_ 963 NodeStsCSM_CAN_5_LcFA 0 "FALSE" 1 "TRUE" ;
VAL_ 963 NodeStsECP_E_CAN_9_LcFA 0 "FALSE" 1 "TRUE" ;
VAL_ 963 NodeStsECP_E_CAN_2_LcFA 0 "FALSE" 1 "TRUE" ;
VAL_ 963 NodeStsECM_CAN_3_LcFA 0 "FALSE" 1 "TRUE" ;
VAL_ 963 NodeStsECM_CAN_2_LcFA 0 "FALSE" 1 "TRUE" ;
VAL_ 963 NodeStsEBCM_CAN_3_LcFA 0 "FALSE" 1 "TRUE" ;
VAL_ 963 NodeStsEBCM_CAN_2_LcFA 0 "FALSE" 1 "TRUE" ;
VAL_ 963 NodeStsEBCM_AV_CAN_3_LcFA 0 "FALSE" 1 "TRUE" ;
VAL_ 963 NodeStsEOCM_CAN_3_LcFA 0 "FALSE" 1 "TRUE" ;
VAL_ 963 NodeStsEOCM_CAN_2_LcFA 0 "FALSE" 1 "TRUE" ;
VAL_ 963 NodeStsELM_LcFA 0 "FALSE" 1 "TRUE" ;
VAL_ 963 NodeStsECP_X1_CAN_3_LcFA 0 "FALSE" 1 "TRUE" ;
VAL_ 963 NodeStsECP_X1_CAN_2_LcFA 0 "FALSE" 1 "TRUE" ;
VAL_ 963 NodeStsECP_S_CAN_9_LcFA 0 "FALSE" 1 "TRUE" ;
VAL_ 963 NodeStsECP_S_CAN_2_LcFA 0 "FALSE" 1 "TRUE" ;
VAL_ 963 NodeStsECP_MC_LcFA 0 "FALSE" 1 "TRUE" ;
VAL_ 963 NodeStsEPSRAa_LcFA 0 "FALSE" 1 "TRUE" ;
VAL_ 963 NodeStsEPS_LcFA 0 "FALSE" 1 "TRUE" ;
VAL_ 963 NodeStsEPS_1_LcFA 0 "FALSE" 1 "TRUE" ;
VAL_ 963 NodeStsEOCM_HCP2_LcFA 0 "FALSE" 1 "TRUE" ;
VAL_ 963 NodeStsEOCM_HCP1_CAN_8_LcFA 0 "FALSE" 1 "TRUE" ;
VAL_ 963 NodeStsEOCM_HCP1_CAN_3_LcFA 0 "FALSE" 1 "TRUE" ;
VAL_ 963 NodeStsEOCM_HCP1_CAN_2_LcFA 0 "FALSE" 1 "TRUE" ;
VAL_ 963 NodeStsEOCM_CAN_8_LcFA 0 "FALSE" 1 "TRUE" ;
VAL_ 963 NodeStsHVAC_FP_F_LcFA 0 "FALSE" 1 "TRUE" ;
VAL_ 963 NodeStsHUD_CAN_LcFA 0 "FALSE" 1 "TRUE" ;
VAL_ 963 NodeStsHDLM_LcFA 0 "FALSE" 1 "TRUE" ;
VAL_ 963 NodeStsFOPM_CAN_3_LcFA 0 "FALSE" 1 "TRUE" ;
VAL_ 963 NodeStsFOPM_CAN_2_LcFA 0 "FALSE" 1 "TRUE" ;
VAL_ 963 NodeStsFCM_LcFA 0 "FALSE" 1 "TRUE" ;
VAL_ 963 NodeStsFCM_LC_LcFA 0 "FALSE" 1 "TRUE" ;
VAL_ 963 NodeStsEPSRAb_LcFA 0 "FALSE" 1 "TRUE" ;
VAL_ 964 NodeStsMFC_LcFA 0 "FALSE" 1 "TRUE" ;
VAL_ 964 NodeStsLRR_LcFA 0 "FALSE" 1 "TRUE" ;
VAL_ 964 NodeStsLIB1_LcFA 0 "FALSE" 1 "TRUE" ;
VAL_ 964 NodeStsIPC_CAN_5_LcFA 0 "FALSE" 1 "TRUE" ;
VAL_ 964 NodeStsICS_Info_LcFA 0 "FALSE" 1 "TRUE" ;
VAL_ 964 NodeStsICCM_CAN_3_LcFA 0 "FALSE" 1 "TRUE" ;
VAL_ 964 NodeStsHVAC_FP_R_LcFA 0 "FALSE" 1 "TRUE" ;
VAL_ 964 NodeStsMSM_RR_LcFA 0 "FALSE" 1 "TRUE" ;
VAL_ 964 NodeStsMSM_P_LcFA 0 "FALSE" 1 "TRUE" ;
VAL_ 964 NodeStsMSM_LR_LcFA 0 "FALSE" 1 "TRUE" ;
VAL_ 964 NodeStsMSM_D_LcFA 0 "FALSE" 1 "TRUE" ;
VAL_ 964 NodeStsMSB2_LcFA 0 "FALSE" 1 "TRUE" ;
VAL_ 964 NodeStsMSB1_LcFA 0 "FALSE" 1 "TRUE" ;
VAL_ 964 NodeStsMRCM_R_LcFA 0 "FALSE" 1 "TRUE" ;
VAL_ 964 NodeStsMRCM_L_LcFA 0 "FALSE" 1 "TRUE" ;
VAL_ 964 NodeStsRDCM_LcFA 0 "FALSE" 1 "TRUE" ;
VAL_ 964 NodeStsRadioLow_LcFA 0 "FALSE" 1 "TRUE" ;
VAL_ 964 NodeStsPTM_LcFA 0 "FALSE" 1 "TRUE" ;
VAL_ 964 NodeStsPDR_LcFA 0 "FALSE" 1 "TRUE" ;
VAL_ 964 NodeStsPA_LcFA 0 "FALSE" 1 "TRUE" ;
VAL_ 964 NodeStsNVM_LcFA 0 "FALSE" 1 "TRUE" ;
VAL_ 964 NodeStsMTCM_R_LcFA 0 "FALSE" 1 "TRUE" ;
VAL_ 964 NodeStsMTCM_L_LcFA 0 "FALSE" 1 "TRUE" ;
VAL_ 964 NodeStsSBM_CAN_3_LcFA 0 "FALSE" 1 "TRUE" ;
VAL_ 964 NodeStsSAM_RR_LcFA 0 "FALSE" 1 "TRUE" ;
VAL_ 964 NodeStsSAM_RF_LcFA 0 "FALSE" 1 "TRUE" ;
VAL_ 964 NodeStsSAM_LR_LcFA 0 "FALSE" 1 "TRUE" ;
VAL_ 964 NodeStsSAM_LF_LcFA 0 "FALSE" 1 "TRUE" ;
VAL_ 964 NodeStsSADS_LcFA 0 "FALSE" 1 "TRUE" ;
VAL_ 964 NodeStsSRR_RF_LcFA 0 "FALSE" 1 "TRUE" ;
VAL_ 964 NodeStsSRR_LR_CR_LcFA 0 "FALSE" 1 "TRUE" ;
VAL_ 964 NodeStsSRR_LF_LcFA 0 "FALSE" 1 "TRUE" ;
VAL_ 964 NodeStsSIB_LcFA 0 "FALSE" 1 "TRUE" ;
VAL_ 964 NodeStsSDM_LcFA 0 "FALSE" 1 "TRUE" ;
VAL_ 964 NodeStsSCL_LcFA 0 "FALSE" 1 "TRUE" ;
VAL_ 964 NodeStsSBZA_R_LcFA 0 "FALSE" 1 "TRUE" ;
VAL_ 964 NodeStsSBZA_L_LcFA 0 "FALSE" 1 "TRUE" ;
VAL_ 964 NodeStsTCP_CAN_5_LcFA 0 "FALSE" 1 "TRUE" ;
VAL_ 964 NodeStsTCM_CAN_2_LcFA 0 "FALSE" 1 "TRUE" ;
VAL_ 964 NodeStsTCCM_LcFA 0 "FALSE" 1 "TRUE" ;
VAL_ 964 NodeStsSRR_SRR_LcFA 0 "FALSE" 1 "TRUE" ;
VAL_ 964 NodeStsSRR_SLR_LcFA 0 "FALSE" 1 "TRUE" ;
VAL_ 964 NodeStsSRR_RR_LcFA 0 "FALSE" 1 "TRUE" ;
VAL_ 964 NodeStsWCM_LcFA 0 "FALSE" 1 "TRUE" ;
VAL_ 964 NodeStsVPM_LcFA 0 "FALSE" 1 "TRUE" ;
VAL_ 964 NodeStsVLM_LcFA 0 "FALSE" 1 "TRUE" ;
VAL_ 964 NodeStsVKM_LcFA 0 "FALSE" 1 "TRUE" ;
VAL_ 964 NodeStsVICM_CAN_9_LcFA 0 "FALSE" 1 "TRUE" ;
VAL_ 964 NodeStsVICM_CAN_2_LcFA 0 "FALSE" 1 "TRUE" ;
VAL_ 964 NodeStsVCU_CAN_5_LcFA 0 "FALSE" 1 "TRUE" ;
VAL_ 964 NodeStsTIM_LcFA 0 "FALSE" 1 "TRUE" ;
VAL_ 964 NodeStsECP_S2_CAN_2_LcFA 0 "FALSE" 1 "TRUE" ;
VAL_ 964 NodeStsPFCM_LcFA 0 "FALSE" 1 "TRUE" ;
VAL_ 964 NodeStsVDM_CAN_2_LcFA 0 "FALSE" 1 "TRUE" ;
VAL_ 964 NodeStsPCM_CAN_3_LcFA 0 "FALSE" 1 "TRUE" ;
VAL_ 964 NodeStsPCM_CAN_2_LcFA 0 "FALSE" 1 "TRUE" ;
VAL_ 964 NodeStsSDM_AV_LcFA 0 "FALSE" 1 "TRUE" ;
VAL_ 962 NodeStsACP4_MCU_CAN_2_LcFA 0 "FALSE" 1 "TRUE" ;
VAL_ 962 NodeStsACP2_MCU_CAN_8_LcFA 0 "FALSE" 1 "TRUE" ;
VAL_ 962 NodeStsACP2_MCU_CAN_2_LcFA 0 "FALSE" 1 "TRUE" ;
VAL_ 962 NodeStsVECM_CAN_2_LcFA 0 "FALSE" 1 "TRUE" ;
VAL_ 962 NodeStsVDM_CAN_9_LcFA 0 "FALSE" 1 "TRUE" ;
VAL_ 962 NodeStsUVM_CAN_1_LcFA 0 "FALSE" 1 "TRUE" ;
VAL_ 962 NodeStsUPM_LcFA 0 "FALSE" 1 "TRUE" ;
VAL_ 962 NodeStsEPSb_LcFA 0 "FALSE" 1 "TRUE" ;
VAL_ 962 NodeStsSBM_CAN_10_LcFA 0 "FALSE" 1 "TRUE" ;
VAL_ 962 NodeStsVECM_CAN_9_LcFA 0 "FALSE" 1 "TRUE" ;
VAL_ 962 NodeStsECP_S2_CAN_9_LcFA 0 "FALSE" 1 "TRUE" ;
VAL_ 962 NodeStsCSM_AV_CAN_5_LcFA 0 "FALSE" 1 "TRUE" ;
VAL_ 962 NodeStsACP3_MCU_CAN_3_LcFA 0 "FALSE" 1 "TRUE" ;
VAL_ 962 NodeStsACP3_MCU_CAN_8_LcFA 0 "FALSE" 1 "TRUE" ;
VAL_ 962 NodeStsACP3_MCU_CAN_2_LcFA 0 "FALSE" 1 "TRUE" ;
VAL_ 962 NodeStsWCM4_LcFA 0 "FALSE" 1 "TRUE" ;
VAL_ 962 NodeStsWCM3_LcFA 0 "FALSE" 1 "TRUE" ;
VAL_ 962 NodeStsWCM2_LcFA 0 "FALSE" 1 "TRUE" ;
VAL_ 962 NodeStsRSI_CAN_5_LcFA 0 "FALSE" 1 "TRUE" ;
VAL_ 962 NodeStsLIB_48V_LcFA 0 "FALSE" 1 "TRUE" ;
VAL_ 962 NodeStsFPI_CAN_5_LcFA 0 "FALSE" 1 "TRUE" ;
VAL_ 962 NodeStsACP4_MCU_CAN_3_LcFA 0 "FALSE" 1 "TRUE" ;
VAL_ 962 NodeStsACP4_MCU_CAN_8_LcFA 0 "FALSE" 1 "TRUE" ;
VAL_ 962 NodeStsBSM_HEV_CAN_2_LcFA 0 "FALSE" 1 "TRUE" ;
VAL_ 962 NodeStsECP_H3_CAN_2_LcFA 0 "FALSE" 1 "TRUE" ;
VAL_ 962 NodeStsECP_H2_CAN_2_LcFA 0 "FALSE" 1 "TRUE" ;
VAL_ 962 NodeStsECP_H2_CAN_9_LcFA 0 "FALSE" 1 "TRUE" ;
VAL_ 962 NodeStsECP_H1_CAN_9_LcFA 0 "FALSE" 1 "TRUE" ;
VAL_ 962 NodeStsECP_H1_CAN_2_LcFA 0 "FALSE" 1 "TRUE" ;
VAL_ 962 NodeStsBSM_HEV_CAN_9_LcFA 0 "FALSE" 1 "TRUE" ;
VAL_ 962 NodeStsECP_H3_CAN_9_LcFA 0 "FALSE" 1 "TRUE" ;
VAL_ 962 NodeStsSAM_BH_LcFA 0 "FALSE" 1 "TRUE" ;
VAL_ 962 NodeStsPLCM_LcFA 0 "FALSE" 1 "TRUE" ;
VAL_ 962 NodeStsODS_LcFA 0 "FALSE" 1 "TRUE" ;
VAL_ 962 NodeStsODS2_LcFA 0 "FALSE" 1 "TRUE" ;
VAL_ 952 NodeStsEBCM_CAN_3_Prsnt 0 "FALSE" 1 "TRUE" ;
VAL_ 952 NodeStsICCM_CAN_3_Prsnt 0 "FALSE" 1 "TRUE" ;
VAL_ 952 NodeStsARB_Prsnt 0 "FALSE" 1 "TRUE" ;
VAL_ 952 NodeStsVECM_CAN_2_Prsnt 0 "FALSE" 1 "TRUE" ;
VAL_ 952 NodeStsEBCM_AV_CAN_3_Prsnt 0 "FALSE" 1 "TRUE" ;
VAL_ 952 NodeStsSRR_SRR_Prsnt 0 "FALSE" 1 "TRUE" ;
VAL_ 952 NodeStsADIMa_CAN_9_Prsnt 0 "FALSE" 1 "TRUE" ;
VAL_ 952 NodeStsTIM_Prsnt 0 "FALSE" 1 "TRUE" ;
VAL_ 952 NodeStsSDM_AV_Prsnt 0 "FALSE" 1 "TRUE" ;
VAL_ 952 NodeStsEOCM_HCP2_Prsnt 0 "FALSE" 1 "TRUE" ;
VAL_ 952 NodeStsLIB1_Prsnt 0 "FALSE" 1 "TRUE" ;
VAL_ 952 NodeStsELM_Prsnt 0 "FALSE" 1 "TRUE" ;
VAL_ 952 NodeStsMFC_Prsnt 0 "FALSE" 1 "TRUE" ;
VAL_ 952 NodeStsEBCM_CAN_2_Prsnt 0 "FALSE" 1 "TRUE" ;
VAL_ 952 NodeStsEOCM_HCP1_CAN_3_Prsnt 0 "FALSE" 1 "TRUE" ;
VAL_ 952 NodeStsEPSRAa_Prsnt 0 "FALSE" 1 "TRUE" ;
VAL_ 952 NodeStsSADS_Prsnt 0 "FALSE" 1 "TRUE" ;
VAL_ 952 NodeStsSAM_RF_Prsnt 0 "FALSE" 1 "TRUE" ;
VAL_ 952 NodeStsSAM_LF_Prsnt 0 "FALSE" 1 "TRUE" ;
VAL_ 952 NodeStsFCM_Prsnt 0 "FALSE" 1 "TRUE" ;
VAL_ 952 NodeStsSAM_RR_Prsnt 0 "FALSE" 1 "TRUE" ;
VAL_ 952 NodeStsECP_H3_CAN_2_Prsnt 0 "FALSE" 1 "TRUE" ;
VAL_ 952 NodeStsVDM_CAN_9_Prsnt 0 "FALSE" 1 "TRUE" ;
VAL_ 952 NodeStsECP_X1_CAN_2_Prsnt 0 "FALSE" 1 "TRUE" ;
VAL_ 952 NodeStsMRCM_L_Prsnt 0 "FALSE" 1 "TRUE" ;
VAL_ 952 NodeStsBSM_HEV_CAN_9_Prsnt 0 "FALSE" 1 "TRUE" ;
VAL_ 952 NodeStsSBM_CAN_10_Prsnt 0 "FALSE" 1 "TRUE" ;
VAL_ 952 NodeStsFOPM_CAN_2_Prsnt 0 "FALSE" 1 "TRUE" ;
VAL_ 952 NodeStsHUD_CAN_Prsnt 0 "FALSE" 1 "TRUE" ;
VAL_ 952 NodeStsRSI_CAN_5_Prsnt 0 "FALSE" 1 "TRUE" ;
VAL_ 952 NodeStsPTM_Prsnt 0 "FALSE" 1 "TRUE" ;
VAL_ 952 NodeStsBSM_HEV_CAN_2_Prsnt 0 "FALSE" 1 "TRUE" ;
VAL_ 952 NodeStsECP_S2_CAN_9_Prsnt 0 "FALSE" 1 "TRUE" ;
VAL_ 952 NodeStsSBZA_L_Prsnt 0 "FALSE" 1 "TRUE" ;
VAL_ 952 NodeStsMTCM_R_Prsnt 0 "FALSE" 1 "TRUE" ;
VAL_ 952 NodeStsECM_CAN_3_Prsnt 0 "FALSE" 1 "TRUE" ;
VAL_ 952 NodeStsEPSRAb_Prsnt 0 "FALSE" 1 "TRUE" ;
VAL_ 952 NodeStsAMP_Prsnt 0 "FALSE" 1 "TRUE" ;
VAL_ 952 NodeStsRadioLow_Prsnt 0 "FALSE" 1 "TRUE" ;
VAL_ 952 NodeStsFOPM_CAN_3_Prsnt 0 "FALSE" 1 "TRUE" ;
VAL_ 952 NodeStsLIB_48V_Prsnt 0 "FALSE" 1 "TRUE" ;
VAL_ 952 NodeStsAPA_CAN_2_Prsnt 0 "FALSE" 1 "TRUE" ;
VAL_ 952 NodeStsFPI_CAN_5_Prsnt 0 "FALSE" 1 "TRUE" ;
VAL_ 952 NodeStsHDLM_Prsnt 0 "FALSE" 1 "TRUE" ;
VAL_ 952 NodeStsMSM_LR_Prsnt 0 "FALSE" 1 "TRUE" ;
VAL_ 952 NodeStsBSM_MH_Prsnt 0 "FALSE" 1 "TRUE" ;
VAL_ 952 NodeStsECP_H1_CAN_9_Prsnt 0 "FALSE" 1 "TRUE" ;
VAL_ 952 NodeStsPA_Prsnt 0 "FALSE" 1 "TRUE" ;
VAL_ 952 NodeStsSAM_LR_Prsnt 0 "FALSE" 1 "TRUE" ;
VAL_ 952 NodeStsEBCM_AV_CAN_2_Prsnt 0 "FALSE" 1 "TRUE" ;
VAL_ 952 NodeStsADIMa_CAN_3_Prsnt 0 "FALSE" 1 "TRUE" ;
VAL_ 952 NodeStsACP2_MCU_CAN_2_Prsnt 0 "FALSE" 1 "TRUE" ;
VAL_ 952 NodeStsWCM_Prsnt 0 "FALSE" 1 "TRUE" ;
VAL_ 952 NodeStsECP_MC_Prsnt 0 "FALSE" 1 "TRUE" ;
VAL_ 952 NodeStsADIMb_CAN_10_Prsnt 0 "FALSE" 1 "TRUE" ;
VAL_ 952 NodeStsMSB2_Prsnt 0 "FALSE" 1 "TRUE" ;
VAL_ 952 NodeStsMSM_P_Prsnt 0 "FALSE" 1 "TRUE" ;
VAL_ 952 NodeStsAHL_AFL_CAN_2_Prsnt 0 "FALSE" 1 "TRUE" ;
VAL_ 952 NodeStsPCM_CAN_2_Prsnt 0 "FALSE" 1 "TRUE" ;
VAL_ 952 NodeStsEPS_Prsnt 0 "FALSE" 1 "TRUE" ;
VAL_ 952 NodeStsACP4_MCU_CAN_3_Prsnt 0 "FALSE" 1 "TRUE" ;
VAL_ 953 NodeStsPDR_Prsnt 0 "FALSE" 1 "TRUE" ;
VAL_ 953 NodeStsECP_X1_CAN_3_Prsnt 0 "FALSE" 1 "TRUE" ;
VAL_ 953 NodeStsRDCM_Prsnt 0 "FALSE" 1 "TRUE" ;
VAL_ 953 NodeStsECP_H2_CAN_2_Prsnt 0 "FALSE" 1 "TRUE" ;
VAL_ 953 NodeStsBCM_Prsnt 0 "FALSE" 1 "TRUE" ;
VAL_ 953 NodeStsAPA_CAN_1_Prsnt 0 "FALSE" 1 "TRUE" ;
VAL_ 953 NodeStsMTCM_L_Prsnt 0 "FALSE" 1 "TRUE" ;
VAL_ 953 NodeStsADIMa_CAN_10_Prsnt 0 "FALSE" 1 "TRUE" ;
VAL_ 953 NodeStsPCM_CAN_3_Prsnt 0 "FALSE" 1 "TRUE" ;
VAL_ 953 NodeStsACP3_MCU_CAN_3_Prsnt 0 "FALSE" 1 "TRUE" ;
VAL_ 953 NodeStsWCM2_Prsnt 0 "FALSE" 1 "TRUE" ;
VAL_ 953 NodeStsICS_Info_Prsnt 0 "FALSE" 1 "TRUE" ;
VAL_ 953 NodeStsLRR_Prsnt 0 "FALSE" 1 "TRUE" ;
VAL_ 953 NodeStsWCM4_Prsnt 0 "FALSE" 1 "TRUE" ;
VAL_ 953 NodeStsBSM_CAN_2_Prsnt 0 "FALSE" 1 "TRUE" ;
VAL_ 953 NodeStsEOCM_CAN_2_Prsnt 0 "FALSE" 1 "TRUE" ;
VAL_ 953 NodeStsWCM3_Prsnt 0 "FALSE" 1 "TRUE" ;
VAL_ 953 NodeStsVKM_Prsnt 0 "FALSE" 1 "TRUE" ;
VAL_ 953 NodeStsSDM_Prsnt 0 "FALSE" 1 "TRUE" ;
VAL_ 953 NodeStsSIB_Prsnt 0 "FALSE" 1 "TRUE" ;
VAL_ 953 NodeStsHVAC_FP_F_Prsnt 0 "FALSE" 1 "TRUE" ;
VAL_ 953 NodeStsDEFC_Prsnt 0 "FALSE" 1 "TRUE" ;
VAL_ 953 NodeStsVICM_CAN_2_Prsnt 0 "FALSE" 1 "TRUE" ;
VAL_ 953 NodeStsSCL_Prsnt 0 "FALSE" 1 "TRUE" ;
VAL_ 953 NodeStsACP2_MCU_CAN_8_Prsnt 0 "FALSE" 1 "TRUE" ;
VAL_ 953 NodeStsEPS_1_Prsnt 0 "FALSE" 1 "TRUE" ;
VAL_ 953 NodeStsFCM_LC_Prsnt 0 "FALSE" 1 "TRUE" ;
VAL_ 953 NodeStsIPC_CAN_5_Prsnt 0 "FALSE" 1 "TRUE" ;
VAL_ 953 NodeStsEOCM_HCP1_CAN_2_Prsnt 0 "FALSE" 1 "TRUE" ;
VAL_ 953 NodeStsTCCM_Prsnt 0 "FALSE" 1 "TRUE" ;
VAL_ 953 NodeStsSBM_CAN_3_Prsnt 0 "FALSE" 1 "TRUE" ;
VAL_ 953 NodeStsARS_Prsnt 0 "FALSE" 1 "TRUE" ;
VAL_ 953 NodeStsEPSb_Prsnt 0 "FALSE" 1 "TRUE" ;
VAL_ 953 NodeStsBSM_CAN_3_Prsnt 0 "FALSE" 1 "TRUE" ;
VAL_ 953 NodeStsVCU_CAN_5_Prsnt 0 "FALSE" 1 "TRUE" ;
VAL_ 953 NodeStsAHS_Prsnt 0 "FALSE" 1 "TRUE" ;
VAL_ 953 NodeStsCSM_CAN_5_Prsnt 0 "FALSE" 1 "TRUE" ;
VAL_ 953 NodeStsVICM_CAN_9_Prsnt 0 "FALSE" 1 "TRUE" ;
VAL_ 953 NodeStsSRR_LF_Prsnt 0 "FALSE" 1 "TRUE" ;
VAL_ 953 NodeStsTCM_CAN_2_Prsnt 0 "FALSE" 1 "TRUE" ;
VAL_ 953 NodeStsVPM_Prsnt 0 "FALSE" 1 "TRUE" ;
VAL_ 953 NodeStsSRR_RF_Prsnt 0 "FALSE" 1 "TRUE" ;
VAL_ 953 NodeStsACP3_MCU_CAN_8_Prsnt 0 "FALSE" 1 "TRUE" ;
VAL_ 953 NodeStsECP_E_CAN_2_Prsnt 0 "FALSE" 1 "TRUE" ;
VAL_ 953 NodeStsSBZA_R_Prsnt 0 "FALSE" 1 "TRUE" ;
VAL_ 953 NodeStsVLM_Prsnt 0 "FALSE" 1 "TRUE" ;
VAL_ 953 NodeStsADIMb_CAN_9_Prsnt 0 "FALSE" 1 "TRUE" ;
VAL_ 953 NodeStsUVM_CAN_1_Prsnt 0 "FALSE" 1 "TRUE" ;
VAL_ 953 NodeStsALC_Prsnt 0 "FALSE" 1 "TRUE" ;
VAL_ 953 NodeStsSRR_LR_CR_Prsnt 0 "FALSE" 1 "TRUE" ;
VAL_ 953 NodeStsDCM_Prsnt 0 "FALSE" 1 "TRUE" ;
VAL_ 953 NodeStsNVM_Prsnt 0 "FALSE" 1 "TRUE" ;
VAL_ 953 NodeStsDMS_Prsnt 0 "FALSE" 1 "TRUE" ;
VAL_ 953 NodeStsTCP_CAN_5_Prsnt 0 "FALSE" 1 "TRUE" ;
VAL_ 953 NodeStsECM_CAN_2_Prsnt 0 "FALSE" 1 "TRUE" ;
VAL_ 953 NodeStsADIMb_CAN_2_Prsnt 0 "FALSE" 1 "TRUE" ;
VAL_ 953 NodeStsSRR_RR_Prsnt 0 "FALSE" 1 "TRUE" ;
VAL_ 953 NodeStsADIMa_CAN_2_Prsnt 0 "FALSE" 1 "TRUE" ;
VAL_ 953 NodeStsHVAC_FP_R_Prsnt 0 "FALSE" 1 "TRUE" ;
VAL_ 953 NodeStsSRR_SLR_Prsnt 0 "FALSE" 1 "TRUE" ;
VAL_ 953 NodeStsEOCM_HCP1_CAN_8_Prsnt 0 "FALSE" 1 "TRUE" ;
VAL_ 953 NodeStsECP_S2_CAN_2_Prsnt 0 "FALSE" 1 "TRUE" ;
VAL_ 953 NodeStsECP_S_CAN_9_Prsnt 0 "FALSE" 1 "TRUE" ;
VAL_ 954 NodeStsUPM_Prsnt 0 "FALSE" 1 "TRUE" ;
VAL_ 954 NodeStsMSM_RR_Prsnt 0 "FALSE" 1 "TRUE" ;
VAL_ 954 NodeStsEOCM_CAN_8_Prsnt 0 "FALSE" 1 "TRUE" ;
VAL_ 954 NodeStsMSB1_Prsnt 0 "FALSE" 1 "TRUE" ;
VAL_ 954 NodeStsECP_H3_CAN_9_Prsnt 0 "FALSE" 1 "TRUE" ;
VAL_ 954 NodeStsECP_S_CAN_2_Prsnt 0 "FALSE" 1 "TRUE" ;
VAL_ 954 NodeStsECP_E_CAN_9_Prsnt 0 "FALSE" 1 "TRUE" ;
VAL_ 954 NodeStsAOS_Prsnt 0 "FALSE" 1 "TRUE" ;
VAL_ 954 NodeStsECP_H2_CAN_9_Prsnt 0 "FALSE" 1 "TRUE" ;
VAL_ 954 NodeStsCSM_AV_CAN_5_Prsnt 0 "FALSE" 1 "TRUE" ;
VAL_ 954 NodeStsMSM_D_Prsnt 0 "FALSE" 1 "TRUE" ;
VAL_ 954 NodeStsACP3_MCU_CAN_2_Prsnt 0 "FALSE" 1 "TRUE" ;
VAL_ 954 NodeStsADIMb_CAN_3_Prsnt 0 "FALSE" 1 "TRUE" ;
VAL_ 954 NodeStsECP_H1_CAN_2_Prsnt 0 "FALSE" 1 "TRUE" ;
VAL_ 954 NodeStsPFCM_Prsnt 0 "FALSE" 1 "TRUE" ;
VAL_ 954 NodeStsVECM_CAN_9_Prsnt 0 "FALSE" 1 "TRUE" ;
VAL_ 954 NodeStsSAM_BH_Prsnt 0 "FALSE" 1 "TRUE" ;
VAL_ 954 NodeStsODS2_Prsnt 0 "FALSE" 1 "TRUE" ;
VAL_ 954 NodeStsODS_Prsnt 0 "FALSE" 1 "TRUE" ;
VAL_ 954 NodeStsACP4_MCU_CAN_2_Prsnt 0 "FALSE" 1 "TRUE" ;
VAL_ 954 NodeStsVDM_CAN_2_Prsnt 0 "FALSE" 1 "TRUE" ;
VAL_ 954 NodeStsEOCM_CAN_3_Prsnt 0 "FALSE" 1 "TRUE" ;
VAL_ 954 NodeStsACP4_MCU_CAN_8_Prsnt 0 "FALSE" 1 "TRUE" ;
VAL_ 954 NodeStsMRCM_R_Prsnt 0 "FALSE" 1 "TRUE" ;
VAL_ 954 NodeStsPLCM_Prsnt 0 "FALSE" 1 "TRUE" ;
VAL_ 1322 FrtPsngrAirbagDsblVisIndCmd 0 "On" 1 "Off" 2 "Flash" ;
VAL_ 1322 ORIP_EnvModPrsntRsp1Auth 0 "FALSE" 1 "TRUE" ;
VAL_ 1322 ORIP_DrvrStBltStsAuth_Inv 0 "FALSE" 1 "TRUE" ;
VAL_ 1322 ORIP_DrvrStBltStsAuth 0 "Unknown" 1 "UnFastened" 2 "Fastened" ;
VAL_ 1322 RstrntSysFltPrsnt 0 "FALSE" 1 "TRUE" ;
VAL_ 1322 FrtPsngrAirbagEnblVisIndCmd 0 "On" 1 "Off" 2 "Flash" ;
VAL_ 1320 PCIP_HzrdLgtsOnReqdAuth 0 "FALSE" 1 "TRUE" ;
VAL_ 1320 PCIP_HybVehHiVltgDsblReqdAuth 0 "FALSE" 1 "TRUE" ;
VAL_ 1320 PCIP_HVCrshImpSnsSysDsbldAuth 0 "FALSE" 1 "TRUE" ;
VAL_ 1320 PCIP_HVACBlwDsblReqdAuth 0 "FALSE" 1 "TRUE" ;
VAL_ 1320 PCIP_FuelCutOffReqdAuth 0 "FALSE" 1 "TRUE" ;
VAL_ 1320 PCIP_DrUnlckReqdAuth 0 "FALSE" 1 "TRUE" ;
VAL_ 1320 PCIP_CruzCtlDsblReqdAuth 0 "FALSE" 1 "TRUE" ;
VAL_ 1320 PCIP_BrkActReqdAuth 0 "FALSE" 1 "TRUE" ;
VAL_ 1320 PCIP_NftnFrtImpPrtnsrSevAchAuth 0 "FALSE" 1 "TRUE" ;
VAL_ 1320 PCIP_MemStRclDsblReqdAuth 0 "FALSE" 1 "TRUE" ;
VAL_ 1320 PCIP_IntrLgtOnReqdAuth 0 "FALSE" 1 "TRUE" ;
VAL_ 1320 PCIP_NtfnLtSdSevAchvdAuth 0 "FALSE" 1 "TRUE" ;
VAL_ 1320 PCIP_NtfnFrtImpStg2SevAchvdAuth 0 "FALSE" 1 "TRUE" ;
VAL_ 1320 PCIP_NtfnFrtImpStg1SevAchvdAuth 0 "FALSE" 1 "TRUE" ;
VAL_ 1320 PCIP_NtfnEvntStsAuth 0 "No Event" 1 "Near Deploy Event" 2 "Deployment Event" ;
VAL_ 1320 PCIP_eCallReqdAuth 0 "FALSE" 1 "TRUE" ;
VAL_ 1320 PCIP_NtfnRtSdSevAchvdAuth 0 "FALSE" 1 "TRUE" ;
VAL_ 1320 PCIP_NtfnRrImpSevAchvdAuth 0 "FALSE" 1 "TRUE" ;
VAL_ 1320 PCIP_NtfnRlOvrSevAchvdAuth 0 "FALSE" 1 "TRUE" ;
VAL_ 1320 PCIP_NtfnPedtrnPrtctnSevAchAuth 0 "FALSE" 1 "TRUE" ;
VAL_ 870 PSIP_StrgAsstRdcdLvl3IndOnAuth 0 "FALSE" 1 "TRUE" ;
VAL_ 870 PSIP_StrgAsstRdcdLvl2IndOnAuth 0 "FALSE" 1 "TRUE" ;
VAL_ 870 PSIP_StrgAsstRdcdIndOnAuth 0 "FALSE" 1 "TRUE" ;
VAL_ 870 PSIP_PwrStrgIndOnAuth 0 "FALSE" 1 "TRUE" ;
VAL_ 606 RPPSDBG2P_CldrYrAuth_Inv 0 "FALSE" 1 "TRUE" ;
VAL_ 606 RPPSDBG2P_ElvtnAuth_Inv 0 "FALSE" 1 "TRUE" ;
VAL_ 606 RPPSDBG2P_LngAuth_Inv 0 "FALSE" 1 "TRUE" ;
VAL_ 605 RPPSDBG3P_LocUsblAuth_Inv 0 "FALSE" 1 "TRUE" ;
VAL_ 605 RPPSDBG3P_LocUsblAuth 0 "FALSE" 1 "TRUE" ;
VAL_ 605 RPPSDBG3P_LatAuth_Inv 0 "FALSE" 1 "TRUE" ;
VAL_ 605 RPPSDBG3P_TmOfDyAuth_Inv 0 "FALSE" 1 "TRUE" ;
VAL_ 604 RPPSDBG4P_2DAbsPsErrEstAuth_Inv 0 "FALSE" 1 "TRUE" ;
VAL_ 604 RPPSDBG4P_AbsHdgErrEstAuth_Inv 0 "FALSE" 1 "TRUE" ;
VAL_ 604 RPPSDBG4P_CldrDyAuth_Inv 0 "FALSE" 1 "TRUE" ;
VAL_ 604 RPPSDBG4P_SigAcqTmAuth_Inv 0 "FALSE" 1 "TRUE" ;
VAL_ 607 RPPSDBG1P_HdgAuth_Inv 0 "FALSE" 1 "TRUE" ;
VAL_ 603 RPPSDBG5P_GPSModeAuth_Inv 0 "FALSE" 1 "TRUE" ;
VAL_ 603 RPPSDBG5P_GPSModeAuth 0 "GNSS Standalone" 1 "GNSS and SBAS" 2 "GNSS and RTX" 3 "GNSS and DR" 4 "GNSS and SBAS and DR" 5 "GNSS and RTX and DR" 6 "DR ONLY" 7 "GNSS and RTX and DR and MM" ;
VAL_ 603 RPPSDBG5P_LwrGblTmStmAuth_Inv 0 "FALSE" 1 "TRUE" ;
VAL_ 1150 VirtKeyDrvrMblDevMemIdfr 0 "Unknown" 1 "Mobile Device Identifier 1" 2 "Mobile Device Identifier 2" 3 "Mobile Device Identifier 3" 4 "Mobile Device Identifier 4" 5 "Mobile Device Identifier 5" 6 "Mobile Device Identifier 6" 7 "Mobile Device Identifier 7" 8 "Mobile Device Identifier 8" 9 "Mobile Device Identifier 9" 10 "Mobile Device Identifier 10" 11 "Mobile Device Identifier 11" 12 "Mobile Device Identifier 12" 13 "Mobile Device Identifier 13" 14 "Mobile Device Identifier 14" 15 "Mobile Device Identifier 15" ;
VAL_ 1150 VirtKeyMblDevRtEntAllwd 0 "FALSE" 1 "TRUE" ;
VAL_ 1150 VirtKeyMblDevRrCmptAccssAllwd 0 "FALSE" 1 "TRUE" ;
VAL_ 1150 VirtKeyMblDevLtEntAllwd 0 "FALSE" 1 "TRUE" ;
VAL_ 1150 VirtKeyMblDevFrtCmptAccssAllwd 0 "FALSE" 1 "TRUE" ;
VAL_ 1150 VirtKeyWlcmZnMblDevPrsnt 0 "FALSE" 1 "TRUE" ;
VAL_ 1149 VirtKeyAllDrLckReqd 0 "FALSE" 1 "TRUE" ;
VAL_ 1149 VirtKeyPncReq 0 "No Request" 1 "Activate" 2 "Cancel" ;
VAL_ 1149 VirtKeyFobAvlReq 0 "No Request" 1 "Enable Fobs" 2 "Disable Fobs" ;
VAL_ 1149 VirtKeyRmtLctrReq 0 "No Request" 1 "Activate Low" 2 "Activate Medium" 3 "Activate High" 4 "Cancel" ;
VAL_ 1149 SRPCrsFrtInSftBtnMblDevSts 0 "Not Pressed" 1 "Pressed" ;
VAL_ 1149 SRPCrsBkInSftBtnMblDevSts 0 "Not Pressed" 1 "Pressed" ;
VAL_ 1149 VirtKeyRrClsrUnlckReqd 0 "FALSE" 1 "TRUE" ;
VAL_ 1149 VirtKeyRrClsrLckReqd 0 "FALSE" 1 "TRUE" ;
VAL_ 1149 VirtKeyFrtClsrUnlckReqd 0 "FALSE" 1 "TRUE" ;
VAL_ 1149 VirtKeyFrtClsrLckReqd 0 "FALSE" 1 "TRUE" ;
VAL_ 1149 VirtKeyDrvrDrUnlckReqd 0 "FALSE" 1 "TRUE" ;
VAL_ 1149 VirtKeyAllDrUnlckReqd 0 "FALSE" 1 "TRUE" ;
VAL_ 1149 SRPExplrModeSftBtnMblDevSts 0 "Not Pressed" 1 "Pressed" ;
VAL_ 1149 SRPSrchingSftBtnMblDevSts 0 "Not Pressed" 1 "Pressed" ;
VAL_ 1149 SRPRtSftBtnMblDevSts 0 "Not Pressed" 1 "Pressed" ;
VAL_ 1149 SRPPrlllPrkSftBtnMblDevSts 0 "Not Pressed" 1 "Pressed" ;
VAL_ 1149 SRPLtSftBtnMblDevSts 0 "Not Pressed" 1 "Pressed" ;
VAL_ 1149 SRPExtPrkSftBtnMblDevSts 0 "Not Pressed" 1 "Pressed" ;
VAL_ 586 VirtKeyPwrTopCtlReqrMblDevIdfr 0 "Unknown" 1 "Mobile Device Identifier 1" 2 "Mobile Device Identifier 2" 3 "Mobile Device Identifier 3" 4 "Mobile Device Identifier 4" 5 "Mobile Device Identifier 5" 6 "Mobile Device Identifier 6" 7 "Mobile Device Identifier 7" 8 "Mobile Device Identifier 8" 9 "Mobile Device Identifier 9" 10 "Mobile Device Identifier 10" 11 "Mobile Device Identifier 11" 12 "Mobile Device Identifier 12" 13 "Mobile Device Identifier 13" 14 "Mobile Device Identifier 14" 15 "Mobile Device Identifier 15" ;
VAL_ 586 VirtKeyPwrTopCtlReq 0 "No Request" 1 "Open" 2 "Close" 3 "Stop" 4 "Pause" ;
VAL_ 586 VirtKeyPwrRrClsrCtlReq 0 "No Request" 1 "Start" 2 "Stop" 3 "Open" 4 "Close" ;
VAL_ 586 VirtKeyFrtClsrCtlReq 0 "No Request" 1 "Start" 2 "Stop" 3 "Release" 4 "Open" 5 "Close" ;
VAL_ 586 VirtKeyWndCtlReq 0 "No Request" 1 "Open Fully" 2 "Vent" 3 "Close Fully" ;
VAL_ 586 VirtKeyVehCbnACReq 0 "No Request" 1 "Activate" 2 "Cancel" ;
VAL_ 586 VirtKeySnrfCtlReq 0 "No Request" 1 "Open Fully" 2 "Vent" 3 "Close Fully" ;
VAL_ 586 SRPMblDevDctvBtnSts 0 "Not Pressed" 1 "Pressed" ;
VAL_ 586 VirtKeyVehCbnACTempLvlReqActv 0 "FALSE" 1 "TRUE" ;
VAL_ 586 VirtKeyRrClsrRelReqd 0 "FALSE" 1 "TRUE" ;
VAL_ 1148 HiVltgBatThrmlRnwyIndReq 0 "No Indication" 1 "Low" 2 "Medium" 3 "High" ;
VAL_ 1148 CbnPrcndtngSchReq 0 "No Action" 1 "Inactive" 2 "Compute Request" 3 "Active" ;
VAL_ 1148 CbnPrcndtngSchTempLvlReqAtv 0 "FALSE" 1 "TRUE" ;
VAL_ 1148 CustUsblSOCAuth_Inv 0 "FALSE" 1 "TRUE" ;
VAL_ 1148 CustUsblSOCAuth_DuD 0 "FALSE" 1 "TRUE" ;
VAL_ 1148 HiVltgBatOutOfEngyIndReqAuth 0 "No Action" 1 "Charge Soon" 2 "Charge Now" 3 "Out of Energy" 4 "Start Engine" ;
VAL_ 635 EPBSP_ElecPrkBrkAvlStsAuth 0 "Unavailable" 1 "Available" 2 "Failed" ;
VAL_ 635 EPBSP_ElecPrkBrkApplStsAuth 0 "Unknown" 1 "Applied" 2 "Released" 3 "Dynamic Apply" 4 "In-Progress" ;
VAL_ 635 EPBSP_EPBSysBrkLgtsReqdAuth 0 "FALSE" 1 "TRUE" ;
VAL_ 635 EPBSP_BrkSysBrkLgtsReqdAuth 0 "FALSE" 1 "TRUE" ;
VAL_ 635 DMCP_EnvIdRsp2Auth 0 "FALSE" 1 "TRUE" ;
VAL_ 635 TBIP_TrlrBrkDsbldIndOnAuth 0 "FALSE" 1 "TRUE" ;
VAL_ 635 TBIP_ServTrlrBrkgSysIndOnAuth 0 "FALSE" 1 "TRUE" ;
VAL_ 635 TBIP_CkTrlrIndOnAuth 0 "FALSE" 1 "TRUE" ;
VAL_ 635 EPBSP_TrlrBrkgSysBrkLgtsRqdAuth 0 "FALSE" 1 "TRUE" ;
VAL_ 635 TBIP_TrlrWrgFltIndOnAuth 0 "FALSE" 1 "TRUE" ;
VAL_ 635 TBIP_TrlrBrkgGainSetIndOnAuth 0 "FALSE" 1 "TRUE" ;
VAL_ 635 BrkSysActvHldActv 0 "FALSE" 1 "TRUE" ;
VAL_ 635 BrkSysVehHldReqShfPrk 0 "FALSE" 1 "TRUE" ;
VAL_ 635 ElecPrkBrkMnPriPerfRdcd 0 "FALSE" 1 "TRUE" ;
VAL_ 635 TrlrBrkgRdcdIndOn 0 "FALSE" 1 "TRUE" ;
VAL_ 635 TrlrBrkgHldLstKnwnGainIndOn 0 "FALSE" 1 "TRUE" ;
VAL_ 879 EGI3P_CnvtTpSpLimRspTypAuth 0 "Inactive" 1 "Faulted" 2 "Safety_woBrake" 3 "Safety_wBrake" 4 "OBD" 5 "nonOBD" 6 "Legislated" ;
VAL_ 879 PSP_PrkNeutSwStatAuth_Inv 0 "FALSE" 1 "TRUE" ;
VAL_ 879 PSP_PrkNeutSwStatAuth 0 "Park/Neutral" 1 "Not Park/Neutral" ;
VAL_ 879 PSP_EngRnngAuth 0 "FALSE" 1 "TRUE" ;
VAL_ 879 PSP_ClchBtmTrvlAchvdAuth_Inv 0 "FALSE" 1 "TRUE" ;
VAL_ 879 PSP_ClchBtmTrvlAchvdAuth 0 "FALSE" 1 "TRUE" ;
VAL_ 879 PSP_VehTheftImbChlgRespStsAuth 0 "Undetermined" 1 "Pass" 2 "Fail" ;
VAL_ 879 PSP_RmtVehStrtEngRnngAuth 0 "FALSE" 1 "TRUE" ;
VAL_ 879 PSP_PwrtrnCrnkAbrtdAuth 0 "FALSE" 1 "TRUE" ;
VAL_ 879 PSP_PrplSysStlActvAuth 0 "FALSE" 1 "TRUE" ;
VAL_ 879 PSP_PrplSysActvAuth 0 "FALSE" 1 "TRUE" ;
VAL_ 879 PrplBrkThrotOvrrdReqd 0 "FALSE" 1 "TRUE" ;
VAL_ 1117 APALtSftBtnReq 0 "Hidden" 1 "Disabled" 2 "Enabled" 3 "Highlighted" ;
VAL_ 1117 APAExtPrkSftBtnReq 0 "Hidden" 1 "Disabled" 2 "Enabled" 3 "Highlighted" ;
VAL_ 1117 APACrsFrtInSftBtnReq 0 "Hidden" 1 "Disabled" 2 "Enabled" 3 "Highlighted" ;
VAL_ 1117 APACrsBkInSftBtnReq 0 "Hidden" 1 "Disabled" 2 "Enabled" 3 "Highlighted" ;
VAL_ 1117 APAExplrModeSftBtnReq 0 "Hidden" 1 "Disabled" 2 "Enabled" 3 "Highlighted" ;
VAL_ 1117 APASrchingSftBtnReq 0 "Hidden" 1 "Disabled" 2 "Enabled" 3 "Highlighted" ;
VAL_ 1117 APARtSftBtnReq 0 "Hidden" 1 "Disabled" 2 "Enabled" 3 "Highlighted" ;
VAL_ 1117 APAPrllPrkSftBtnReq 0 "Hidden" 1 "Disabled" 2 "Enabled" 3 "Highlighted" ;
VAL_ 1108 FltDrvrActvRmtCstChgSetReq 0 "No Action" 1 "Off" 2 "On" ;
VAL_ 1108 TnDrvrSpdLimRmtCstChgSetReq 0 "No Action" 1 "Off" 2 "On" ;
VAL_ 1108 TnDrvrActvRmtCstChgSetReq 0 "No Action" 1 "Off" 2 "On" ;
VAL_ 1108 VSEMOpRmtCtlReq 0 "No Request" 1 "Initiate SOC Extension" 2 "Initiate Time Extension" 3 "End Extension" 4 "Request to Update Extension" 5 "Request to Update Extension Cancelled" ;
VAL_ 1105 SCAOOAByVirtKeyLFCstChgSetReq 0 "No Action" 1 "Off" 2 "On" ;
VAL_ 1105 SCAOOAByKeyFobRFCstChgSetReq 0 "No Action" 1 "Off" 2 "On" ;
VAL_ 1105 SCAOOAByKeyFobLFCstChgSetReq 0 "No Action" 1 "Off" 2 "On" ;
VAL_ 1105 SCAPwrDrMtnLRVirtCtlFrtReq 0 "No Action" 1 "Open" 2 "Close" 3 "Stop" 4 "Partial Open" ;
VAL_ 1105 SCAPwrDrMtnLFVirtCtlReq 0 "No Action" 1 "Open" 2 "Close" 3 "Stop" 4 "Partial Open" ;
VAL_ 1105 SCAOOAByVirtKeyRFCstChgSetReq 0 "No Action" 1 "Off" 2 "On" ;
VAL_ 1105 SCAPwrDrMtnRFVirtCtlReq 0 "No Action" 1 "Open" 2 "Close" 3 "Stop" 4 "Partial Open" ;
VAL_ 1105 SCAPwrDrMtnLRVirtCtlRrReq 0 "No Action" 1 "Open" 2 "Close" 3 "Stop" 4 "Partial Open" ;
VAL_ 1105 SCAOOAExclnZnActv 0 "FALSE" 1 "TRUE" ;
VAL_ 1105 SCAPwrDrMtnRRVirtCtlRrReq 0 "No Action" 1 "Open" 2 "Close" 3 "Stop" 4 "Partial Open" ;
VAL_ 1105 SCAPwrDrMtnRRVirtCtlFrtReq 0 "No Action" 1 "Open" 2 "Close" 3 "Stop" 4 "Partial Open" ;
VAL_ 1104 DMBlkhdDrUnltchPrkCstChgSetReq 0 "No Action" 1 "Off" 2 "On" ;
VAL_ 1104 DMBlkhdDrUnlckPrkCstChgSetReq 0 "No Action" 1 "Off" 2 "On" ;
VAL_ 1104 DMBlkhdDrOpnVehOffCstChgSetReq 0 "No Action" 1 "Off" 2 "On" ;
VAL_ 1104 DMPDDOBlkhdDrOpnLFCstChgSetReq 0 "No Action" 1 "Off" 2 "On" ;
VAL_ 1104 DMDrvrDrUnlckPrkCstChgSetReq 0 "No Action" 1 "Off" 2 "On" ;
VAL_ 1104 DMCrbsdDrUnlckPrkCstChgSetReq 0 "No Action" 1 "Off" 2 "On" ;
VAL_ 1104 RrClsrAccssVirtCtlReq 0 "No Action" 1 "Open" 2 "Close" 3 "Stop" ;
VAL_ 1104 FrtClsrAccssVirtCtlReq 0 "No Action" 1 "Open" 2 "Close" 3 "Stop" ;
VAL_ 1104 DMPDDOBlkhdDrOpnRFCstChgSetReq 0 "No Action" 1 "Off" 2 "On" ;
VAL_ 1104 SCAPwrDrUnlckAllVirtCtlRrReq 0 "No Action" 1 "UnLock All" ;
VAL_ 1104 SCAPwrDrUnlckAllVirtCtlFrtReq 0 "No Action" 1 "UnLock All" ;
VAL_ 1104 SCAPwrDrLckAllVirtCtlRrReq 0 "No Action" 1 "Lock All" ;
VAL_ 1104 SCAPwrDrLckAllVirtCtlFrtReq 0 "No Action" 1 "Lock All" ;
VAL_ 1104 RstrCstDfltReqdAuth 0 "FALSE" 1 "TRUE" ;
VAL_ 1103 SCAPwrDrMtnLRVirtKeyReq 0 "No Action" 1 "Open" 2 "Close" 3 "Stop" 4 "Partial Open" ;
VAL_ 1103 SCAPwrDrMtnLFVirtKeyReqSrc 0 "None" 1 "Button Press" 2 "Approach" ;
VAL_ 1103 SCAPwrDrMtnLFVirtKeyReq 0 "No Action" 1 "Open" 2 "Close" 3 "Stop" 4 "Partial Open" ;
VAL_ 1103 SCAPwrDrMtnRFVirtKeyReqSrc 0 "None" 1 "Button Press" 2 "Approach" ;
VAL_ 1103 SCAPwrDrMtnRFVirtKeyReq 0 "No Action" 1 "Open" 2 "Close" 3 "Stop" 4 "Partial Open" ;
VAL_ 1103 SCAPwrDrMtnLRVirtKeyReqSrc 0 "None" 1 "Button Press" 2 "Approach" ;
VAL_ 1103 SCAPwrDrMtnRRVirtKeyReqSrc 0 "None" 1 "Button Press" 2 "Approach" ;
VAL_ 1103 SCAPwrDrMtnRRVirtKeyReq 0 "No Action" 1 "Open" 2 "Close" 3 "Stop" 4 "Partial Open" ;
VAL_ 1103 SCAOOAShrtRngSysOneTmExclnActvd 0 "FALSE" 1 "TRUE" ;
